VERSION "canboat-NMEA2000-curated"

NS_ :

BS_:

BU_: Vector__XXX
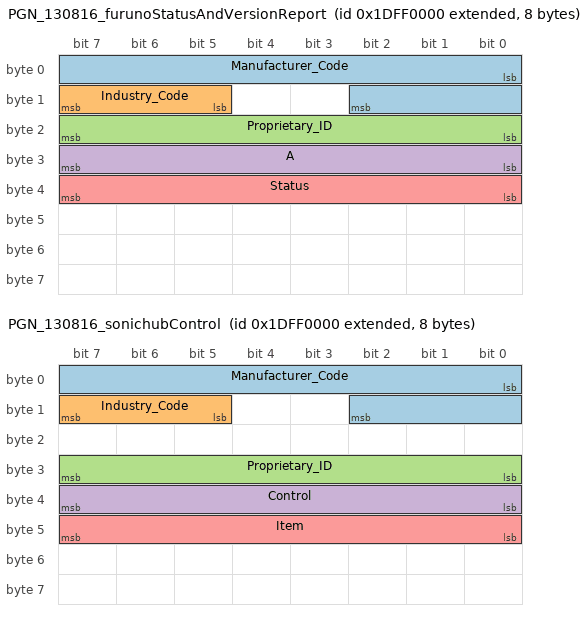
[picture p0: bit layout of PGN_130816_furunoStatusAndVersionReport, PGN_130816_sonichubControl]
BO_ 2650734592 PGN_130816_furunoStatusAndVersionReport: 8 Vector__XXX
 SG_ Manufacturer_Code : 0|11@1+ (1.0,0) [0|2047] "" Vector__XXX
 SG_ Industry_Code : 13|3@1+ (1.0,0) [0|7] "" Vector__XXX
 SG_ Proprietary_ID : 16|8@1+ (1.0,0) [0|255] "" Vector__XXX
 SG_ A : 24|8@1+ (1.0,0) [0|255] "" Vector__XXX
 SG_ Status : 32|8@1+ (1.0,0) [0|255] "" Vector__XXX

BO_ 2650734592 PGN_130816_simradTextMessage: 41 Vector__XXX
 SG_ Manufacturer_Code : 0|11@1+ (1.0,0) [0|2047] "" Vector__XXX
 SG_ Industry_Code : 13|3@1+ (1.0,0) [0|7] "" Vector__XXX
 SG_ Proprietary_ID : 24|8@1+ (1.0,0) [0|255] "" Vector__XXX
 SG_ A : 32|8@1+ (1.0,0) [0|255] "" Vector__XXX
 SG_ B : 40|8@1+ (1.0,0) [0|255] "" Vector__XXX
 SG_ C : 48|8@1+ (1.0,0) [0|255] "" Vector__XXX
 SG_ SID : 56|8@1+ (1.0,0) [0|255] "" Vector__XXX
 SG_ Prio : 64|8@1+ (1.0,0) [0|255] "" Vector__XXX
 SG_ Text : 72|256@1+ (1.0,0) [0|115792089237316195423570985008687907853269984665640564039457584007913129639935] "" Vector__XXX

BO_ 2650734592 PGN_130816_sonichubAlbum: 41 Vector__XXX
 SG_ Manufacturer_Code : 0|11@1+ (1.0,0) [0|2047] "" Vector__XXX
 SG_ Industry_Code : 13|3@1+ (1.0,0) [0|7] "" Vector__XXX
 SG_ Proprietary_ID : 24|8@1+ (1.0,0) [0|255] "" Vector__XXX
 SG_ Control : 32|8@1+ (1.0,0) [0|255] "" Vector__XXX
 SG_ Item : 40|32@1+ (1.0,0) [0|4294967295] "" Vector__XXX
 SG_ Text : 72|256@1+ (1.0,0) [0|115792089237316195423570985008687907853269984665640564039457584007913129639935] "" Vector__XXX

BO_ 2650734592 PGN_130816_sonichubAmRadio: 43 Vector__XXX
 SG_ Manufacturer_Code : 0|11@1+ (1.0,0) [0|2047] "" Vector__XXX
 SG_ Industry_Code : 13|3@1+ (1.0,0) [0|7] "" Vector__XXX
 SG_ Proprietary_ID : 24|8@1+ (1.0,0) [0|255] "" Vector__XXX
 SG_ Control : 32|8@1+ (1.0,0) [0|255] "" Vector__XXX
 SG_ Item : 40|8@1+ (1.0,0) [0|255] "" Vector__XXX
 SG_ Frequency : 48|32@1+ (1.0,0) [0|4294967295] "" Vector__XXX
 SG_ Noise_level : 80|2@1+ (1.0,0) [0|3] "" Vector__XXX
 SG_ Signal_level : 82|4@1+ (1.0,0) [0|15] "" Vector__XXX
 SG_ Text : 88|256@1+ (1.0,0) [0|115792089237316195423570985008687907853269984665640564039457584007913129639935] "" Vector__XXX

BO_ 2650734592 PGN_130816_sonichubArtist: 41 Vector__XXX
 SG_ Manufacturer_Code : 0|11@1+ (1.0,0) [0|2047] "" Vector__XXX
 SG_ Industry_Code : 13|3@1+ (1.0,0) [0|7] "" Vector__XXX
 SG_ Proprietary_ID : 24|8@1+ (1.0,0) [0|255] "" Vector__XXX
 SG_ Control : 32|8@1+ (1.0,0) [0|255] "" Vector__XXX
 SG_ Item : 40|32@1+ (1.0,0) [0|4294967295] "" Vector__XXX
 SG_ Text : 72|256@1+ (1.0,0) [0|115792089237316195423570985008687907853269984665640564039457584007913129639935] "" Vector__XXX

BO_ 2650734592 PGN_130816_sonichubControl: 8 Vector__XXX
 SG_ Manufacturer_Code : 0|11@1+ (1.0,0) [0|2047] "" Vector__XXX
 SG_ Industry_Code : 13|3@1+ (1.0,0) [0|7] "" Vector__XXX
 SG_ Proprietary_ID : 24|8@1+ (1.0,0) [0|255] "" Vector__XXX
 SG_ Control : 32|8@1+ (1.0,0) [0|255] "" Vector__XXX
 SG_ Item : 40|8@1+ (1.0,0) [0|255] "" Vector__XXX

BO_ 2650734592 PGN_130816_sonichubFmRadio: 43 Vector__XXX
 SG_ Manufacturer_Code : 0|11@1+ (1.0,0) [0|2047] "" Vector__XXX
 SG_ Industry_Code : 13|3@1+ (1.0,0) [0|7] "" Vector__XXX
 SG_ Proprietary_ID : 24|8@1+ (1.0,0) [0|255] "" Vector__XXX
 SG_ Control : 32|8@1+ (1.0,0) [0|255] "" Vector__XXX
 SG_ Item : 40|8@1+ (1.0,0) [0|255] "" Vector__XXX
 SG_ Frequency : 48|32@1+ (1.0,0) [0|4294967295] "" Vector__XXX
 SG_ Noise_level : 80|2@1+ (1.0,0) [0|3] "" Vector__XXX
 SG_ Signal_level : 82|4@1+ (1.0,0) [0|15] "" Vector__XXX
 SG_ Text : 88|256@1+ (1.0,0) [0|115792089237316195423570985008687907853269984665640564039457584007913129639935] "" Vector__XXX

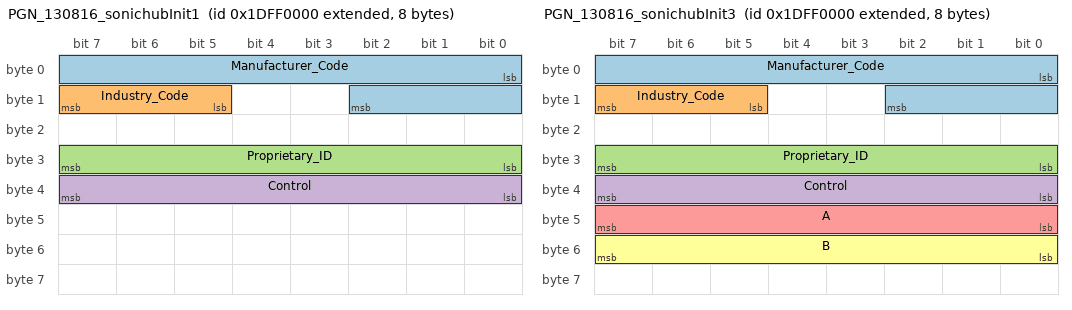
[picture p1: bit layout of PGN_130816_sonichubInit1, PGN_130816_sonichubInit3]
BO_ 2650734592 PGN_130816_sonichubInit1: 8 Vector__XXX
 SG_ Manufacturer_Code : 0|11@1+ (1.0,0) [0|2047] "" Vector__XXX
 SG_ Industry_Code : 13|3@1+ (1.0,0) [0|7] "" Vector__XXX
 SG_ Proprietary_ID : 24|8@1+ (1.0,0) [0|255] "" Vector__XXX
 SG_ Control : 32|8@1+ (1.0,0) [0|255] "" Vector__XXX

BO_ 2650734592 PGN_130816_sonichubInit2: 9 Vector__XXX
 SG_ Manufacturer_Code : 0|11@1+ (1.0,0) [0|2047] "" Vector__XXX
 SG_ Industry_Code : 13|3@1+ (1.0,0) [0|7] "" Vector__XXX
 SG_ Proprietary_ID : 24|8@1+ (1.0,0) [0|255] "" Vector__XXX
 SG_ Control : 32|8@1+ (1.0,0) [0|255] "" Vector__XXX
 SG_ A : 40|16@1+ (1.0,0) [0|65535] "" Vector__XXX
 SG_ B : 56|16@1+ (1.0,0) [0|65535] "" Vector__XXX

BO_ 2650734592 PGN_130816_sonichubInit3: 8 Vector__XXX
 SG_ Manufacturer_Code : 0|11@1+ (1.0,0) [0|2047] "" Vector__XXX
 SG_ Industry_Code : 13|3@1+ (1.0,0) [0|7] "" Vector__XXX
 SG_ Proprietary_ID : 24|8@1+ (1.0,0) [0|255] "" Vector__XXX
 SG_ Control : 32|8@1+ (1.0,0) [0|255] "" Vector__XXX
 SG_ A : 40|8@1+ (1.0,0) [0|255] "" Vector__XXX
 SG_ B : 48|8@1+ (1.0,0) [0|255] "" Vector__XXX

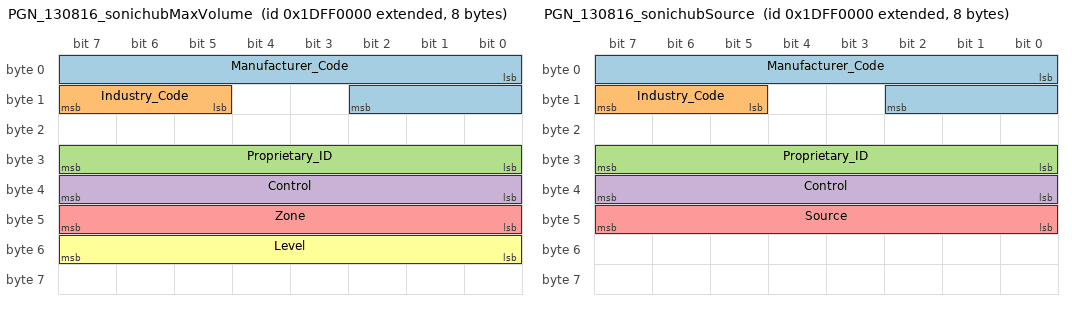
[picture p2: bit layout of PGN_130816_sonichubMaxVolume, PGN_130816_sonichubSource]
BO_ 2650734592 PGN_130816_sonichubMaxVolume: 8 Vector__XXX
 SG_ Manufacturer_Code : 0|11@1+ (1.0,0) [0|2047] "" Vector__XXX
 SG_ Industry_Code : 13|3@1+ (1.0,0) [0|7] "" Vector__XXX
 SG_ Proprietary_ID : 24|8@1+ (1.0,0) [0|255] "" Vector__XXX
 SG_ Control : 32|8@1+ (1.0,0) [0|255] "" Vector__XXX
 SG_ Zone : 40|8@1+ (1.0,0) [0|255] "" Vector__XXX
 SG_ Level : 48|8@1+ (1.0,0) [0|255] "" Vector__XXX

BO_ 2650734592 PGN_130816_sonichubMenuItem: 44 Vector__XXX
 SG_ Manufacturer_Code : 0|11@1+ (1.0,0) [0|2047] "" Vector__XXX
 SG_ Industry_Code : 13|3@1+ (1.0,0) [0|7] "" Vector__XXX
 SG_ Proprietary_ID : 24|8@1+ (1.0,0) [0|255] "" Vector__XXX
 SG_ Control : 32|8@1+ (1.0,0) [0|255] "" Vector__XXX
 SG_ Item : 40|32@1+ (1.0,0) [0|4294967295] "" Vector__XXX
 SG_ C : 72|8@1+ (1.0,0) [0|255] "" Vector__XXX
 SG_ D : 80|8@1+ (1.0,0) [0|255] "" Vector__XXX
 SG_ E : 88|8@1+ (1.0,0) [0|255] "" Vector__XXX
 SG_ Text : 96|256@1+ (1.0,0) [0|115792089237316195423570985008687907853269984665640564039457584007913129639935] "" Vector__XXX

BO_ 2650734592 PGN_130816_sonichubPlaylist: 23 Vector__XXX
 SG_ Manufacturer_Code : 0|11@1+ (1.0,0) [0|2047] "" Vector__XXX
 SG_ Industry_Code : 13|3@1+ (1.0,0) [0|7] "" Vector__XXX
 SG_ Proprietary_ID : 24|8@1+ (1.0,0) [0|255] "" Vector__XXX
 SG_ Control : 32|8@1+ (1.0,0) [0|255] "" Vector__XXX
 SG_ Item : 40|8@1+ (1.0,0) [0|255] "" Vector__XXX
 SG_ A : 48|8@1+ (1.0,0) [0|255] "" Vector__XXX
 SG_ Current_Track : 56|32@1+ (1.0,0) [0|4294967295] "" Vector__XXX
 SG_ Tracks : 88|32@1+ (1.0,0) [0|4294967295] "" Vector__XXX
 SG_ Length : 120|32@1+ (0.001,0) [0.0|4294967.295] "" Vector__XXX
 SG_ Position_in_track : 152|32@1+ (0.001,0) [0.0|4294967.295] "" Vector__XXX

BO_ 2650734592 PGN_130816_sonichubPosition: 9 Vector__XXX
 SG_ Manufacturer_Code : 0|11@1+ (1.0,0) [0|2047] "" Vector__XXX
 SG_ Industry_Code : 13|3@1+ (1.0,0) [0|7] "" Vector__XXX
 SG_ Proprietary_ID : 24|8@1+ (1.0,0) [0|255] "" Vector__XXX
 SG_ Control : 32|8@1+ (1.0,0) [0|255] "" Vector__XXX
 SG_ Position : 40|32@1+ (0.001,0) [0.0|4294967.295] "" Vector__XXX

BO_ 2650734592 PGN_130816_sonichubSource: 8 Vector__XXX
 SG_ Manufacturer_Code : 0|11@1+ (1.0,0) [0|2047] "" Vector__XXX
 SG_ Industry_Code : 13|3@1+ (1.0,0) [0|7] "" Vector__XXX
 SG_ Proprietary_ID : 24|8@1+ (1.0,0) [0|255] "" Vector__XXX
 SG_ Control : 32|8@1+ (1.0,0) [0|255] "" Vector__XXX
 SG_ Source : 40|8@1+ (1.0,0) [0|255] "" Vector__XXX

BO_ 2650734592 PGN_130816_sonichubSourceList: 39 Vector__XXX
 SG_ Manufacturer_Code : 0|11@1+ (1.0,0) [0|2047] "" Vector__XXX
 SG_ Industry_Code : 13|3@1+ (1.0,0) [0|7] "" Vector__XXX
 SG_ Proprietary_ID : 24|8@1+ (1.0,0) [0|255] "" Vector__XXX
 SG_ Control : 32|8@1+ (1.0,0) [0|255] "" Vector__XXX
 SG_ Source_ID : 40|8@1+ (1.0,0) [0|255] "" Vector__XXX
 SG_ A : 48|8@1+ (1.0,0) [0|255] "" Vector__XXX
 SG_ Text : 56|256@1+ (1.0,0) [0|115792089237316195423570985008687907853269984665640564039457584007913129639935] "" Vector__XXX

BO_ 2650734592 PGN_130816_sonichubTrack: 41 Vector__XXX
 SG_ Manufacturer_Code : 0|11@1+ (1.0,0) [0|2047] "" Vector__XXX
 SG_ Industry_Code : 13|3@1+ (1.0,0) [0|7] "" Vector__XXX
 SG_ Proprietary_ID : 24|8@1+ (1.0,0) [0|255] "" Vector__XXX
 SG_ Control : 32|8@1+ (1.0,0) [0|255] "" Vector__XXX
 SG_ Item : 40|32@1+ (1.0,0) [0|4294967295] "" Vector__XXX
 SG_ Text : 72|256@1+ (1.0,0) [0|115792089237316195423570985008687907853269984665640564039457584007913129639935] "" Vector__XXX

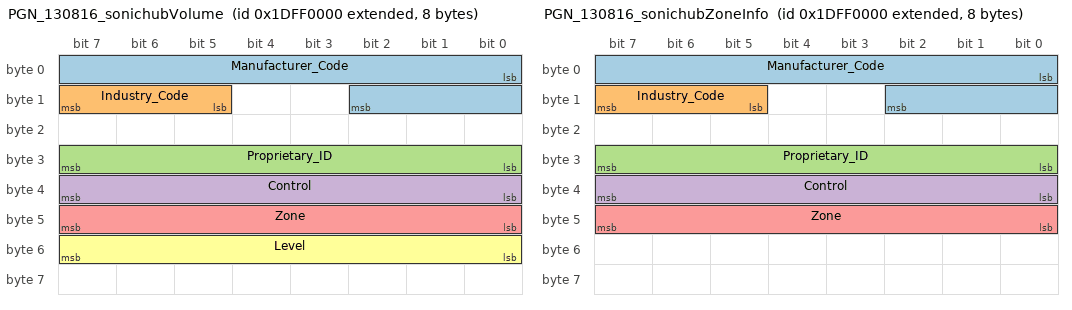
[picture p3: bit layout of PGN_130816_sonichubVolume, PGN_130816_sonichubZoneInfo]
BO_ 2650734592 PGN_130816_sonichubVolume: 8 Vector__XXX
 SG_ Manufacturer_Code : 0|11@1+ (1.0,0) [0|2047] "" Vector__XXX
 SG_ Industry_Code : 13|3@1+ (1.0,0) [0|7] "" Vector__XXX
 SG_ Proprietary_ID : 24|8@1+ (1.0,0) [0|255] "" Vector__XXX
 SG_ Control : 32|8@1+ (1.0,0) [0|255] "" Vector__XXX
 SG_ Zone : 40|8@1+ (1.0,0) [0|255] "" Vector__XXX
 SG_ Level : 48|8@1+ (1.0,0) [0|255] "" Vector__XXX

BO_ 2650734592 PGN_130816_sonichubZoneInfo: 8 Vector__XXX
 SG_ Manufacturer_Code : 0|11@1+ (1.0,0) [0|2047] "" Vector__XXX
 SG_ Industry_Code : 13|3@1+ (1.0,0) [0|7] "" Vector__XXX
 SG_ Proprietary_ID : 24|8@1+ (1.0,0) [0|255] "" Vector__XXX
 SG_ Control : 32|8@1+ (1.0,0) [0|255] "" Vector__XXX
 SG_ Zone : 40|8@1+ (1.0,0) [0|255] "" Vector__XXX

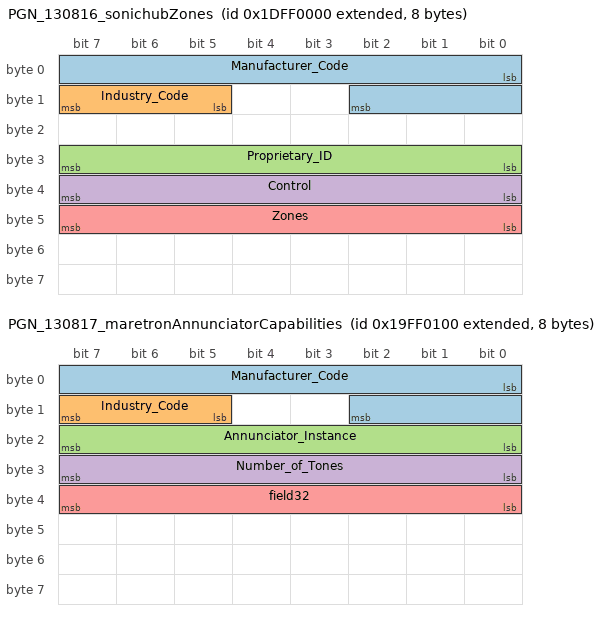
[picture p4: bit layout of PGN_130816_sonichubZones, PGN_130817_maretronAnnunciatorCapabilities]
BO_ 2650734592 PGN_130816_sonichubZones: 8 Vector__XXX
 SG_ Manufacturer_Code : 0|11@1+ (1.0,0) [0|2047] "" Vector__XXX
 SG_ Industry_Code : 13|3@1+ (1.0,0) [0|7] "" Vector__XXX
 SG_ Proprietary_ID : 24|8@1+ (1.0,0) [0|255] "" Vector__XXX
 SG_ Control : 32|8@1+ (1.0,0) [0|255] "" Vector__XXX
 SG_ Zones : 40|8@1+ (1.0,0) [0|255] "" Vector__XXX

BO_ 2583625984 PGN_130817_bepMarineCzoneStatusExtended: 28 Vector__XXX
 SG_ Manufacturer_Code : 0|11@1+ (1.0,0) [0|2047] "" Vector__XXX
 SG_ Industry_Code : 13|3@1+ (1.0,0) [0|7] "" Vector__XXX
 SG_ Page : 16|8@1+ (1.0,0) [0|255] "" Vector__XXX
 SG_ Dipswitch : 24|8@1+ (1.0,0) [0|255] "" Vector__XXX
 SG_ Records : 32|192@1+ (1.0,0) [0|6277101735386680763835789423207666416102355444464034512895] "" Vector__XXX

BO_ 2583625984 PGN_130817_maretronAnnunciatorCapabilities: 8 Vector__XXX
 SG_ Manufacturer_Code : 0|11@1+ (1.0,0) [0|2047] "" Vector__XXX
 SG_ Industry_Code : 13|3@1+ (1.0,0) [0|7] "" Vector__XXX
 SG_ Annunciator_Instance : 16|8@1+ (1.0,0) [0|255] "" Vector__XXX
 SG_ Number_of_Tones : 24|8@1+ (1.0,0) [0|255] "" Vector__XXX
 SG_ field32 : 32|8@1+ (1.0,0) [0|255] "" Vector__XXX

BO_ 2583625984 PGN_130817_sleipnerThrusterStatusPpc520: 17 Vector__XXX
 SG_ Manufacturer_Code : 0|11@1+ (1.0,0) [0|2047] "" Vector__XXX
 SG_ Industry_Code : 13|3@1+ (1.0,0) [0|7] "" Vector__XXX
 SG_ Device_Type : 16|8@1+ (1.0,0) [0|255] "" Vector__XXX
 SG_ A : 24|8@1+ (1.0,0) [0|255] "" Vector__XXX
 SG_ Status : 32|16@1+ (1.0,0) [0|65535] "" Vector__XXX
 SG_ Motor_Temperature : 48|8@1+ (1.0,0) [0|255] "" Vector__XXX
 SG_ Power_Temperature : 56|8@1+ (1.0,0) [0|255] "" Vector__XXX
 SG_ B : 64|8@1+ (1.0,0) [0|255] "" Vector__XXX
 SG_ Motor_Voltage : 72|16@1+ (0.01,0) [0.0|655.35] "" Vector__XXX
 SG_ C : 88|16@1+ (1.0,0) [0|65535] "" Vector__XXX
 SG_ Motor_Current : 104|16@1+ (0.1,0) [0.0|6553.5] "" Vector__XXX
 SG_ Output_Thrust : 120|8@1- (1.0,0) [-128|127] "%" Vector__XXX
 SG_ D : 128|8@1+ (1.0,0) [0|255] "" Vector__XXX

BO_ 2583625984 PGN_130817_sleipnerThrusterStatusPpc820: 17 Vector__XXX
 SG_ Manufacturer_Code : 0|11@1+ (1.0,0) [0|2047] "" Vector__XXX
 SG_ Industry_Code : 13|3@1+ (1.0,0) [0|7] "" Vector__XXX
 SG_ Device_Type : 16|8@1+ (1.0,0) [0|255] "" Vector__XXX
 SG_ A : 24|8@1+ (1.0,0) [0|255] "" Vector__XXX
 SG_ Status : 32|16@1+ (1.0,0) [0|65535] "" Vector__XXX
 SG_ Motor_Temperature : 48|8@1+ (1.0,0) [0|255] "" Vector__XXX
 SG_ Power_Temperature : 56|8@1+ (1.0,0) [0|255] "" Vector__XXX
 SG_ B : 64|8@1+ (1.0,0) [0|255] "" Vector__XXX
 SG_ Motor_Voltage : 72|16@1+ (0.01,0) [0.0|655.35] "" Vector__XXX
 SG_ C : 88|16@1+ (1.0,0) [0|65535] "" Vector__XXX
 SG_ Motor_Current : 104|16@1+ (0.1,0) [0.0|6553.5] "" Vector__XXX
 SG_ Output_Thrust : 120|8@1- (1.0,0) [-128|127] "%" Vector__XXX
 SG_ D : 128|8@1+ (1.0,0) [0|255] "" Vector__XXX

CM_ BO_ 2650734592 "NMEA2000: PGN 130816 - Furuno: Status and Version Report (type: Fast)";
CM_ BO_ 2650734592 "NMEA2000: PGN 130816 - Simrad: Text Message (type: Fast)";
CM_ BO_ 2650734592 "NMEA2000: PGN 130816 - SonicHub: Album (type: Fast)";
CM_ BO_ 2650734592 "NMEA2000: PGN 130816 - SonicHub: AM Radio (type: Fast)";
CM_ BO_ 2650734592 "NMEA2000: PGN 130816 - SonicHub: Artist (type: Fast)";
CM_ BO_ 2650734592 "NMEA2000: PGN 130816 - SonicHub: Control (type: Fast)";
CM_ BO_ 2650734592 "NMEA2000: PGN 130816 - SonicHub: FM Radio (type: Fast)";
CM_ BO_ 2650734592 "NMEA2000: PGN 130816 - SonicHub: Init #1 (type: Fast)";
CM_ BO_ 2650734592 "NMEA2000: PGN 130816 - SonicHub: Init #2 (type: Fast)";
CM_ BO_ 2650734592 "NMEA2000: PGN 130816 - SonicHub: Init #3 (type: Fast)";
CM_ BO_ 2650734592 "NMEA2000: PGN 130816 - SonicHub: Max Volume (type: Fast)";
CM_ BO_ 2650734592 "NMEA2000: PGN 130816 - SonicHub: Menu Item (type: Fast)";
CM_ BO_ 2650734592 "NMEA2000: PGN 130816 - SonicHub: Playlist (type: Fast)";
CM_ BO_ 2650734592 "NMEA2000: PGN 130816 - SonicHub: Position (type: Fast)";
CM_ BO_ 2650734592 "NMEA2000: PGN 130816 - SonicHub: Source (type: Fast)";
CM_ BO_ 2650734592 "NMEA2000: PGN 130816 - SonicHub: Source List (type: Fast)";
CM_ BO_ 2650734592 "NMEA2000: PGN 130816 - SonicHub: Track (type: Fast)";
CM_ BO_ 2650734592 "NMEA2000: PGN 130816 - SonicHub: Volume (type: Fast)";
CM_ BO_ 2650734592 "NMEA2000: PGN 130816 - SonicHub: Zone info (type: Fast)";
CM_ BO_ 2650734592 "NMEA2000: PGN 130816 - SonicHub: Zones (type: Fast)";
CM_ BO_ 2583625984 "NMEA2000: PGN 130817 - BEP Marine: CZone Status Extended (type: Fast)";
CM_ BO_ 2583625984 "NMEA2000: PGN 130817 - Maretron: Annunciator Capabilities (type: Fast)";
CM_ BO_ 2583625984 "NMEA2000: PGN 130817 - Sleipner: PPC520 Thruster Status (type: Fast)";
CM_ BO_ 2583625984 "NMEA2000: PGN 130817 - Sleipner: PPC820 Thruster Status (type: Fast)";
CM_ SG_ 2650734592 Manufacturer_Code "Furuno; canboat type: LOOKUP";
CM_ SG_ 2650734592 Industry_Code "Marine Industry; canboat type: LOOKUP";
CM_ SG_ 2650734592 Proprietary_ID "Version Report; canboat type: UINT8";
CM_ SG_ 2650734592 A "canboat type: UINT8";
CM_ SG_ 2650734592 Status "canboat type: STRING_LAU";
CM_ SG_ 2650734592 Manufacturer_Code "Simrad; canboat type: LOOKUP";
CM_ SG_ 2650734592 Industry_Code "Marine Industry; canboat type: LOOKUP";
CM_ SG_ 2650734592 Proprietary_ID "Text; canboat type: LOOKUP";
CM_ SG_ 2650734592 A "canboat type: UINT8";
CM_ SG_ 2650734592 B "canboat type: UINT8";
CM_ SG_ 2650734592 C "canboat type: UINT8";
CM_ SG_ 2650734592 SID "canboat type: UINT8";
CM_ SG_ 2650734592 Prio "canboat type: UINT8";
CM_ SG_ 2650734592 Text "canboat type: STRING_FIX";
CM_ SG_ 2650734592 Manufacturer_Code "Navico; canboat type: LOOKUP";
CM_ SG_ 2650734592 Industry_Code "Marine Industry; canboat type: LOOKUP";
CM_ SG_ 2650734592 Proprietary_ID "Album; canboat type: LOOKUP";
CM_ SG_ 2650734592 Control "canboat type: LOOKUP";
CM_ SG_ 2650734592 Item "canboat type: UINT32";
CM_ SG_ 2650734592 Text "canboat type: STRING_LZ";
CM_ SG_ 2650734592 Manufacturer_Code "Navico; canboat type: LOOKUP";
CM_ SG_ 2650734592 Industry_Code "Marine Industry; canboat type: LOOKUP";
CM_ SG_ 2650734592 Proprietary_ID "AM Radio; canboat type: LOOKUP";
CM_ SG_ 2650734592 Control "canboat type: LOOKUP";
CM_ SG_ 2650734592 Item "canboat type: LOOKUP";
CM_ SG_ 2650734592 Frequency "canboat type: RADIO_FREQUENCY_UFIX32";
CM_ SG_ 2650734592 Noise_level "canboat type: UNSIGNED_INTEGER";
CM_ SG_ 2650734592 Signal_level "canboat type: UNSIGNED_INTEGER";
CM_ SG_ 2650734592 Text "canboat type: STRING_LZ";
CM_ SG_ 2650734592 Manufacturer_Code "Navico; canboat type: LOOKUP";
CM_ SG_ 2650734592 Industry_Code "Marine Industry; canboat type: LOOKUP";
CM_ SG_ 2650734592 Proprietary_ID "Artist; canboat type: LOOKUP";
CM_ SG_ 2650734592 Control "canboat type: LOOKUP";
CM_ SG_ 2650734592 Item "canboat type: UINT32";
CM_ SG_ 2650734592 Text "canboat type: STRING_LZ";
CM_ SG_ 2650734592 Manufacturer_Code "Navico; canboat type: LOOKUP";
CM_ SG_ 2650734592 Industry_Code "Marine Industry; canboat type: LOOKUP";
CM_ SG_ 2650734592 Proprietary_ID "Control; canboat type: LOOKUP";
CM_ SG_ 2650734592 Control "canboat type: LOOKUP";
CM_ SG_ 2650734592 Item "canboat type: LOOKUP";
CM_ SG_ 2650734592 Manufacturer_Code "Navico; canboat type: LOOKUP";
CM_ SG_ 2650734592 Industry_Code "Marine Industry; canboat type: LOOKUP";
CM_ SG_ 2650734592 Proprietary_ID "FM Radio; canboat type: LOOKUP";
CM_ SG_ 2650734592 Control "canboat type: LOOKUP";
CM_ SG_ 2650734592 Item "canboat type: LOOKUP";
CM_ SG_ 2650734592 Frequency "canboat type: RADIO_FREQUENCY_UFIX32";
CM_ SG_ 2650734592 Noise_level "canboat type: UNSIGNED_INTEGER";
CM_ SG_ 2650734592 Signal_level "canboat type: UNSIGNED_INTEGER";
CM_ SG_ 2650734592 Text "canboat type: STRING_LZ";
CM_ SG_ 2650734592 Manufacturer_Code "Navico; canboat type: LOOKUP";
CM_ SG_ 2650734592 Industry_Code "Marine Industry; canboat type: LOOKUP";
CM_ SG_ 2650734592 Proprietary_ID "Init #1; canboat type: LOOKUP";
CM_ SG_ 2650734592 Control "canboat type: LOOKUP";
CM_ SG_ 2650734592 Manufacturer_Code "Navico; canboat type: LOOKUP";
CM_ SG_ 2650734592 Industry_Code "Marine Industry; canboat type: LOOKUP";
CM_ SG_ 2650734592 Proprietary_ID "Init #2; canboat type: LOOKUP";
CM_ SG_ 2650734592 Control "canboat type: LOOKUP";
CM_ SG_ 2650734592 A "canboat type: UINT16";
CM_ SG_ 2650734592 B "canboat type: UINT16";
CM_ SG_ 2650734592 Manufacturer_Code "Navico; canboat type: LOOKUP";
CM_ SG_ 2650734592 Industry_Code "Marine Industry; canboat type: LOOKUP";
CM_ SG_ 2650734592 Proprietary_ID "Init #3; canboat type: LOOKUP";
CM_ SG_ 2650734592 Control "canboat type: LOOKUP";
CM_ SG_ 2650734592 A "canboat type: UINT8";
CM_ SG_ 2650734592 B "canboat type: UINT8";
CM_ SG_ 2650734592 Manufacturer_Code "Navico; canboat type: LOOKUP";
CM_ SG_ 2650734592 Industry_Code "Marine Industry; canboat type: LOOKUP";
CM_ SG_ 2650734592 Proprietary_ID "Max Volume; canboat type: LOOKUP";
CM_ SG_ 2650734592 Control "canboat type: LOOKUP";
CM_ SG_ 2650734592 Zone "canboat type: UINT8";
CM_ SG_ 2650734592 Level "canboat type: UINT8";
CM_ SG_ 2650734592 Manufacturer_Code "Navico; canboat type: LOOKUP";
CM_ SG_ 2650734592 Industry_Code "Marine Industry; canboat type: LOOKUP";
CM_ SG_ 2650734592 Proprietary_ID "Menu Item; canboat type: LOOKUP";
CM_ SG_ 2650734592 Control "canboat type: LOOKUP";
CM_ SG_ 2650734592 Item "canboat type: UINT32";
CM_ SG_ 2650734592 C "canboat type: UINT8";
CM_ SG_ 2650734592 D "canboat type: UINT8";
CM_ SG_ 2650734592 E "canboat type: UINT8";
CM_ SG_ 2650734592 Text "canboat type: STRING_LZ";
CM_ SG_ 2650734592 Manufacturer_Code "Navico; canboat type: LOOKUP";
CM_ SG_ 2650734592 Industry_Code "Marine Industry; canboat type: LOOKUP";
CM_ SG_ 2650734592 Proprietary_ID "Playlist; canboat type: LOOKUP";
CM_ SG_ 2650734592 Control "canboat type: LOOKUP";
CM_ SG_ 2650734592 Item "canboat type: LOOKUP";
CM_ SG_ 2650734592 A "canboat type: UINT8";
CM_ SG_ 2650734592 Current_Track "canboat type: UINT32";
CM_ SG_ 2650734592 Tracks "canboat type: UINT32";
CM_ SG_ 2650734592 Length "canboat type: DURATION_UFIX32_MS";
CM_ SG_ 2650734592 Position_in_track "canboat type: DURATION_UFIX32_MS";
CM_ SG_ 2650734592 Manufacturer_Code "Navico; canboat type: LOOKUP";
CM_ SG_ 2650734592 Industry_Code "Marine Industry; canboat type: LOOKUP";
CM_ SG_ 2650734592 Proprietary_ID "Position; canboat type: LOOKUP";
CM_ SG_ 2650734592 Control "canboat type: LOOKUP";
CM_ SG_ 2650734592 Position "canboat type: DURATION_UFIX32_MS";
CM_ SG_ 2650734592 Manufacturer_Code "Navico; canboat type: LOOKUP";
CM_ SG_ 2650734592 Industry_Code "Marine Industry; canboat type: LOOKUP";
CM_ SG_ 2650734592 Proprietary_ID "Source; canboat type: LOOKUP";
CM_ SG_ 2650734592 Control "canboat type: LOOKUP";
CM_ SG_ 2650734592 Source "canboat type: LOOKUP";
CM_ SG_ 2650734592 Manufacturer_Code "Navico; canboat type: LOOKUP";
CM_ SG_ 2650734592 Industry_Code "Marine Industry; canboat type: LOOKUP";
CM_ SG_ 2650734592 Proprietary_ID "Source List; canboat type: LOOKUP";
CM_ SG_ 2650734592 Control "canboat type: LOOKUP";
CM_ SG_ 2650734592 Source_ID "canboat type: UINT8";
CM_ SG_ 2650734592 A "canboat type: UINT8";
CM_ SG_ 2650734592 Text "canboat type: STRING_LZ";
CM_ SG_ 2650734592 Manufacturer_Code "Navico; canboat type: LOOKUP";
CM_ SG_ 2650734592 Industry_Code "Marine Industry; canboat type: LOOKUP";
CM_ SG_ 2650734592 Proprietary_ID "Track; canboat type: LOOKUP";
CM_ SG_ 2650734592 Control "canboat type: LOOKUP";
CM_ SG_ 2650734592 Item "canboat type: UINT32";
CM_ SG_ 2650734592 Text "canboat type: STRING_LZ";
CM_ SG_ 2650734592 Manufacturer_Code "Navico; canboat type: LOOKUP";
CM_ SG_ 2650734592 Industry_Code "Marine Industry; canboat type: LOOKUP";
CM_ SG_ 2650734592 Proprietary_ID "Volume; canboat type: LOOKUP";
CM_ SG_ 2650734592 Control "canboat type: LOOKUP";
CM_ SG_ 2650734592 Zone "canboat type: UINT8";
CM_ SG_ 2650734592 Level "canboat type: UINT8";
CM_ SG_ 2650734592 Manufacturer_Code "Navico; canboat type: LOOKUP";
CM_ SG_ 2650734592 Industry_Code "Marine Industry; canboat type: LOOKUP";
CM_ SG_ 2650734592 Proprietary_ID "Zone Info; canboat type: LOOKUP";
CM_ SG_ 2650734592 Control "canboat type: LOOKUP";
CM_ SG_ 2650734592 Zone "canboat type: UINT8";
CM_ SG_ 2650734592 Manufacturer_Code "Navico; canboat type: LOOKUP";
CM_ SG_ 2650734592 Industry_Code "Marine Industry; canboat type: LOOKUP";
CM_ SG_ 2650734592 Proprietary_ID "Zones; canboat type: LOOKUP";
CM_ SG_ 2650734592 Control "canboat type: LOOKUP";
CM_ SG_ 2650734592 Zones "canboat type: UINT8";
CM_ SG_ 2583625984 Manufacturer_Code "BEP Marine; canboat type: LOOKUP";
CM_ SG_ 2583625984 Industry_Code "Marine Industry; canboat type: LOOKUP";
CM_ SG_ 2583625984 Page "Observed = 0x01; possibly a status-page selector; canboat type: UINT8";
CM_ SG_ 2583625984 Dipswitch "canboat type: UINT8";
CM_ SG_ 2583625984 Records "N records of 3 bytes each, N = (payload_length - 4) / 3, capped at 8; canboat type: BINARY";
CM_ SG_ 2583625984 Manufacturer_Code "Maretron; canboat type: LOOKUP";
CM_ SG_ 2583625984 Industry_Code "Marine Industry; canboat type: LOOKUP";
CM_ SG_ 2583625984 Annunciator_Instance "canboat type: UINT8";
CM_ SG_ 2583625984 Number_of_Tones "canboat type: UINT8";
CM_ SG_ 2583625984 field32 "canboat type: NUMBER";
CM_ SG_ 2583625984 Manufacturer_Code "Sleipner Motor; canboat type: LOOKUP";
CM_ SG_ 2583625984 Industry_Code "Marine Industry; canboat type: LOOKUP";
CM_ SG_ 2583625984 Device_Type "PPC520; canboat type: UINT8";
CM_ SG_ 2583625984 A "canboat type: UINT8";
CM_ SG_ 2583625984 Status "canboat type: BINARY";
CM_ SG_ 2583625984 Motor_Temperature "Temperature in degrees Celsius; canboat type: UNSIGNED_INTEGER";
CM_ SG_ 2583625984 Power_Temperature "Temperature in degrees Celsius; canboat type: UNSIGNED_INTEGER";
CM_ SG_ 2583625984 B "canboat type: UINT8";
CM_ SG_ 2583625984 Motor_Voltage "canboat type: VOLTAGE_UFIX16_10MV";
CM_ SG_ 2583625984 C "canboat type: BINARY";
CM_ SG_ 2583625984 Motor_Current "canboat type: CURRENT_UFIX16_DA";
CM_ SG_ 2583625984 Output_Thrust "Reported thrust, -100 to 100%; the sign is the direction; canboat type: PERCENTAGE_INT8";
CM_ SG_ 2583625984 D "canboat type: UINT8";
CM_ SG_ 2583625984 Manufacturer_Code "Sleipner Motor; canboat type: LOOKUP";
CM_ SG_ 2583625984 Industry_Code "Marine Industry; canboat type: LOOKUP";
CM_ SG_ 2583625984 Device_Type "PPC820; canboat type: UINT8";
CM_ SG_ 2583625984 A "canboat type: UINT8";
CM_ SG_ 2583625984 Status "canboat type: BINARY";
CM_ SG_ 2583625984 Motor_Temperature "Temperature in degrees Celsius; canboat type: UNSIGNED_INTEGER";
CM_ SG_ 2583625984 Power_Temperature "Temperature in degrees Celsius; canboat type: UNSIGNED_INTEGER";
CM_ SG_ 2583625984 B "canboat type: UINT8";
CM_ SG_ 2583625984 Motor_Voltage "canboat type: VOLTAGE_UFIX16_10MV";
CM_ SG_ 2583625984 C "canboat type: BINARY";
CM_ SG_ 2583625984 Motor_Current "canboat type: CURRENT_UFIX16_DA";
CM_ SG_ 2583625984 Output_Thrust "Reported thrust, -100 to 100%; the sign is the direction; canboat type: PERCENTAGE_INT8";
CM_ SG_ 2583625984 D "canboat type: UINT8";
VAL_ 2650734592 Manufacturer_Code 69 "ARKS Enterprises" 78 "FW Murphy/Enovation Controls" 80 "Twin Disc" 85 "Kohler Power Systems" 88 "Hemisphere GPS" 135 "Airmar" 137 "Maretron" 140 "Lowrance" 144 "Mercury Marine" 147 "Nautibus Electronic" 148 "Blue Water Data" 154 "Westerbeke" 157 "ISSPRO" 161 "Offshore Systems (UK)" 163 "Evinrude/BRP" 165 "CPAC Systems" 168 "Xantrex Technology" 169 "Marlin Technologies" 172 "Yanmar Marine" 174 "Volvo Penta" 176 "Carling Technologies Inc. (Moritz Aerospace)" 185 "Beede Instruments" 192 "Floscan Instrument" 193 "Nobeltec" 198 "Mystic Valley Communications" 199 "Actia" 201 "Disenos Y Technologia" 211 "Digital Switching Systems" 215 "Xintex/Atena" 224 "EMMI NETWORK" 228 "ZF" 229 "Garmin" 233 "Yacht Monitoring Solutions" 235 "Sailormade Marine Telemetry/Tetra Technology" 243 "Eride" 257 "Honda Motor" 272 "Groco" 273 "Actisense" 274 "Amphenol LTW Technology" 275 "Navico" 283 "Hamilton Jet" 285 "Sea Recovery" 286 "Coelmo SRL Italy" 295 "BEP Marine" 304 "Empir Bus" 305 "NovAtel" 306 "Sleipner Motor" 307 "MBW Technologies" 315 "ICOM" 328 "Qwerty" 329 "Dief" 341 "Boening Automationstechnologie" 345 "Korean Maritime University" 351 "Thrane and Thrane" 355 "Mastervolt" 356 "Fischer Panda Generators" 358 "Victron Energy" 370 "Rolls Royce Marine" 373 "Electronic Design" 374 "Northern Lights" 378 "Glendinning" 381 "B & G" 384 "Rose Point Navigation Systems" 385 "Johnson Outdoors Marine Electronics Inc Geonav" 394 "Capi 2" 396 "Beyond Measure" 400 "Livorsi Marine" 404 "ComNav" 409 "Chetco" 419 "Fusion Electronics" 421 "Standard Horizon" 422 "True Heading" 426 "Egersund Marine Electronics" 427 "em-trak Marine Electronics" 431 "Tohatsu Co, JP" 437 "Digital Yacht" 438 "Comar Systems Limited" 440 "Cummins" 443 "VDO (aka Continental-Corporation)" 451 "Parker Hannifin aka Village Marine Tech" 459 "Alltek Marine Electronics" 460 "SAN GIORGIO S.E.I.N" 466 "Veethree Electronics & Marine" 470 "SI-TEX Marine Electronics" 471 "Sea Cross Marine" 475 "GME aka Standard Communications" 476 "Humminbird Marine Electronics" 478 "Ocean Sat" 481 "Chetco Digital Instruments" 493 "Watcheye" 499 "Lcj Capteurs" 502 "Attwood Marine" 503 "Naviop S.R.L." 504 "Vesper Marine" 510 "Marinesoft" 513 "Simarine" 517 "NoLand Engineering" 518 "Transas USA" 529 "National Instruments Korea" 530 "National Marine Electronics Association" 532 "Onwa Marine" 540 "Webasto" 571 "Marinecraft (South Korea)" 573 "McMurdo Group aka Orolia" 578 "Advansea" 579 "KVH" 580 "San Jose Technology" 583 "Yacht Control" 586 "Suzuki Motor" 591 "US Coast Guard" 595 "Ship Module aka Customware" 600 "Aquatic AV" 605 "Aventics" 606 "Intellian" 612 "SamwonIT" 614 "Arlt Tecnologies" 637 "Bavaria Yachts" 641 "Diverse Yacht Services" 644 "Wema U.S.A dba KUS" 658 "Shenzhen Jiuzhou Himunication" 688 "Rockford" 699 "Harman International" 704 "JL Audio" 708 "Lars Thrane" 715 "Autonnic" 717 "Yacht Devices" 734 "REAP Systems" 735 "AEM Performance Electronics" 739 "LxNav" 741 "Littelfuse, Inc (formerly Carling Technologies)" 743 "DaeMyung" 744 "Woosung" 748 "ISOTTA IFRA srl" 773 "Clarion US" 776 "HMI Systems" 777 "Ocean Signal" 778 "Seakeeper" 781 "Poly Planar" 785 "Fischer Panda DE" 795 "Broyda Industries" 796 "Canadian Automotive" 797 "Tides Marine" 798 "Lumishore" 799 "Still Water Designs and Audio" 802 "BJ Technologies (Beneteau)" 803 "Gill Sensors" 811 "Blue Water Desalination" 815 "FLIR" 824 "Undheim Systems" 826 "Lewmar" 838 "TeamSurv" 844 "Fell Marine" 847 "Oceanvolt" 862 "Prospec" 868 "Data Panel" 890 "L3 Technologies" 894 "Rhodan Marine Systems" 896 "Nexfour Solutions" 905 "ASA Electronics" 909 "Marines Co (South Korea)" 911 "Nautic-on" 917 "Sentinel" 929 "JL Marine Systems" 930 "Ecotronix" 944 "Zontisa Marine" 951 "EXOR International" 962 "Timbolier Industries" 963 "TJC Micro" 968 "Cox Powertrain" 969 "Blue Seas" 981 "Kobelt Manufacturing" 992 "Blue Ocean IOT" 997 "Xenta Systems" 999 "Signal K" 1004 "Ultraflex" 1008 "Lintest SmartBoat" 1011 "Soundmax" 1020 "Team Italia Marine (Onyx Marine Automation s.r.l)" 1021 "Entratech" 1022 "ITC" 1029 "The Marine Guardian" 1047 "Sonic" 1051 "ProNav" 1053 "Vetus Maxwell INC." 1056 "Lithium Pros" 1059 "Boatrax" 1062 "Marol Co ltd" 1065 "CALYPSO Instruments" 1066 "Spot Zero Water" 1069 "Lithionics Battery" 1070 "Quick-teck Electronics" 1075 "Uniden America" 1083 "Nauticoncept" 1084 "Shadow-Caster LED lighting" 1085 "Wet Sounds" 1088 "E-T-A Circuit Breakers" 1092 "Scheiber" 1100 "Smart Yachts International Limited" 1109 "Dockmate" 1114 "Bobs Machine" 1118 "L3Harris ASV" 1119 "Balmar" 1120 "Elettromedia" 1127 "Electromaax" 1140 "Across Oceans Systems" 1145 "Kiwi Yachting" 1150 "BSB Artificial Intelligence" 1151 "Orca Technologies" 1154 "TBS Electronics" 1158 "Technoton Electroics" 1160 "MG Energy Systems" 1169 "Sea Machine Robotics" 1171 "Vista Manufacturing" 1183 "Zipwake" 1186 "Sailmon" 1192 "Airmoniq Pro Kft" 1194 "Sierra Marine" 1200 "Xinuo Information Technology (Xiamen)" 1218 "Septentrio" 1233 "NKE Marine Electronics" 1238 "SuperTrack Aps" 1239 "Honda Electronics" 1245 "Raritan Engineering" 1249 "Integrated Power Solutions AG" 1260 "Interactive Technologies" 1283 "LTG-Tech" 1299 "Energy Solutions (UK)" 1300 "WATT Fuel Cell" 1302 "Pro Mainer" 1305 "Dragonfly Energy" 1306 "Koden Electronics" 1311 "Humphree" 1316 "Hinkley Yachts" 1317 "Global Marine Management GmbH (GMM)" 1320 "Triskel Marine" 1330 "Warwick Control Technologies" 1331 "Dolphin Charger" 1337 "Barnacle Systems" 1348 "Radian IoT" 1353 "Ocean LED Marine" 1359 "BluNav" 1361 "OVA (Nantong Saiyang Electronics Co., Ltd)" 1368 "RAD Propulsion" 1369 "Electric Yacht" 1372 "Elco Motor Yachts" 1384 "Tecnoseal Foundry S.r.l" 1385 "Pro Charging Systems" 1389 "EVEX" 1398 "Gobius Sensor Technology" 1403 "Arco Marine" 1408 "Lenco Marine" 1413 "Naocontrol" 1417 "Revatek" 1438 "Aeolionics" 1439 "PredictWind" 1440 "Egis Mobile Electric" 1445 "Starboard Yacht Group" 1446 "Roswell Marine" 1451 "ePropulsion (Guangdong ePropulsion Technology Ltd.)" 1452 "Micro-Air" 1453 "Vital Battery" 1458 "Ride Controller" 1460 "Tocaro Blue" 1461 "Vanquish Yachts" 1471 "FT Technologies" 1478 "Alps Alpine" 1481 "E-Force Marine" 1482 "CMC Marine" 1483 "Nanjing Sandemarine Information Technology" 1850 "Teleflex Marine (SeaStar Solutions)" 1851 "Raymarine" 1852 "Navionics" 1853 "Japan Radio" 1854 "Northstar Technologies" 1855 "Furuno" 1856 "Trimble" 1857 "Simrad" 1858 "Litton" 1859 "Kvasar" 1860 "MMP" 1861 "Vector Cantech" 1862 "Yamaha Marine" 1863 "Faria Instruments" ;
VAL_ 2650734592 Industry_Code 0 "Global" 1 "Highway" 2 "Agriculture" 3 "Construction" 4 "Marine Industry" 5 "Industrial" ;
VAL_ 2650734592 Manufacturer_Code 69 "ARKS Enterprises" 78 "FW Murphy/Enovation Controls" 80 "Twin Disc" 85 "Kohler Power Systems" 88 "Hemisphere GPS" 135 "Airmar" 137 "Maretron" 140 "Lowrance" 144 "Mercury Marine" 147 "Nautibus Electronic" 148 "Blue Water Data" 154 "Westerbeke" 157 "ISSPRO" 161 "Offshore Systems (UK)" 163 "Evinrude/BRP" 165 "CPAC Systems" 168 "Xantrex Technology" 169 "Marlin Technologies" 172 "Yanmar Marine" 174 "Volvo Penta" 176 "Carling Technologies Inc. (Moritz Aerospace)" 185 "Beede Instruments" 192 "Floscan Instrument" 193 "Nobeltec" 198 "Mystic Valley Communications" 199 "Actia" 201 "Disenos Y Technologia" 211 "Digital Switching Systems" 215 "Xintex/Atena" 224 "EMMI NETWORK" 228 "ZF" 229 "Garmin" 233 "Yacht Monitoring Solutions" 235 "Sailormade Marine Telemetry/Tetra Technology" 243 "Eride" 257 "Honda Motor" 272 "Groco" 273 "Actisense" 274 "Amphenol LTW Technology" 275 "Navico" 283 "Hamilton Jet" 285 "Sea Recovery" 286 "Coelmo SRL Italy" 295 "BEP Marine" 304 "Empir Bus" 305 "NovAtel" 306 "Sleipner Motor" 307 "MBW Technologies" 315 "ICOM" 328 "Qwerty" 329 "Dief" 341 "Boening Automationstechnologie" 345 "Korean Maritime University" 351 "Thrane and Thrane" 355 "Mastervolt" 356 "Fischer Panda Generators" 358 "Victron Energy" 370 "Rolls Royce Marine" 373 "Electronic Design" 374 "Northern Lights" 378 "Glendinning" 381 "B & G" 384 "Rose Point Navigation Systems" 385 "Johnson Outdoors Marine Electronics Inc Geonav" 394 "Capi 2" 396 "Beyond Measure" 400 "Livorsi Marine" 404 "ComNav" 409 "Chetco" 419 "Fusion Electronics" 421 "Standard Horizon" 422 "True Heading" 426 "Egersund Marine Electronics" 427 "em-trak Marine Electronics" 431 "Tohatsu Co, JP" 437 "Digital Yacht" 438 "Comar Systems Limited" 440 "Cummins" 443 "VDO (aka Continental-Corporation)" 451 "Parker Hannifin aka Village Marine Tech" 459 "Alltek Marine Electronics" 460 "SAN GIORGIO S.E.I.N" 466 "Veethree Electronics & Marine" 470 "SI-TEX Marine Electronics" 471 "Sea Cross Marine" 475 "GME aka Standard Communications" 476 "Humminbird Marine Electronics" 478 "Ocean Sat" 481 "Chetco Digital Instruments" 493 "Watcheye" 499 "Lcj Capteurs" 502 "Attwood Marine" 503 "Naviop S.R.L." 504 "Vesper Marine" 510 "Marinesoft" 513 "Simarine" 517 "NoLand Engineering" 518 "Transas USA" 529 "National Instruments Korea" 530 "National Marine Electronics Association" 532 "Onwa Marine" 540 "Webasto" 571 "Marinecraft (South Korea)" 573 "McMurdo Group aka Orolia" 578 "Advansea" 579 "KVH" 580 "San Jose Technology" 583 "Yacht Control" 586 "Suzuki Motor" 591 "US Coast Guard" 595 "Ship Module aka Customware" 600 "Aquatic AV" 605 "Aventics" 606 "Intellian" 612 "SamwonIT" 614 "Arlt Tecnologies" 637 "Bavaria Yachts" 641 "Diverse Yacht Services" 644 "Wema U.S.A dba KUS" 658 "Shenzhen Jiuzhou Himunication" 688 "Rockford" 699 "Harman International" 704 "JL Audio" 708 "Lars Thrane" 715 "Autonnic" 717 "Yacht Devices" 734 "REAP Systems" 735 "AEM Performance Electronics" 739 "LxNav" 741 "Littelfuse, Inc (formerly Carling Technologies)" 743 "DaeMyung" 744 "Woosung" 748 "ISOTTA IFRA srl" 773 "Clarion US" 776 "HMI Systems" 777 "Ocean Signal" 778 "Seakeeper" 781 "Poly Planar" 785 "Fischer Panda DE" 795 "Broyda Industries" 796 "Canadian Automotive" 797 "Tides Marine" 798 "Lumishore" 799 "Still Water Designs and Audio" 802 "BJ Technologies (Beneteau)" 803 "Gill Sensors" 811 "Blue Water Desalination" 815 "FLIR" 824 "Undheim Systems" 826 "Lewmar" 838 "TeamSurv" 844 "Fell Marine" 847 "Oceanvolt" 862 "Prospec" 868 "Data Panel" 890 "L3 Technologies" 894 "Rhodan Marine Systems" 896 "Nexfour Solutions" 905 "ASA Electronics" 909 "Marines Co (South Korea)" 911 "Nautic-on" 917 "Sentinel" 929 "JL Marine Systems" 930 "Ecotronix" 944 "Zontisa Marine" 951 "EXOR International" 962 "Timbolier Industries" 963 "TJC Micro" 968 "Cox Powertrain" 969 "Blue Seas" 981 "Kobelt Manufacturing" 992 "Blue Ocean IOT" 997 "Xenta Systems" 999 "Signal K" 1004 "Ultraflex" 1008 "Lintest SmartBoat" 1011 "Soundmax" 1020 "Team Italia Marine (Onyx Marine Automation s.r.l)" 1021 "Entratech" 1022 "ITC" 1029 "The Marine Guardian" 1047 "Sonic" 1051 "ProNav" 1053 "Vetus Maxwell INC." 1056 "Lithium Pros" 1059 "Boatrax" 1062 "Marol Co ltd" 1065 "CALYPSO Instruments" 1066 "Spot Zero Water" 1069 "Lithionics Battery" 1070 "Quick-teck Electronics" 1075 "Uniden America" 1083 "Nauticoncept" 1084 "Shadow-Caster LED lighting" 1085 "Wet Sounds" 1088 "E-T-A Circuit Breakers" 1092 "Scheiber" 1100 "Smart Yachts International Limited" 1109 "Dockmate" 1114 "Bobs Machine" 1118 "L3Harris ASV" 1119 "Balmar" 1120 "Elettromedia" 1127 "Electromaax" 1140 "Across Oceans Systems" 1145 "Kiwi Yachting" 1150 "BSB Artificial Intelligence" 1151 "Orca Technologies" 1154 "TBS Electronics" 1158 "Technoton Electroics" 1160 "MG Energy Systems" 1169 "Sea Machine Robotics" 1171 "Vista Manufacturing" 1183 "Zipwake" 1186 "Sailmon" 1192 "Airmoniq Pro Kft" 1194 "Sierra Marine" 1200 "Xinuo Information Technology (Xiamen)" 1218 "Septentrio" 1233 "NKE Marine Electronics" 1238 "SuperTrack Aps" 1239 "Honda Electronics" 1245 "Raritan Engineering" 1249 "Integrated Power Solutions AG" 1260 "Interactive Technologies" 1283 "LTG-Tech" 1299 "Energy Solutions (UK)" 1300 "WATT Fuel Cell" 1302 "Pro Mainer" 1305 "Dragonfly Energy" 1306 "Koden Electronics" 1311 "Humphree" 1316 "Hinkley Yachts" 1317 "Global Marine Management GmbH (GMM)" 1320 "Triskel Marine" 1330 "Warwick Control Technologies" 1331 "Dolphin Charger" 1337 "Barnacle Systems" 1348 "Radian IoT" 1353 "Ocean LED Marine" 1359 "BluNav" 1361 "OVA (Nantong Saiyang Electronics Co., Ltd)" 1368 "RAD Propulsion" 1369 "Electric Yacht" 1372 "Elco Motor Yachts" 1384 "Tecnoseal Foundry S.r.l" 1385 "Pro Charging Systems" 1389 "EVEX" 1398 "Gobius Sensor Technology" 1403 "Arco Marine" 1408 "Lenco Marine" 1413 "Naocontrol" 1417 "Revatek" 1438 "Aeolionics" 1439 "PredictWind" 1440 "Egis Mobile Electric" 1445 "Starboard Yacht Group" 1446 "Roswell Marine" 1451 "ePropulsion (Guangdong ePropulsion Technology Ltd.)" 1452 "Micro-Air" 1453 "Vital Battery" 1458 "Ride Controller" 1460 "Tocaro Blue" 1461 "Vanquish Yachts" 1471 "FT Technologies" 1478 "Alps Alpine" 1481 "E-Force Marine" 1482 "CMC Marine" 1483 "Nanjing Sandemarine Information Technology" 1850 "Teleflex Marine (SeaStar Solutions)" 1851 "Raymarine" 1852 "Navionics" 1853 "Japan Radio" 1854 "Northstar Technologies" 1855 "Furuno" 1856 "Trimble" 1857 "Simrad" 1858 "Litton" 1859 "Kvasar" 1860 "MMP" 1861 "Vector Cantech" 1862 "Yamaha Marine" 1863 "Faria Instruments" ;
VAL_ 2650734592 Industry_Code 0 "Global" 1 "Highway" 2 "Agriculture" 3 "Construction" 4 "Marine Industry" 5 "Industrial" ;
VAL_ 2650734592 Proprietary_ID 50 "Text" ;
VAL_ 2650734592 Manufacturer_Code 69 "ARKS Enterprises" 78 "FW Murphy/Enovation Controls" 80 "Twin Disc" 85 "Kohler Power Systems" 88 "Hemisphere GPS" 135 "Airmar" 137 "Maretron" 140 "Lowrance" 144 "Mercury Marine" 147 "Nautibus Electronic" 148 "Blue Water Data" 154 "Westerbeke" 157 "ISSPRO" 161 "Offshore Systems (UK)" 163 "Evinrude/BRP" 165 "CPAC Systems" 168 "Xantrex Technology" 169 "Marlin Technologies" 172 "Yanmar Marine" 174 "Volvo Penta" 176 "Carling Technologies Inc. (Moritz Aerospace)" 185 "Beede Instruments" 192 "Floscan Instrument" 193 "Nobeltec" 198 "Mystic Valley Communications" 199 "Actia" 201 "Disenos Y Technologia" 211 "Digital Switching Systems" 215 "Xintex/Atena" 224 "EMMI NETWORK" 228 "ZF" 229 "Garmin" 233 "Yacht Monitoring Solutions" 235 "Sailormade Marine Telemetry/Tetra Technology" 243 "Eride" 257 "Honda Motor" 272 "Groco" 273 "Actisense" 274 "Amphenol LTW Technology" 275 "Navico" 283 "Hamilton Jet" 285 "Sea Recovery" 286 "Coelmo SRL Italy" 295 "BEP Marine" 304 "Empir Bus" 305 "NovAtel" 306 "Sleipner Motor" 307 "MBW Technologies" 315 "ICOM" 328 "Qwerty" 329 "Dief" 341 "Boening Automationstechnologie" 345 "Korean Maritime University" 351 "Thrane and Thrane" 355 "Mastervolt" 356 "Fischer Panda Generators" 358 "Victron Energy" 370 "Rolls Royce Marine" 373 "Electronic Design" 374 "Northern Lights" 378 "Glendinning" 381 "B & G" 384 "Rose Point Navigation Systems" 385 "Johnson Outdoors Marine Electronics Inc Geonav" 394 "Capi 2" 396 "Beyond Measure" 400 "Livorsi Marine" 404 "ComNav" 409 "Chetco" 419 "Fusion Electronics" 421 "Standard Horizon" 422 "True Heading" 426 "Egersund Marine Electronics" 427 "em-trak Marine Electronics" 431 "Tohatsu Co, JP" 437 "Digital Yacht" 438 "Comar Systems Limited" 440 "Cummins" 443 "VDO (aka Continental-Corporation)" 451 "Parker Hannifin aka Village Marine Tech" 459 "Alltek Marine Electronics" 460 "SAN GIORGIO S.E.I.N" 466 "Veethree Electronics & Marine" 470 "SI-TEX Marine Electronics" 471 "Sea Cross Marine" 475 "GME aka Standard Communications" 476 "Humminbird Marine Electronics" 478 "Ocean Sat" 481 "Chetco Digital Instruments" 493 "Watcheye" 499 "Lcj Capteurs" 502 "Attwood Marine" 503 "Naviop S.R.L." 504 "Vesper Marine" 510 "Marinesoft" 513 "Simarine" 517 "NoLand Engineering" 518 "Transas USA" 529 "National Instruments Korea" 530 "National Marine Electronics Association" 532 "Onwa Marine" 540 "Webasto" 571 "Marinecraft (South Korea)" 573 "McMurdo Group aka Orolia" 578 "Advansea" 579 "KVH" 580 "San Jose Technology" 583 "Yacht Control" 586 "Suzuki Motor" 591 "US Coast Guard" 595 "Ship Module aka Customware" 600 "Aquatic AV" 605 "Aventics" 606 "Intellian" 612 "SamwonIT" 614 "Arlt Tecnologies" 637 "Bavaria Yachts" 641 "Diverse Yacht Services" 644 "Wema U.S.A dba KUS" 658 "Shenzhen Jiuzhou Himunication" 688 "Rockford" 699 "Harman International" 704 "JL Audio" 708 "Lars Thrane" 715 "Autonnic" 717 "Yacht Devices" 734 "REAP Systems" 735 "AEM Performance Electronics" 739 "LxNav" 741 "Littelfuse, Inc (formerly Carling Technologies)" 743 "DaeMyung" 744 "Woosung" 748 "ISOTTA IFRA srl" 773 "Clarion US" 776 "HMI Systems" 777 "Ocean Signal" 778 "Seakeeper" 781 "Poly Planar" 785 "Fischer Panda DE" 795 "Broyda Industries" 796 "Canadian Automotive" 797 "Tides Marine" 798 "Lumishore" 799 "Still Water Designs and Audio" 802 "BJ Technologies (Beneteau)" 803 "Gill Sensors" 811 "Blue Water Desalination" 815 "FLIR" 824 "Undheim Systems" 826 "Lewmar" 838 "TeamSurv" 844 "Fell Marine" 847 "Oceanvolt" 862 "Prospec" 868 "Data Panel" 890 "L3 Technologies" 894 "Rhodan Marine Systems" 896 "Nexfour Solutions" 905 "ASA Electronics" 909 "Marines Co (South Korea)" 911 "Nautic-on" 917 "Sentinel" 929 "JL Marine Systems" 930 "Ecotronix" 944 "Zontisa Marine" 951 "EXOR International" 962 "Timbolier Industries" 963 "TJC Micro" 968 "Cox Powertrain" 969 "Blue Seas" 981 "Kobelt Manufacturing" 992 "Blue Ocean IOT" 997 "Xenta Systems" 999 "Signal K" 1004 "Ultraflex" 1008 "Lintest SmartBoat" 1011 "Soundmax" 1020 "Team Italia Marine (Onyx Marine Automation s.r.l)" 1021 "Entratech" 1022 "ITC" 1029 "The Marine Guardian" 1047 "Sonic" 1051 "ProNav" 1053 "Vetus Maxwell INC." 1056 "Lithium Pros" 1059 "Boatrax" 1062 "Marol Co ltd" 1065 "CALYPSO Instruments" 1066 "Spot Zero Water" 1069 "Lithionics Battery" 1070 "Quick-teck Electronics" 1075 "Uniden America" 1083 "Nauticoncept" 1084 "Shadow-Caster LED lighting" 1085 "Wet Sounds" 1088 "E-T-A Circuit Breakers" 1092 "Scheiber" 1100 "Smart Yachts International Limited" 1109 "Dockmate" 1114 "Bobs Machine" 1118 "L3Harris ASV" 1119 "Balmar" 1120 "Elettromedia" 1127 "Electromaax" 1140 "Across Oceans Systems" 1145 "Kiwi Yachting" 1150 "BSB Artificial Intelligence" 1151 "Orca Technologies" 1154 "TBS Electronics" 1158 "Technoton Electroics" 1160 "MG Energy Systems" 1169 "Sea Machine Robotics" 1171 "Vista Manufacturing" 1183 "Zipwake" 1186 "Sailmon" 1192 "Airmoniq Pro Kft" 1194 "Sierra Marine" 1200 "Xinuo Information Technology (Xiamen)" 1218 "Septentrio" 1233 "NKE Marine Electronics" 1238 "SuperTrack Aps" 1239 "Honda Electronics" 1245 "Raritan Engineering" 1249 "Integrated Power Solutions AG" 1260 "Interactive Technologies" 1283 "LTG-Tech" 1299 "Energy Solutions (UK)" 1300 "WATT Fuel Cell" 1302 "Pro Mainer" 1305 "Dragonfly Energy" 1306 "Koden Electronics" 1311 "Humphree" 1316 "Hinkley Yachts" 1317 "Global Marine Management GmbH (GMM)" 1320 "Triskel Marine" 1330 "Warwick Control Technologies" 1331 "Dolphin Charger" 1337 "Barnacle Systems" 1348 "Radian IoT" 1353 "Ocean LED Marine" 1359 "BluNav" 1361 "OVA (Nantong Saiyang Electronics Co., Ltd)" 1368 "RAD Propulsion" 1369 "Electric Yacht" 1372 "Elco Motor Yachts" 1384 "Tecnoseal Foundry S.r.l" 1385 "Pro Charging Systems" 1389 "EVEX" 1398 "Gobius Sensor Technology" 1403 "Arco Marine" 1408 "Lenco Marine" 1413 "Naocontrol" 1417 "Revatek" 1438 "Aeolionics" 1439 "PredictWind" 1440 "Egis Mobile Electric" 1445 "Starboard Yacht Group" 1446 "Roswell Marine" 1451 "ePropulsion (Guangdong ePropulsion Technology Ltd.)" 1452 "Micro-Air" 1453 "Vital Battery" 1458 "Ride Controller" 1460 "Tocaro Blue" 1461 "Vanquish Yachts" 1471 "FT Technologies" 1478 "Alps Alpine" 1481 "E-Force Marine" 1482 "CMC Marine" 1483 "Nanjing Sandemarine Information Technology" 1850 "Teleflex Marine (SeaStar Solutions)" 1851 "Raymarine" 1852 "Navionics" 1853 "Japan Radio" 1854 "Northstar Technologies" 1855 "Furuno" 1856 "Trimble" 1857 "Simrad" 1858 "Litton" 1859 "Kvasar" 1860 "MMP" 1861 "Vector Cantech" 1862 "Yamaha Marine" 1863 "Faria Instruments" ;
VAL_ 2650734592 Industry_Code 0 "Global" 1 "Highway" 2 "Agriculture" 3 "Construction" 4 "Marine Industry" 5 "Industrial" ;
VAL_ 2650734592 Proprietary_ID 1 "Init #2" 4 "AM Radio" 5 "Zone Info" 6 "Source" 8 "Source List" 9 "Control" 12 "FM Radio" 13 "Playlist" 14 "Track" 15 "Artist" 16 "Album" 19 "Menu Item" 20 "Zones" 23 "Max Volume" 24 "Volume" 25 "Init #1" 48 "Position" 50 "Init #3" ;
VAL_ 2650734592 Control 0 "Set" 128 "Ack" ;
VAL_ 2650734592 Manufacturer_Code 69 "ARKS Enterprises" 78 "FW Murphy/Enovation Controls" 80 "Twin Disc" 85 "Kohler Power Systems" 88 "Hemisphere GPS" 135 "Airmar" 137 "Maretron" 140 "Lowrance" 144 "Mercury Marine" 147 "Nautibus Electronic" 148 "Blue Water Data" 154 "Westerbeke" 157 "ISSPRO" 161 "Offshore Systems (UK)" 163 "Evinrude/BRP" 165 "CPAC Systems" 168 "Xantrex Technology" 169 "Marlin Technologies" 172 "Yanmar Marine" 174 "Volvo Penta" 176 "Carling Technologies Inc. (Moritz Aerospace)" 185 "Beede Instruments" 192 "Floscan Instrument" 193 "Nobeltec" 198 "Mystic Valley Communications" 199 "Actia" 201 "Disenos Y Technologia" 211 "Digital Switching Systems" 215 "Xintex/Atena" 224 "EMMI NETWORK" 228 "ZF" 229 "Garmin" 233 "Yacht Monitoring Solutions" 235 "Sailormade Marine Telemetry/Tetra Technology" 243 "Eride" 257 "Honda Motor" 272 "Groco" 273 "Actisense" 274 "Amphenol LTW Technology" 275 "Navico" 283 "Hamilton Jet" 285 "Sea Recovery" 286 "Coelmo SRL Italy" 295 "BEP Marine" 304 "Empir Bus" 305 "NovAtel" 306 "Sleipner Motor" 307 "MBW Technologies" 315 "ICOM" 328 "Qwerty" 329 "Dief" 341 "Boening Automationstechnologie" 345 "Korean Maritime University" 351 "Thrane and Thrane" 355 "Mastervolt" 356 "Fischer Panda Generators" 358 "Victron Energy" 370 "Rolls Royce Marine" 373 "Electronic Design" 374 "Northern Lights" 378 "Glendinning" 381 "B & G" 384 "Rose Point Navigation Systems" 385 "Johnson Outdoors Marine Electronics Inc Geonav" 394 "Capi 2" 396 "Beyond Measure" 400 "Livorsi Marine" 404 "ComNav" 409 "Chetco" 419 "Fusion Electronics" 421 "Standard Horizon" 422 "True Heading" 426 "Egersund Marine Electronics" 427 "em-trak Marine Electronics" 431 "Tohatsu Co, JP" 437 "Digital Yacht" 438 "Comar Systems Limited" 440 "Cummins" 443 "VDO (aka Continental-Corporation)" 451 "Parker Hannifin aka Village Marine Tech" 459 "Alltek Marine Electronics" 460 "SAN GIORGIO S.E.I.N" 466 "Veethree Electronics & Marine" 470 "SI-TEX Marine Electronics" 471 "Sea Cross Marine" 475 "GME aka Standard Communications" 476 "Humminbird Marine Electronics" 478 "Ocean Sat" 481 "Chetco Digital Instruments" 493 "Watcheye" 499 "Lcj Capteurs" 502 "Attwood Marine" 503 "Naviop S.R.L." 504 "Vesper Marine" 510 "Marinesoft" 513 "Simarine" 517 "NoLand Engineering" 518 "Transas USA" 529 "National Instruments Korea" 530 "National Marine Electronics Association" 532 "Onwa Marine" 540 "Webasto" 571 "Marinecraft (South Korea)" 573 "McMurdo Group aka Orolia" 578 "Advansea" 579 "KVH" 580 "San Jose Technology" 583 "Yacht Control" 586 "Suzuki Motor" 591 "US Coast Guard" 595 "Ship Module aka Customware" 600 "Aquatic AV" 605 "Aventics" 606 "Intellian" 612 "SamwonIT" 614 "Arlt Tecnologies" 637 "Bavaria Yachts" 641 "Diverse Yacht Services" 644 "Wema U.S.A dba KUS" 658 "Shenzhen Jiuzhou Himunication" 688 "Rockford" 699 "Harman International" 704 "JL Audio" 708 "Lars Thrane" 715 "Autonnic" 717 "Yacht Devices" 734 "REAP Systems" 735 "AEM Performance Electronics" 739 "LxNav" 741 "Littelfuse, Inc (formerly Carling Technologies)" 743 "DaeMyung" 744 "Woosung" 748 "ISOTTA IFRA srl" 773 "Clarion US" 776 "HMI Systems" 777 "Ocean Signal" 778 "Seakeeper" 781 "Poly Planar" 785 "Fischer Panda DE" 795 "Broyda Industries" 796 "Canadian Automotive" 797 "Tides Marine" 798 "Lumishore" 799 "Still Water Designs and Audio" 802 "BJ Technologies (Beneteau)" 803 "Gill Sensors" 811 "Blue Water Desalination" 815 "FLIR" 824 "Undheim Systems" 826 "Lewmar" 838 "TeamSurv" 844 "Fell Marine" 847 "Oceanvolt" 862 "Prospec" 868 "Data Panel" 890 "L3 Technologies" 894 "Rhodan Marine Systems" 896 "Nexfour Solutions" 905 "ASA Electronics" 909 "Marines Co (South Korea)" 911 "Nautic-on" 917 "Sentinel" 929 "JL Marine Systems" 930 "Ecotronix" 944 "Zontisa Marine" 951 "EXOR International" 962 "Timbolier Industries" 963 "TJC Micro" 968 "Cox Powertrain" 969 "Blue Seas" 981 "Kobelt Manufacturing" 992 "Blue Ocean IOT" 997 "Xenta Systems" 999 "Signal K" 1004 "Ultraflex" 1008 "Lintest SmartBoat" 1011 "Soundmax" 1020 "Team Italia Marine (Onyx Marine Automation s.r.l)" 1021 "Entratech" 1022 "ITC" 1029 "The Marine Guardian" 1047 "Sonic" 1051 "ProNav" 1053 "Vetus Maxwell INC." 1056 "Lithium Pros" 1059 "Boatrax" 1062 "Marol Co ltd" 1065 "CALYPSO Instruments" 1066 "Spot Zero Water" 1069 "Lithionics Battery" 1070 "Quick-teck Electronics" 1075 "Uniden America" 1083 "Nauticoncept" 1084 "Shadow-Caster LED lighting" 1085 "Wet Sounds" 1088 "E-T-A Circuit Breakers" 1092 "Scheiber" 1100 "Smart Yachts International Limited" 1109 "Dockmate" 1114 "Bobs Machine" 1118 "L3Harris ASV" 1119 "Balmar" 1120 "Elettromedia" 1127 "Electromaax" 1140 "Across Oceans Systems" 1145 "Kiwi Yachting" 1150 "BSB Artificial Intelligence" 1151 "Orca Technologies" 1154 "TBS Electronics" 1158 "Technoton Electroics" 1160 "MG Energy Systems" 1169 "Sea Machine Robotics" 1171 "Vista Manufacturing" 1183 "Zipwake" 1186 "Sailmon" 1192 "Airmoniq Pro Kft" 1194 "Sierra Marine" 1200 "Xinuo Information Technology (Xiamen)" 1218 "Septentrio" 1233 "NKE Marine Electronics" 1238 "SuperTrack Aps" 1239 "Honda Electronics" 1245 "Raritan Engineering" 1249 "Integrated Power Solutions AG" 1260 "Interactive Technologies" 1283 "LTG-Tech" 1299 "Energy Solutions (UK)" 1300 "WATT Fuel Cell" 1302 "Pro Mainer" 1305 "Dragonfly Energy" 1306 "Koden Electronics" 1311 "Humphree" 1316 "Hinkley Yachts" 1317 "Global Marine Management GmbH (GMM)" 1320 "Triskel Marine" 1330 "Warwick Control Technologies" 1331 "Dolphin Charger" 1337 "Barnacle Systems" 1348 "Radian IoT" 1353 "Ocean LED Marine" 1359 "BluNav" 1361 "OVA (Nantong Saiyang Electronics Co., Ltd)" 1368 "RAD Propulsion" 1369 "Electric Yacht" 1372 "Elco Motor Yachts" 1384 "Tecnoseal Foundry S.r.l" 1385 "Pro Charging Systems" 1389 "EVEX" 1398 "Gobius Sensor Technology" 1403 "Arco Marine" 1408 "Lenco Marine" 1413 "Naocontrol" 1417 "Revatek" 1438 "Aeolionics" 1439 "PredictWind" 1440 "Egis Mobile Electric" 1445 "Starboard Yacht Group" 1446 "Roswell Marine" 1451 "ePropulsion (Guangdong ePropulsion Technology Ltd.)" 1452 "Micro-Air" 1453 "Vital Battery" 1458 "Ride Controller" 1460 "Tocaro Blue" 1461 "Vanquish Yachts" 1471 "FT Technologies" 1478 "Alps Alpine" 1481 "E-Force Marine" 1482 "CMC Marine" 1483 "Nanjing Sandemarine Information Technology" 1850 "Teleflex Marine (SeaStar Solutions)" 1851 "Raymarine" 1852 "Navionics" 1853 "Japan Radio" 1854 "Northstar Technologies" 1855 "Furuno" 1856 "Trimble" 1857 "Simrad" 1858 "Litton" 1859 "Kvasar" 1860 "MMP" 1861 "Vector Cantech" 1862 "Yamaha Marine" 1863 "Faria Instruments" ;
VAL_ 2650734592 Industry_Code 0 "Global" 1 "Highway" 2 "Agriculture" 3 "Construction" 4 "Marine Industry" 5 "Industrial" ;
VAL_ 2650734592 Proprietary_ID 1 "Init #2" 4 "AM Radio" 5 "Zone Info" 6 "Source" 8 "Source List" 9 "Control" 12 "FM Radio" 13 "Playlist" 14 "Track" 15 "Artist" 16 "Album" 19 "Menu Item" 20 "Zones" 23 "Max Volume" 24 "Volume" 25 "Init #1" 48 "Position" 50 "Init #3" ;
VAL_ 2650734592 Control 0 "Set" 128 "Ack" ;
VAL_ 2650734592 Item 1 "Seeking up" 2 "Tuned" 3 "Seeking down" ;
VAL_ 2650734592 Manufacturer_Code 69 "ARKS Enterprises" 78 "FW Murphy/Enovation Controls" 80 "Twin Disc" 85 "Kohler Power Systems" 88 "Hemisphere GPS" 135 "Airmar" 137 "Maretron" 140 "Lowrance" 144 "Mercury Marine" 147 "Nautibus Electronic" 148 "Blue Water Data" 154 "Westerbeke" 157 "ISSPRO" 161 "Offshore Systems (UK)" 163 "Evinrude/BRP" 165 "CPAC Systems" 168 "Xantrex Technology" 169 "Marlin Technologies" 172 "Yanmar Marine" 174 "Volvo Penta" 176 "Carling Technologies Inc. (Moritz Aerospace)" 185 "Beede Instruments" 192 "Floscan Instrument" 193 "Nobeltec" 198 "Mystic Valley Communications" 199 "Actia" 201 "Disenos Y Technologia" 211 "Digital Switching Systems" 215 "Xintex/Atena" 224 "EMMI NETWORK" 228 "ZF" 229 "Garmin" 233 "Yacht Monitoring Solutions" 235 "Sailormade Marine Telemetry/Tetra Technology" 243 "Eride" 257 "Honda Motor" 272 "Groco" 273 "Actisense" 274 "Amphenol LTW Technology" 275 "Navico" 283 "Hamilton Jet" 285 "Sea Recovery" 286 "Coelmo SRL Italy" 295 "BEP Marine" 304 "Empir Bus" 305 "NovAtel" 306 "Sleipner Motor" 307 "MBW Technologies" 315 "ICOM" 328 "Qwerty" 329 "Dief" 341 "Boening Automationstechnologie" 345 "Korean Maritime University" 351 "Thrane and Thrane" 355 "Mastervolt" 356 "Fischer Panda Generators" 358 "Victron Energy" 370 "Rolls Royce Marine" 373 "Electronic Design" 374 "Northern Lights" 378 "Glendinning" 381 "B & G" 384 "Rose Point Navigation Systems" 385 "Johnson Outdoors Marine Electronics Inc Geonav" 394 "Capi 2" 396 "Beyond Measure" 400 "Livorsi Marine" 404 "ComNav" 409 "Chetco" 419 "Fusion Electronics" 421 "Standard Horizon" 422 "True Heading" 426 "Egersund Marine Electronics" 427 "em-trak Marine Electronics" 431 "Tohatsu Co, JP" 437 "Digital Yacht" 438 "Comar Systems Limited" 440 "Cummins" 443 "VDO (aka Continental-Corporation)" 451 "Parker Hannifin aka Village Marine Tech" 459 "Alltek Marine Electronics" 460 "SAN GIORGIO S.E.I.N" 466 "Veethree Electronics & Marine" 470 "SI-TEX Marine Electronics" 471 "Sea Cross Marine" 475 "GME aka Standard Communications" 476 "Humminbird Marine Electronics" 478 "Ocean Sat" 481 "Chetco Digital Instruments" 493 "Watcheye" 499 "Lcj Capteurs" 502 "Attwood Marine" 503 "Naviop S.R.L." 504 "Vesper Marine" 510 "Marinesoft" 513 "Simarine" 517 "NoLand Engineering" 518 "Transas USA" 529 "National Instruments Korea" 530 "National Marine Electronics Association" 532 "Onwa Marine" 540 "Webasto" 571 "Marinecraft (South Korea)" 573 "McMurdo Group aka Orolia" 578 "Advansea" 579 "KVH" 580 "San Jose Technology" 583 "Yacht Control" 586 "Suzuki Motor" 591 "US Coast Guard" 595 "Ship Module aka Customware" 600 "Aquatic AV" 605 "Aventics" 606 "Intellian" 612 "SamwonIT" 614 "Arlt Tecnologies" 637 "Bavaria Yachts" 641 "Diverse Yacht Services" 644 "Wema U.S.A dba KUS" 658 "Shenzhen Jiuzhou Himunication" 688 "Rockford" 699 "Harman International" 704 "JL Audio" 708 "Lars Thrane" 715 "Autonnic" 717 "Yacht Devices" 734 "REAP Systems" 735 "AEM Performance Electronics" 739 "LxNav" 741 "Littelfuse, Inc (formerly Carling Technologies)" 743 "DaeMyung" 744 "Woosung" 748 "ISOTTA IFRA srl" 773 "Clarion US" 776 "HMI Systems" 777 "Ocean Signal" 778 "Seakeeper" 781 "Poly Planar" 785 "Fischer Panda DE" 795 "Broyda Industries" 796 "Canadian Automotive" 797 "Tides Marine" 798 "Lumishore" 799 "Still Water Designs and Audio" 802 "BJ Technologies (Beneteau)" 803 "Gill Sensors" 811 "Blue Water Desalination" 815 "FLIR" 824 "Undheim Systems" 826 "Lewmar" 838 "TeamSurv" 844 "Fell Marine" 847 "Oceanvolt" 862 "Prospec" 868 "Data Panel" 890 "L3 Technologies" 894 "Rhodan Marine Systems" 896 "Nexfour Solutions" 905 "ASA Electronics" 909 "Marines Co (South Korea)" 911 "Nautic-on" 917 "Sentinel" 929 "JL Marine Systems" 930 "Ecotronix" 944 "Zontisa Marine" 951 "EXOR International" 962 "Timbolier Industries" 963 "TJC Micro" 968 "Cox Powertrain" 969 "Blue Seas" 981 "Kobelt Manufacturing" 992 "Blue Ocean IOT" 997 "Xenta Systems" 999 "Signal K" 1004 "Ultraflex" 1008 "Lintest SmartBoat" 1011 "Soundmax" 1020 "Team Italia Marine (Onyx Marine Automation s.r.l)" 1021 "Entratech" 1022 "ITC" 1029 "The Marine Guardian" 1047 "Sonic" 1051 "ProNav" 1053 "Vetus Maxwell INC." 1056 "Lithium Pros" 1059 "Boatrax" 1062 "Marol Co ltd" 1065 "CALYPSO Instruments" 1066 "Spot Zero Water" 1069 "Lithionics Battery" 1070 "Quick-teck Electronics" 1075 "Uniden America" 1083 "Nauticoncept" 1084 "Shadow-Caster LED lighting" 1085 "Wet Sounds" 1088 "E-T-A Circuit Breakers" 1092 "Scheiber" 1100 "Smart Yachts International Limited" 1109 "Dockmate" 1114 "Bobs Machine" 1118 "L3Harris ASV" 1119 "Balmar" 1120 "Elettromedia" 1127 "Electromaax" 1140 "Across Oceans Systems" 1145 "Kiwi Yachting" 1150 "BSB Artificial Intelligence" 1151 "Orca Technologies" 1154 "TBS Electronics" 1158 "Technoton Electroics" 1160 "MG Energy Systems" 1169 "Sea Machine Robotics" 1171 "Vista Manufacturing" 1183 "Zipwake" 1186 "Sailmon" 1192 "Airmoniq Pro Kft" 1194 "Sierra Marine" 1200 "Xinuo Information Technology (Xiamen)" 1218 "Septentrio" 1233 "NKE Marine Electronics" 1238 "SuperTrack Aps" 1239 "Honda Electronics" 1245 "Raritan Engineering" 1249 "Integrated Power Solutions AG" 1260 "Interactive Technologies" 1283 "LTG-Tech" 1299 "Energy Solutions (UK)" 1300 "WATT Fuel Cell" 1302 "Pro Mainer" 1305 "Dragonfly Energy" 1306 "Koden Electronics" 1311 "Humphree" 1316 "Hinkley Yachts" 1317 "Global Marine Management GmbH (GMM)" 1320 "Triskel Marine" 1330 "Warwick Control Technologies" 1331 "Dolphin Charger" 1337 "Barnacle Systems" 1348 "Radian IoT" 1353 "Ocean LED Marine" 1359 "BluNav" 1361 "OVA (Nantong Saiyang Electronics Co., Ltd)" 1368 "RAD Propulsion" 1369 "Electric Yacht" 1372 "Elco Motor Yachts" 1384 "Tecnoseal Foundry S.r.l" 1385 "Pro Charging Systems" 1389 "EVEX" 1398 "Gobius Sensor Technology" 1403 "Arco Marine" 1408 "Lenco Marine" 1413 "Naocontrol" 1417 "Revatek" 1438 "Aeolionics" 1439 "PredictWind" 1440 "Egis Mobile Electric" 1445 "Starboard Yacht Group" 1446 "Roswell Marine" 1451 "ePropulsion (Guangdong ePropulsion Technology Ltd.)" 1452 "Micro-Air" 1453 "Vital Battery" 1458 "Ride Controller" 1460 "Tocaro Blue" 1461 "Vanquish Yachts" 1471 "FT Technologies" 1478 "Alps Alpine" 1481 "E-Force Marine" 1482 "CMC Marine" 1483 "Nanjing Sandemarine Information Technology" 1850 "Teleflex Marine (SeaStar Solutions)" 1851 "Raymarine" 1852 "Navionics" 1853 "Japan Radio" 1854 "Northstar Technologies" 1855 "Furuno" 1856 "Trimble" 1857 "Simrad" 1858 "Litton" 1859 "Kvasar" 1860 "MMP" 1861 "Vector Cantech" 1862 "Yamaha Marine" 1863 "Faria Instruments" ;
VAL_ 2650734592 Industry_Code 0 "Global" 1 "Highway" 2 "Agriculture" 3 "Construction" 4 "Marine Industry" 5 "Industrial" ;
VAL_ 2650734592 Proprietary_ID 1 "Init #2" 4 "AM Radio" 5 "Zone Info" 6 "Source" 8 "Source List" 9 "Control" 12 "FM Radio" 13 "Playlist" 14 "Track" 15 "Artist" 16 "Album" 19 "Menu Item" 20 "Zones" 23 "Max Volume" 24 "Volume" 25 "Init #1" 48 "Position" 50 "Init #3" ;
VAL_ 2650734592 Control 0 "Set" 128 "Ack" ;
VAL_ 2650734592 Manufacturer_Code 69 "ARKS Enterprises" 78 "FW Murphy/Enovation Controls" 80 "Twin Disc" 85 "Kohler Power Systems" 88 "Hemisphere GPS" 135 "Airmar" 137 "Maretron" 140 "Lowrance" 144 "Mercury Marine" 147 "Nautibus Electronic" 148 "Blue Water Data" 154 "Westerbeke" 157 "ISSPRO" 161 "Offshore Systems (UK)" 163 "Evinrude/BRP" 165 "CPAC Systems" 168 "Xantrex Technology" 169 "Marlin Technologies" 172 "Yanmar Marine" 174 "Volvo Penta" 176 "Carling Technologies Inc. (Moritz Aerospace)" 185 "Beede Instruments" 192 "Floscan Instrument" 193 "Nobeltec" 198 "Mystic Valley Communications" 199 "Actia" 201 "Disenos Y Technologia" 211 "Digital Switching Systems" 215 "Xintex/Atena" 224 "EMMI NETWORK" 228 "ZF" 229 "Garmin" 233 "Yacht Monitoring Solutions" 235 "Sailormade Marine Telemetry/Tetra Technology" 243 "Eride" 257 "Honda Motor" 272 "Groco" 273 "Actisense" 274 "Amphenol LTW Technology" 275 "Navico" 283 "Hamilton Jet" 285 "Sea Recovery" 286 "Coelmo SRL Italy" 295 "BEP Marine" 304 "Empir Bus" 305 "NovAtel" 306 "Sleipner Motor" 307 "MBW Technologies" 315 "ICOM" 328 "Qwerty" 329 "Dief" 341 "Boening Automationstechnologie" 345 "Korean Maritime University" 351 "Thrane and Thrane" 355 "Mastervolt" 356 "Fischer Panda Generators" 358 "Victron Energy" 370 "Rolls Royce Marine" 373 "Electronic Design" 374 "Northern Lights" 378 "Glendinning" 381 "B & G" 384 "Rose Point Navigation Systems" 385 "Johnson Outdoors Marine Electronics Inc Geonav" 394 "Capi 2" 396 "Beyond Measure" 400 "Livorsi Marine" 404 "ComNav" 409 "Chetco" 419 "Fusion Electronics" 421 "Standard Horizon" 422 "True Heading" 426 "Egersund Marine Electronics" 427 "em-trak Marine Electronics" 431 "Tohatsu Co, JP" 437 "Digital Yacht" 438 "Comar Systems Limited" 440 "Cummins" 443 "VDO (aka Continental-Corporation)" 451 "Parker Hannifin aka Village Marine Tech" 459 "Alltek Marine Electronics" 460 "SAN GIORGIO S.E.I.N" 466 "Veethree Electronics & Marine" 470 "SI-TEX Marine Electronics" 471 "Sea Cross Marine" 475 "GME aka Standard Communications" 476 "Humminbird Marine Electronics" 478 "Ocean Sat" 481 "Chetco Digital Instruments" 493 "Watcheye" 499 "Lcj Capteurs" 502 "Attwood Marine" 503 "Naviop S.R.L." 504 "Vesper Marine" 510 "Marinesoft" 513 "Simarine" 517 "NoLand Engineering" 518 "Transas USA" 529 "National Instruments Korea" 530 "National Marine Electronics Association" 532 "Onwa Marine" 540 "Webasto" 571 "Marinecraft (South Korea)" 573 "McMurdo Group aka Orolia" 578 "Advansea" 579 "KVH" 580 "San Jose Technology" 583 "Yacht Control" 586 "Suzuki Motor" 591 "US Coast Guard" 595 "Ship Module aka Customware" 600 "Aquatic AV" 605 "Aventics" 606 "Intellian" 612 "SamwonIT" 614 "Arlt Tecnologies" 637 "Bavaria Yachts" 641 "Diverse Yacht Services" 644 "Wema U.S.A dba KUS" 658 "Shenzhen Jiuzhou Himunication" 688 "Rockford" 699 "Harman International" 704 "JL Audio" 708 "Lars Thrane" 715 "Autonnic" 717 "Yacht Devices" 734 "REAP Systems" 735 "AEM Performance Electronics" 739 "LxNav" 741 "Littelfuse, Inc (formerly Carling Technologies)" 743 "DaeMyung" 744 "Woosung" 748 "ISOTTA IFRA srl" 773 "Clarion US" 776 "HMI Systems" 777 "Ocean Signal" 778 "Seakeeper" 781 "Poly Planar" 785 "Fischer Panda DE" 795 "Broyda Industries" 796 "Canadian Automotive" 797 "Tides Marine" 798 "Lumishore" 799 "Still Water Designs and Audio" 802 "BJ Technologies (Beneteau)" 803 "Gill Sensors" 811 "Blue Water Desalination" 815 "FLIR" 824 "Undheim Systems" 826 "Lewmar" 838 "TeamSurv" 844 "Fell Marine" 847 "Oceanvolt" 862 "Prospec" 868 "Data Panel" 890 "L3 Technologies" 894 "Rhodan Marine Systems" 896 "Nexfour Solutions" 905 "ASA Electronics" 909 "Marines Co (South Korea)" 911 "Nautic-on" 917 "Sentinel" 929 "JL Marine Systems" 930 "Ecotronix" 944 "Zontisa Marine" 951 "EXOR International" 962 "Timbolier Industries" 963 "TJC Micro" 968 "Cox Powertrain" 969 "Blue Seas" 981 "Kobelt Manufacturing" 992 "Blue Ocean IOT" 997 "Xenta Systems" 999 "Signal K" 1004 "Ultraflex" 1008 "Lintest SmartBoat" 1011 "Soundmax" 1020 "Team Italia Marine (Onyx Marine Automation s.r.l)" 1021 "Entratech" 1022 "ITC" 1029 "The Marine Guardian" 1047 "Sonic" 1051 "ProNav" 1053 "Vetus Maxwell INC." 1056 "Lithium Pros" 1059 "Boatrax" 1062 "Marol Co ltd" 1065 "CALYPSO Instruments" 1066 "Spot Zero Water" 1069 "Lithionics Battery" 1070 "Quick-teck Electronics" 1075 "Uniden America" 1083 "Nauticoncept" 1084 "Shadow-Caster LED lighting" 1085 "Wet Sounds" 1088 "E-T-A Circuit Breakers" 1092 "Scheiber" 1100 "Smart Yachts International Limited" 1109 "Dockmate" 1114 "Bobs Machine" 1118 "L3Harris ASV" 1119 "Balmar" 1120 "Elettromedia" 1127 "Electromaax" 1140 "Across Oceans Systems" 1145 "Kiwi Yachting" 1150 "BSB Artificial Intelligence" 1151 "Orca Technologies" 1154 "TBS Electronics" 1158 "Technoton Electroics" 1160 "MG Energy Systems" 1169 "Sea Machine Robotics" 1171 "Vista Manufacturing" 1183 "Zipwake" 1186 "Sailmon" 1192 "Airmoniq Pro Kft" 1194 "Sierra Marine" 1200 "Xinuo Information Technology (Xiamen)" 1218 "Septentrio" 1233 "NKE Marine Electronics" 1238 "SuperTrack Aps" 1239 "Honda Electronics" 1245 "Raritan Engineering" 1249 "Integrated Power Solutions AG" 1260 "Interactive Technologies" 1283 "LTG-Tech" 1299 "Energy Solutions (UK)" 1300 "WATT Fuel Cell" 1302 "Pro Mainer" 1305 "Dragonfly Energy" 1306 "Koden Electronics" 1311 "Humphree" 1316 "Hinkley Yachts" 1317 "Global Marine Management GmbH (GMM)" 1320 "Triskel Marine" 1330 "Warwick Control Technologies" 1331 "Dolphin Charger" 1337 "Barnacle Systems" 1348 "Radian IoT" 1353 "Ocean LED Marine" 1359 "BluNav" 1361 "OVA (Nantong Saiyang Electronics Co., Ltd)" 1368 "RAD Propulsion" 1369 "Electric Yacht" 1372 "Elco Motor Yachts" 1384 "Tecnoseal Foundry S.r.l" 1385 "Pro Charging Systems" 1389 "EVEX" 1398 "Gobius Sensor Technology" 1403 "Arco Marine" 1408 "Lenco Marine" 1413 "Naocontrol" 1417 "Revatek" 1438 "Aeolionics" 1439 "PredictWind" 1440 "Egis Mobile Electric" 1445 "Starboard Yacht Group" 1446 "Roswell Marine" 1451 "ePropulsion (Guangdong ePropulsion Technology Ltd.)" 1452 "Micro-Air" 1453 "Vital Battery" 1458 "Ride Controller" 1460 "Tocaro Blue" 1461 "Vanquish Yachts" 1471 "FT Technologies" 1478 "Alps Alpine" 1481 "E-Force Marine" 1482 "CMC Marine" 1483 "Nanjing Sandemarine Information Technology" 1850 "Teleflex Marine (SeaStar Solutions)" 1851 "Raymarine" 1852 "Navionics" 1853 "Japan Radio" 1854 "Northstar Technologies" 1855 "Furuno" 1856 "Trimble" 1857 "Simrad" 1858 "Litton" 1859 "Kvasar" 1860 "MMP" 1861 "Vector Cantech" 1862 "Yamaha Marine" 1863 "Faria Instruments" ;
VAL_ 2650734592 Industry_Code 0 "Global" 1 "Highway" 2 "Agriculture" 3 "Construction" 4 "Marine Industry" 5 "Industrial" ;
VAL_ 2650734592 Proprietary_ID 1 "Init #2" 4 "AM Radio" 5 "Zone Info" 6 "Source" 8 "Source List" 9 "Control" 12 "FM Radio" 13 "Playlist" 14 "Track" 15 "Artist" 16 "Album" 19 "Menu Item" 20 "Zones" 23 "Max Volume" 24 "Volume" 25 "Init #1" 48 "Position" 50 "Init #3" ;
VAL_ 2650734592 Control 0 "Set" 128 "Ack" ;
VAL_ 2650734592 Item 1 "Mute On" 2 "Mute Off" ;
VAL_ 2650734592 Manufacturer_Code 69 "ARKS Enterprises" 78 "FW Murphy/Enovation Controls" 80 "Twin Disc" 85 "Kohler Power Systems" 88 "Hemisphere GPS" 135 "Airmar" 137 "Maretron" 140 "Lowrance" 144 "Mercury Marine" 147 "Nautibus Electronic" 148 "Blue Water Data" 154 "Westerbeke" 157 "ISSPRO" 161 "Offshore Systems (UK)" 163 "Evinrude/BRP" 165 "CPAC Systems" 168 "Xantrex Technology" 169 "Marlin Technologies" 172 "Yanmar Marine" 174 "Volvo Penta" 176 "Carling Technologies Inc. (Moritz Aerospace)" 185 "Beede Instruments" 192 "Floscan Instrument" 193 "Nobeltec" 198 "Mystic Valley Communications" 199 "Actia" 201 "Disenos Y Technologia" 211 "Digital Switching Systems" 215 "Xintex/Atena" 224 "EMMI NETWORK" 228 "ZF" 229 "Garmin" 233 "Yacht Monitoring Solutions" 235 "Sailormade Marine Telemetry/Tetra Technology" 243 "Eride" 257 "Honda Motor" 272 "Groco" 273 "Actisense" 274 "Amphenol LTW Technology" 275 "Navico" 283 "Hamilton Jet" 285 "Sea Recovery" 286 "Coelmo SRL Italy" 295 "BEP Marine" 304 "Empir Bus" 305 "NovAtel" 306 "Sleipner Motor" 307 "MBW Technologies" 315 "ICOM" 328 "Qwerty" 329 "Dief" 341 "Boening Automationstechnologie" 345 "Korean Maritime University" 351 "Thrane and Thrane" 355 "Mastervolt" 356 "Fischer Panda Generators" 358 "Victron Energy" 370 "Rolls Royce Marine" 373 "Electronic Design" 374 "Northern Lights" 378 "Glendinning" 381 "B & G" 384 "Rose Point Navigation Systems" 385 "Johnson Outdoors Marine Electronics Inc Geonav" 394 "Capi 2" 396 "Beyond Measure" 400 "Livorsi Marine" 404 "ComNav" 409 "Chetco" 419 "Fusion Electronics" 421 "Standard Horizon" 422 "True Heading" 426 "Egersund Marine Electronics" 427 "em-trak Marine Electronics" 431 "Tohatsu Co, JP" 437 "Digital Yacht" 438 "Comar Systems Limited" 440 "Cummins" 443 "VDO (aka Continental-Corporation)" 451 "Parker Hannifin aka Village Marine Tech" 459 "Alltek Marine Electronics" 460 "SAN GIORGIO S.E.I.N" 466 "Veethree Electronics & Marine" 470 "SI-TEX Marine Electronics" 471 "Sea Cross Marine" 475 "GME aka Standard Communications" 476 "Humminbird Marine Electronics" 478 "Ocean Sat" 481 "Chetco Digital Instruments" 493 "Watcheye" 499 "Lcj Capteurs" 502 "Attwood Marine" 503 "Naviop S.R.L." 504 "Vesper Marine" 510 "Marinesoft" 513 "Simarine" 517 "NoLand Engineering" 518 "Transas USA" 529 "National Instruments Korea" 530 "National Marine Electronics Association" 532 "Onwa Marine" 540 "Webasto" 571 "Marinecraft (South Korea)" 573 "McMurdo Group aka Orolia" 578 "Advansea" 579 "KVH" 580 "San Jose Technology" 583 "Yacht Control" 586 "Suzuki Motor" 591 "US Coast Guard" 595 "Ship Module aka Customware" 600 "Aquatic AV" 605 "Aventics" 606 "Intellian" 612 "SamwonIT" 614 "Arlt Tecnologies" 637 "Bavaria Yachts" 641 "Diverse Yacht Services" 644 "Wema U.S.A dba KUS" 658 "Shenzhen Jiuzhou Himunication" 688 "Rockford" 699 "Harman International" 704 "JL Audio" 708 "Lars Thrane" 715 "Autonnic" 717 "Yacht Devices" 734 "REAP Systems" 735 "AEM Performance Electronics" 739 "LxNav" 741 "Littelfuse, Inc (formerly Carling Technologies)" 743 "DaeMyung" 744 "Woosung" 748 "ISOTTA IFRA srl" 773 "Clarion US" 776 "HMI Systems" 777 "Ocean Signal" 778 "Seakeeper" 781 "Poly Planar" 785 "Fischer Panda DE" 795 "Broyda Industries" 796 "Canadian Automotive" 797 "Tides Marine" 798 "Lumishore" 799 "Still Water Designs and Audio" 802 "BJ Technologies (Beneteau)" 803 "Gill Sensors" 811 "Blue Water Desalination" 815 "FLIR" 824 "Undheim Systems" 826 "Lewmar" 838 "TeamSurv" 844 "Fell Marine" 847 "Oceanvolt" 862 "Prospec" 868 "Data Panel" 890 "L3 Technologies" 894 "Rhodan Marine Systems" 896 "Nexfour Solutions" 905 "ASA Electronics" 909 "Marines Co (South Korea)" 911 "Nautic-on" 917 "Sentinel" 929 "JL Marine Systems" 930 "Ecotronix" 944 "Zontisa Marine" 951 "EXOR International" 962 "Timbolier Industries" 963 "TJC Micro" 968 "Cox Powertrain" 969 "Blue Seas" 981 "Kobelt Manufacturing" 992 "Blue Ocean IOT" 997 "Xenta Systems" 999 "Signal K" 1004 "Ultraflex" 1008 "Lintest SmartBoat" 1011 "Soundmax" 1020 "Team Italia Marine (Onyx Marine Automation s.r.l)" 1021 "Entratech" 1022 "ITC" 1029 "The Marine Guardian" 1047 "Sonic" 1051 "ProNav" 1053 "Vetus Maxwell INC." 1056 "Lithium Pros" 1059 "Boatrax" 1062 "Marol Co ltd" 1065 "CALYPSO Instruments" 1066 "Spot Zero Water" 1069 "Lithionics Battery" 1070 "Quick-teck Electronics" 1075 "Uniden America" 1083 "Nauticoncept" 1084 "Shadow-Caster LED lighting" 1085 "Wet Sounds" 1088 "E-T-A Circuit Breakers" 1092 "Scheiber" 1100 "Smart Yachts International Limited" 1109 "Dockmate" 1114 "Bobs Machine" 1118 "L3Harris ASV" 1119 "Balmar" 1120 "Elettromedia" 1127 "Electromaax" 1140 "Across Oceans Systems" 1145 "Kiwi Yachting" 1150 "BSB Artificial Intelligence" 1151 "Orca Technologies" 1154 "TBS Electronics" 1158 "Technoton Electroics" 1160 "MG Energy Systems" 1169 "Sea Machine Robotics" 1171 "Vista Manufacturing" 1183 "Zipwake" 1186 "Sailmon" 1192 "Airmoniq Pro Kft" 1194 "Sierra Marine" 1200 "Xinuo Information Technology (Xiamen)" 1218 "Septentrio" 1233 "NKE Marine Electronics" 1238 "SuperTrack Aps" 1239 "Honda Electronics" 1245 "Raritan Engineering" 1249 "Integrated Power Solutions AG" 1260 "Interactive Technologies" 1283 "LTG-Tech" 1299 "Energy Solutions (UK)" 1300 "WATT Fuel Cell" 1302 "Pro Mainer" 1305 "Dragonfly Energy" 1306 "Koden Electronics" 1311 "Humphree" 1316 "Hinkley Yachts" 1317 "Global Marine Management GmbH (GMM)" 1320 "Triskel Marine" 1330 "Warwick Control Technologies" 1331 "Dolphin Charger" 1337 "Barnacle Systems" 1348 "Radian IoT" 1353 "Ocean LED Marine" 1359 "BluNav" 1361 "OVA (Nantong Saiyang Electronics Co., Ltd)" 1368 "RAD Propulsion" 1369 "Electric Yacht" 1372 "Elco Motor Yachts" 1384 "Tecnoseal Foundry S.r.l" 1385 "Pro Charging Systems" 1389 "EVEX" 1398 "Gobius Sensor Technology" 1403 "Arco Marine" 1408 "Lenco Marine" 1413 "Naocontrol" 1417 "Revatek" 1438 "Aeolionics" 1439 "PredictWind" 1440 "Egis Mobile Electric" 1445 "Starboard Yacht Group" 1446 "Roswell Marine" 1451 "ePropulsion (Guangdong ePropulsion Technology Ltd.)" 1452 "Micro-Air" 1453 "Vital Battery" 1458 "Ride Controller" 1460 "Tocaro Blue" 1461 "Vanquish Yachts" 1471 "FT Technologies" 1478 "Alps Alpine" 1481 "E-Force Marine" 1482 "CMC Marine" 1483 "Nanjing Sandemarine Information Technology" 1850 "Teleflex Marine (SeaStar Solutions)" 1851 "Raymarine" 1852 "Navionics" 1853 "Japan Radio" 1854 "Northstar Technologies" 1855 "Furuno" 1856 "Trimble" 1857 "Simrad" 1858 "Litton" 1859 "Kvasar" 1860 "MMP" 1861 "Vector Cantech" 1862 "Yamaha Marine" 1863 "Faria Instruments" ;
VAL_ 2650734592 Industry_Code 0 "Global" 1 "Highway" 2 "Agriculture" 3 "Construction" 4 "Marine Industry" 5 "Industrial" ;
VAL_ 2650734592 Proprietary_ID 1 "Init #2" 4 "AM Radio" 5 "Zone Info" 6 "Source" 8 "Source List" 9 "Control" 12 "FM Radio" 13 "Playlist" 14 "Track" 15 "Artist" 16 "Album" 19 "Menu Item" 20 "Zones" 23 "Max Volume" 24 "Volume" 25 "Init #1" 48 "Position" 50 "Init #3" ;
VAL_ 2650734592 Control 0 "Set" 128 "Ack" ;
VAL_ 2650734592 Item 1 "Seeking up" 2 "Tuned" 3 "Seeking down" ;
VAL_ 2650734592 Manufacturer_Code 69 "ARKS Enterprises" 78 "FW Murphy/Enovation Controls" 80 "Twin Disc" 85 "Kohler Power Systems" 88 "Hemisphere GPS" 135 "Airmar" 137 "Maretron" 140 "Lowrance" 144 "Mercury Marine" 147 "Nautibus Electronic" 148 "Blue Water Data" 154 "Westerbeke" 157 "ISSPRO" 161 "Offshore Systems (UK)" 163 "Evinrude/BRP" 165 "CPAC Systems" 168 "Xantrex Technology" 169 "Marlin Technologies" 172 "Yanmar Marine" 174 "Volvo Penta" 176 "Carling Technologies Inc. (Moritz Aerospace)" 185 "Beede Instruments" 192 "Floscan Instrument" 193 "Nobeltec" 198 "Mystic Valley Communications" 199 "Actia" 201 "Disenos Y Technologia" 211 "Digital Switching Systems" 215 "Xintex/Atena" 224 "EMMI NETWORK" 228 "ZF" 229 "Garmin" 233 "Yacht Monitoring Solutions" 235 "Sailormade Marine Telemetry/Tetra Technology" 243 "Eride" 257 "Honda Motor" 272 "Groco" 273 "Actisense" 274 "Amphenol LTW Technology" 275 "Navico" 283 "Hamilton Jet" 285 "Sea Recovery" 286 "Coelmo SRL Italy" 295 "BEP Marine" 304 "Empir Bus" 305 "NovAtel" 306 "Sleipner Motor" 307 "MBW Technologies" 315 "ICOM" 328 "Qwerty" 329 "Dief" 341 "Boening Automationstechnologie" 345 "Korean Maritime University" 351 "Thrane and Thrane" 355 "Mastervolt" 356 "Fischer Panda Generators" 358 "Victron Energy" 370 "Rolls Royce Marine" 373 "Electronic Design" 374 "Northern Lights" 378 "Glendinning" 381 "B & G" 384 "Rose Point Navigation Systems" 385 "Johnson Outdoors Marine Electronics Inc Geonav" 394 "Capi 2" 396 "Beyond Measure" 400 "Livorsi Marine" 404 "ComNav" 409 "Chetco" 419 "Fusion Electronics" 421 "Standard Horizon" 422 "True Heading" 426 "Egersund Marine Electronics" 427 "em-trak Marine Electronics" 431 "Tohatsu Co, JP" 437 "Digital Yacht" 438 "Comar Systems Limited" 440 "Cummins" 443 "VDO (aka Continental-Corporation)" 451 "Parker Hannifin aka Village Marine Tech" 459 "Alltek Marine Electronics" 460 "SAN GIORGIO S.E.I.N" 466 "Veethree Electronics & Marine" 470 "SI-TEX Marine Electronics" 471 "Sea Cross Marine" 475 "GME aka Standard Communications" 476 "Humminbird Marine Electronics" 478 "Ocean Sat" 481 "Chetco Digital Instruments" 493 "Watcheye" 499 "Lcj Capteurs" 502 "Attwood Marine" 503 "Naviop S.R.L." 504 "Vesper Marine" 510 "Marinesoft" 513 "Simarine" 517 "NoLand Engineering" 518 "Transas USA" 529 "National Instruments Korea" 530 "National Marine Electronics Association" 532 "Onwa Marine" 540 "Webasto" 571 "Marinecraft (South Korea)" 573 "McMurdo Group aka Orolia" 578 "Advansea" 579 "KVH" 580 "San Jose Technology" 583 "Yacht Control" 586 "Suzuki Motor" 591 "US Coast Guard" 595 "Ship Module aka Customware" 600 "Aquatic AV" 605 "Aventics" 606 "Intellian" 612 "SamwonIT" 614 "Arlt Tecnologies" 637 "Bavaria Yachts" 641 "Diverse Yacht Services" 644 "Wema U.S.A dba KUS" 658 "Shenzhen Jiuzhou Himunication" 688 "Rockford" 699 "Harman International" 704 "JL Audio" 708 "Lars Thrane" 715 "Autonnic" 717 "Yacht Devices" 734 "REAP Systems" 735 "AEM Performance Electronics" 739 "LxNav" 741 "Littelfuse, Inc (formerly Carling Technologies)" 743 "DaeMyung" 744 "Woosung" 748 "ISOTTA IFRA srl" 773 "Clarion US" 776 "HMI Systems" 777 "Ocean Signal" 778 "Seakeeper" 781 "Poly Planar" 785 "Fischer Panda DE" 795 "Broyda Industries" 796 "Canadian Automotive" 797 "Tides Marine" 798 "Lumishore" 799 "Still Water Designs and Audio" 802 "BJ Technologies (Beneteau)" 803 "Gill Sensors" 811 "Blue Water Desalination" 815 "FLIR" 824 "Undheim Systems" 826 "Lewmar" 838 "TeamSurv" 844 "Fell Marine" 847 "Oceanvolt" 862 "Prospec" 868 "Data Panel" 890 "L3 Technologies" 894 "Rhodan Marine Systems" 896 "Nexfour Solutions" 905 "ASA Electronics" 909 "Marines Co (South Korea)" 911 "Nautic-on" 917 "Sentinel" 929 "JL Marine Systems" 930 "Ecotronix" 944 "Zontisa Marine" 951 "EXOR International" 962 "Timbolier Industries" 963 "TJC Micro" 968 "Cox Powertrain" 969 "Blue Seas" 981 "Kobelt Manufacturing" 992 "Blue Ocean IOT" 997 "Xenta Systems" 999 "Signal K" 1004 "Ultraflex" 1008 "Lintest SmartBoat" 1011 "Soundmax" 1020 "Team Italia Marine (Onyx Marine Automation s.r.l)" 1021 "Entratech" 1022 "ITC" 1029 "The Marine Guardian" 1047 "Sonic" 1051 "ProNav" 1053 "Vetus Maxwell INC." 1056 "Lithium Pros" 1059 "Boatrax" 1062 "Marol Co ltd" 1065 "CALYPSO Instruments" 1066 "Spot Zero Water" 1069 "Lithionics Battery" 1070 "Quick-teck Electronics" 1075 "Uniden America" 1083 "Nauticoncept" 1084 "Shadow-Caster LED lighting" 1085 "Wet Sounds" 1088 "E-T-A Circuit Breakers" 1092 "Scheiber" 1100 "Smart Yachts International Limited" 1109 "Dockmate" 1114 "Bobs Machine" 1118 "L3Harris ASV" 1119 "Balmar" 1120 "Elettromedia" 1127 "Electromaax" 1140 "Across Oceans Systems" 1145 "Kiwi Yachting" 1150 "BSB Artificial Intelligence" 1151 "Orca Technologies" 1154 "TBS Electronics" 1158 "Technoton Electroics" 1160 "MG Energy Systems" 1169 "Sea Machine Robotics" 1171 "Vista Manufacturing" 1183 "Zipwake" 1186 "Sailmon" 1192 "Airmoniq Pro Kft" 1194 "Sierra Marine" 1200 "Xinuo Information Technology (Xiamen)" 1218 "Septentrio" 1233 "NKE Marine Electronics" 1238 "SuperTrack Aps" 1239 "Honda Electronics" 1245 "Raritan Engineering" 1249 "Integrated Power Solutions AG" 1260 "Interactive Technologies" 1283 "LTG-Tech" 1299 "Energy Solutions (UK)" 1300 "WATT Fuel Cell" 1302 "Pro Mainer" 1305 "Dragonfly Energy" 1306 "Koden Electronics" 1311 "Humphree" 1316 "Hinkley Yachts" 1317 "Global Marine Management GmbH (GMM)" 1320 "Triskel Marine" 1330 "Warwick Control Technologies" 1331 "Dolphin Charger" 1337 "Barnacle Systems" 1348 "Radian IoT" 1353 "Ocean LED Marine" 1359 "BluNav" 1361 "OVA (Nantong Saiyang Electronics Co., Ltd)" 1368 "RAD Propulsion" 1369 "Electric Yacht" 1372 "Elco Motor Yachts" 1384 "Tecnoseal Foundry S.r.l" 1385 "Pro Charging Systems" 1389 "EVEX" 1398 "Gobius Sensor Technology" 1403 "Arco Marine" 1408 "Lenco Marine" 1413 "Naocontrol" 1417 "Revatek" 1438 "Aeolionics" 1439 "PredictWind" 1440 "Egis Mobile Electric" 1445 "Starboard Yacht Group" 1446 "Roswell Marine" 1451 "ePropulsion (Guangdong ePropulsion Technology Ltd.)" 1452 "Micro-Air" 1453 "Vital Battery" 1458 "Ride Controller" 1460 "Tocaro Blue" 1461 "Vanquish Yachts" 1471 "FT Technologies" 1478 "Alps Alpine" 1481 "E-Force Marine" 1482 "CMC Marine" 1483 "Nanjing Sandemarine Information Technology" 1850 "Teleflex Marine (SeaStar Solutions)" 1851 "Raymarine" 1852 "Navionics" 1853 "Japan Radio" 1854 "Northstar Technologies" 1855 "Furuno" 1856 "Trimble" 1857 "Simrad" 1858 "Litton" 1859 "Kvasar" 1860 "MMP" 1861 "Vector Cantech" 1862 "Yamaha Marine" 1863 "Faria Instruments" ;
VAL_ 2650734592 Industry_Code 0 "Global" 1 "Highway" 2 "Agriculture" 3 "Construction" 4 "Marine Industry" 5 "Industrial" ;
VAL_ 2650734592 Proprietary_ID 1 "Init #2" 4 "AM Radio" 5 "Zone Info" 6 "Source" 8 "Source List" 9 "Control" 12 "FM Radio" 13 "Playlist" 14 "Track" 15 "Artist" 16 "Album" 19 "Menu Item" 20 "Zones" 23 "Max Volume" 24 "Volume" 25 "Init #1" 48 "Position" 50 "Init #3" ;
VAL_ 2650734592 Control 0 "Set" 128 "Ack" ;
VAL_ 2650734592 Manufacturer_Code 69 "ARKS Enterprises" 78 "FW Murphy/Enovation Controls" 80 "Twin Disc" 85 "Kohler Power Systems" 88 "Hemisphere GPS" 135 "Airmar" 137 "Maretron" 140 "Lowrance" 144 "Mercury Marine" 147 "Nautibus Electronic" 148 "Blue Water Data" 154 "Westerbeke" 157 "ISSPRO" 161 "Offshore Systems (UK)" 163 "Evinrude/BRP" 165 "CPAC Systems" 168 "Xantrex Technology" 169 "Marlin Technologies" 172 "Yanmar Marine" 174 "Volvo Penta" 176 "Carling Technologies Inc. (Moritz Aerospace)" 185 "Beede Instruments" 192 "Floscan Instrument" 193 "Nobeltec" 198 "Mystic Valley Communications" 199 "Actia" 201 "Disenos Y Technologia" 211 "Digital Switching Systems" 215 "Xintex/Atena" 224 "EMMI NETWORK" 228 "ZF" 229 "Garmin" 233 "Yacht Monitoring Solutions" 235 "Sailormade Marine Telemetry/Tetra Technology" 243 "Eride" 257 "Honda Motor" 272 "Groco" 273 "Actisense" 274 "Amphenol LTW Technology" 275 "Navico" 283 "Hamilton Jet" 285 "Sea Recovery" 286 "Coelmo SRL Italy" 295 "BEP Marine" 304 "Empir Bus" 305 "NovAtel" 306 "Sleipner Motor" 307 "MBW Technologies" 315 "ICOM" 328 "Qwerty" 329 "Dief" 341 "Boening Automationstechnologie" 345 "Korean Maritime University" 351 "Thrane and Thrane" 355 "Mastervolt" 356 "Fischer Panda Generators" 358 "Victron Energy" 370 "Rolls Royce Marine" 373 "Electronic Design" 374 "Northern Lights" 378 "Glendinning" 381 "B & G" 384 "Rose Point Navigation Systems" 385 "Johnson Outdoors Marine Electronics Inc Geonav" 394 "Capi 2" 396 "Beyond Measure" 400 "Livorsi Marine" 404 "ComNav" 409 "Chetco" 419 "Fusion Electronics" 421 "Standard Horizon" 422 "True Heading" 426 "Egersund Marine Electronics" 427 "em-trak Marine Electronics" 431 "Tohatsu Co, JP" 437 "Digital Yacht" 438 "Comar Systems Limited" 440 "Cummins" 443 "VDO (aka Continental-Corporation)" 451 "Parker Hannifin aka Village Marine Tech" 459 "Alltek Marine Electronics" 460 "SAN GIORGIO S.E.I.N" 466 "Veethree Electronics & Marine" 470 "SI-TEX Marine Electronics" 471 "Sea Cross Marine" 475 "GME aka Standard Communications" 476 "Humminbird Marine Electronics" 478 "Ocean Sat" 481 "Chetco Digital Instruments" 493 "Watcheye" 499 "Lcj Capteurs" 502 "Attwood Marine" 503 "Naviop S.R.L." 504 "Vesper Marine" 510 "Marinesoft" 513 "Simarine" 517 "NoLand Engineering" 518 "Transas USA" 529 "National Instruments Korea" 530 "National Marine Electronics Association" 532 "Onwa Marine" 540 "Webasto" 571 "Marinecraft (South Korea)" 573 "McMurdo Group aka Orolia" 578 "Advansea" 579 "KVH" 580 "San Jose Technology" 583 "Yacht Control" 586 "Suzuki Motor" 591 "US Coast Guard" 595 "Ship Module aka Customware" 600 "Aquatic AV" 605 "Aventics" 606 "Intellian" 612 "SamwonIT" 614 "Arlt Tecnologies" 637 "Bavaria Yachts" 641 "Diverse Yacht Services" 644 "Wema U.S.A dba KUS" 658 "Shenzhen Jiuzhou Himunication" 688 "Rockford" 699 "Harman International" 704 "JL Audio" 708 "Lars Thrane" 715 "Autonnic" 717 "Yacht Devices" 734 "REAP Systems" 735 "AEM Performance Electronics" 739 "LxNav" 741 "Littelfuse, Inc (formerly Carling Technologies)" 743 "DaeMyung" 744 "Woosung" 748 "ISOTTA IFRA srl" 773 "Clarion US" 776 "HMI Systems" 777 "Ocean Signal" 778 "Seakeeper" 781 "Poly Planar" 785 "Fischer Panda DE" 795 "Broyda Industries" 796 "Canadian Automotive" 797 "Tides Marine" 798 "Lumishore" 799 "Still Water Designs and Audio" 802 "BJ Technologies (Beneteau)" 803 "Gill Sensors" 811 "Blue Water Desalination" 815 "FLIR" 824 "Undheim Systems" 826 "Lewmar" 838 "TeamSurv" 844 "Fell Marine" 847 "Oceanvolt" 862 "Prospec" 868 "Data Panel" 890 "L3 Technologies" 894 "Rhodan Marine Systems" 896 "Nexfour Solutions" 905 "ASA Electronics" 909 "Marines Co (South Korea)" 911 "Nautic-on" 917 "Sentinel" 929 "JL Marine Systems" 930 "Ecotronix" 944 "Zontisa Marine" 951 "EXOR International" 962 "Timbolier Industries" 963 "TJC Micro" 968 "Cox Powertrain" 969 "Blue Seas" 981 "Kobelt Manufacturing" 992 "Blue Ocean IOT" 997 "Xenta Systems" 999 "Signal K" 1004 "Ultraflex" 1008 "Lintest SmartBoat" 1011 "Soundmax" 1020 "Team Italia Marine (Onyx Marine Automation s.r.l)" 1021 "Entratech" 1022 "ITC" 1029 "The Marine Guardian" 1047 "Sonic" 1051 "ProNav" 1053 "Vetus Maxwell INC." 1056 "Lithium Pros" 1059 "Boatrax" 1062 "Marol Co ltd" 1065 "CALYPSO Instruments" 1066 "Spot Zero Water" 1069 "Lithionics Battery" 1070 "Quick-teck Electronics" 1075 "Uniden America" 1083 "Nauticoncept" 1084 "Shadow-Caster LED lighting" 1085 "Wet Sounds" 1088 "E-T-A Circuit Breakers" 1092 "Scheiber" 1100 "Smart Yachts International Limited" 1109 "Dockmate" 1114 "Bobs Machine" 1118 "L3Harris ASV" 1119 "Balmar" 1120 "Elettromedia" 1127 "Electromaax" 1140 "Across Oceans Systems" 1145 "Kiwi Yachting" 1150 "BSB Artificial Intelligence" 1151 "Orca Technologies" 1154 "TBS Electronics" 1158 "Technoton Electroics" 1160 "MG Energy Systems" 1169 "Sea Machine Robotics" 1171 "Vista Manufacturing" 1183 "Zipwake" 1186 "Sailmon" 1192 "Airmoniq Pro Kft" 1194 "Sierra Marine" 1200 "Xinuo Information Technology (Xiamen)" 1218 "Septentrio" 1233 "NKE Marine Electronics" 1238 "SuperTrack Aps" 1239 "Honda Electronics" 1245 "Raritan Engineering" 1249 "Integrated Power Solutions AG" 1260 "Interactive Technologies" 1283 "LTG-Tech" 1299 "Energy Solutions (UK)" 1300 "WATT Fuel Cell" 1302 "Pro Mainer" 1305 "Dragonfly Energy" 1306 "Koden Electronics" 1311 "Humphree" 1316 "Hinkley Yachts" 1317 "Global Marine Management GmbH (GMM)" 1320 "Triskel Marine" 1330 "Warwick Control Technologies" 1331 "Dolphin Charger" 1337 "Barnacle Systems" 1348 "Radian IoT" 1353 "Ocean LED Marine" 1359 "BluNav" 1361 "OVA (Nantong Saiyang Electronics Co., Ltd)" 1368 "RAD Propulsion" 1369 "Electric Yacht" 1372 "Elco Motor Yachts" 1384 "Tecnoseal Foundry S.r.l" 1385 "Pro Charging Systems" 1389 "EVEX" 1398 "Gobius Sensor Technology" 1403 "Arco Marine" 1408 "Lenco Marine" 1413 "Naocontrol" 1417 "Revatek" 1438 "Aeolionics" 1439 "PredictWind" 1440 "Egis Mobile Electric" 1445 "Starboard Yacht Group" 1446 "Roswell Marine" 1451 "ePropulsion (Guangdong ePropulsion Technology Ltd.)" 1452 "Micro-Air" 1453 "Vital Battery" 1458 "Ride Controller" 1460 "Tocaro Blue" 1461 "Vanquish Yachts" 1471 "FT Technologies" 1478 "Alps Alpine" 1481 "E-Force Marine" 1482 "CMC Marine" 1483 "Nanjing Sandemarine Information Technology" 1850 "Teleflex Marine (SeaStar Solutions)" 1851 "Raymarine" 1852 "Navionics" 1853 "Japan Radio" 1854 "Northstar Technologies" 1855 "Furuno" 1856 "Trimble" 1857 "Simrad" 1858 "Litton" 1859 "Kvasar" 1860 "MMP" 1861 "Vector Cantech" 1862 "Yamaha Marine" 1863 "Faria Instruments" ;
VAL_ 2650734592 Industry_Code 0 "Global" 1 "Highway" 2 "Agriculture" 3 "Construction" 4 "Marine Industry" 5 "Industrial" ;
VAL_ 2650734592 Proprietary_ID 1 "Init #2" 4 "AM Radio" 5 "Zone Info" 6 "Source" 8 "Source List" 9 "Control" 12 "FM Radio" 13 "Playlist" 14 "Track" 15 "Artist" 16 "Album" 19 "Menu Item" 20 "Zones" 23 "Max Volume" 24 "Volume" 25 "Init #1" 48 "Position" 50 "Init #3" ;
VAL_ 2650734592 Control 0 "Set" 128 "Ack" ;
VAL_ 2650734592 Manufacturer_Code 69 "ARKS Enterprises" 78 "FW Murphy/Enovation Controls" 80 "Twin Disc" 85 "Kohler Power Systems" 88 "Hemisphere GPS" 135 "Airmar" 137 "Maretron" 140 "Lowrance" 144 "Mercury Marine" 147 "Nautibus Electronic" 148 "Blue Water Data" 154 "Westerbeke" 157 "ISSPRO" 161 "Offshore Systems (UK)" 163 "Evinrude/BRP" 165 "CPAC Systems" 168 "Xantrex Technology" 169 "Marlin Technologies" 172 "Yanmar Marine" 174 "Volvo Penta" 176 "Carling Technologies Inc. (Moritz Aerospace)" 185 "Beede Instruments" 192 "Floscan Instrument" 193 "Nobeltec" 198 "Mystic Valley Communications" 199 "Actia" 201 "Disenos Y Technologia" 211 "Digital Switching Systems" 215 "Xintex/Atena" 224 "EMMI NETWORK" 228 "ZF" 229 "Garmin" 233 "Yacht Monitoring Solutions" 235 "Sailormade Marine Telemetry/Tetra Technology" 243 "Eride" 257 "Honda Motor" 272 "Groco" 273 "Actisense" 274 "Amphenol LTW Technology" 275 "Navico" 283 "Hamilton Jet" 285 "Sea Recovery" 286 "Coelmo SRL Italy" 295 "BEP Marine" 304 "Empir Bus" 305 "NovAtel" 306 "Sleipner Motor" 307 "MBW Technologies" 315 "ICOM" 328 "Qwerty" 329 "Dief" 341 "Boening Automationstechnologie" 345 "Korean Maritime University" 351 "Thrane and Thrane" 355 "Mastervolt" 356 "Fischer Panda Generators" 358 "Victron Energy" 370 "Rolls Royce Marine" 373 "Electronic Design" 374 "Northern Lights" 378 "Glendinning" 381 "B & G" 384 "Rose Point Navigation Systems" 385 "Johnson Outdoors Marine Electronics Inc Geonav" 394 "Capi 2" 396 "Beyond Measure" 400 "Livorsi Marine" 404 "ComNav" 409 "Chetco" 419 "Fusion Electronics" 421 "Standard Horizon" 422 "True Heading" 426 "Egersund Marine Electronics" 427 "em-trak Marine Electronics" 431 "Tohatsu Co, JP" 437 "Digital Yacht" 438 "Comar Systems Limited" 440 "Cummins" 443 "VDO (aka Continental-Corporation)" 451 "Parker Hannifin aka Village Marine Tech" 459 "Alltek Marine Electronics" 460 "SAN GIORGIO S.E.I.N" 466 "Veethree Electronics & Marine" 470 "SI-TEX Marine Electronics" 471 "Sea Cross Marine" 475 "GME aka Standard Communications" 476 "Humminbird Marine Electronics" 478 "Ocean Sat" 481 "Chetco Digital Instruments" 493 "Watcheye" 499 "Lcj Capteurs" 502 "Attwood Marine" 503 "Naviop S.R.L." 504 "Vesper Marine" 510 "Marinesoft" 513 "Simarine" 517 "NoLand Engineering" 518 "Transas USA" 529 "National Instruments Korea" 530 "National Marine Electronics Association" 532 "Onwa Marine" 540 "Webasto" 571 "Marinecraft (South Korea)" 573 "McMurdo Group aka Orolia" 578 "Advansea" 579 "KVH" 580 "San Jose Technology" 583 "Yacht Control" 586 "Suzuki Motor" 591 "US Coast Guard" 595 "Ship Module aka Customware" 600 "Aquatic AV" 605 "Aventics" 606 "Intellian" 612 "SamwonIT" 614 "Arlt Tecnologies" 637 "Bavaria Yachts" 641 "Diverse Yacht Services" 644 "Wema U.S.A dba KUS" 658 "Shenzhen Jiuzhou Himunication" 688 "Rockford" 699 "Harman International" 704 "JL Audio" 708 "Lars Thrane" 715 "Autonnic" 717 "Yacht Devices" 734 "REAP Systems" 735 "AEM Performance Electronics" 739 "LxNav" 741 "Littelfuse, Inc (formerly Carling Technologies)" 743 "DaeMyung" 744 "Woosung" 748 "ISOTTA IFRA srl" 773 "Clarion US" 776 "HMI Systems" 777 "Ocean Signal" 778 "Seakeeper" 781 "Poly Planar" 785 "Fischer Panda DE" 795 "Broyda Industries" 796 "Canadian Automotive" 797 "Tides Marine" 798 "Lumishore" 799 "Still Water Designs and Audio" 802 "BJ Technologies (Beneteau)" 803 "Gill Sensors" 811 "Blue Water Desalination" 815 "FLIR" 824 "Undheim Systems" 826 "Lewmar" 838 "TeamSurv" 844 "Fell Marine" 847 "Oceanvolt" 862 "Prospec" 868 "Data Panel" 890 "L3 Technologies" 894 "Rhodan Marine Systems" 896 "Nexfour Solutions" 905 "ASA Electronics" 909 "Marines Co (South Korea)" 911 "Nautic-on" 917 "Sentinel" 929 "JL Marine Systems" 930 "Ecotronix" 944 "Zontisa Marine" 951 "EXOR International" 962 "Timbolier Industries" 963 "TJC Micro" 968 "Cox Powertrain" 969 "Blue Seas" 981 "Kobelt Manufacturing" 992 "Blue Ocean IOT" 997 "Xenta Systems" 999 "Signal K" 1004 "Ultraflex" 1008 "Lintest SmartBoat" 1011 "Soundmax" 1020 "Team Italia Marine (Onyx Marine Automation s.r.l)" 1021 "Entratech" 1022 "ITC" 1029 "The Marine Guardian" 1047 "Sonic" 1051 "ProNav" 1053 "Vetus Maxwell INC." 1056 "Lithium Pros" 1059 "Boatrax" 1062 "Marol Co ltd" 1065 "CALYPSO Instruments" 1066 "Spot Zero Water" 1069 "Lithionics Battery" 1070 "Quick-teck Electronics" 1075 "Uniden America" 1083 "Nauticoncept" 1084 "Shadow-Caster LED lighting" 1085 "Wet Sounds" 1088 "E-T-A Circuit Breakers" 1092 "Scheiber" 1100 "Smart Yachts International Limited" 1109 "Dockmate" 1114 "Bobs Machine" 1118 "L3Harris ASV" 1119 "Balmar" 1120 "Elettromedia" 1127 "Electromaax" 1140 "Across Oceans Systems" 1145 "Kiwi Yachting" 1150 "BSB Artificial Intelligence" 1151 "Orca Technologies" 1154 "TBS Electronics" 1158 "Technoton Electroics" 1160 "MG Energy Systems" 1169 "Sea Machine Robotics" 1171 "Vista Manufacturing" 1183 "Zipwake" 1186 "Sailmon" 1192 "Airmoniq Pro Kft" 1194 "Sierra Marine" 1200 "Xinuo Information Technology (Xiamen)" 1218 "Septentrio" 1233 "NKE Marine Electronics" 1238 "SuperTrack Aps" 1239 "Honda Electronics" 1245 "Raritan Engineering" 1249 "Integrated Power Solutions AG" 1260 "Interactive Technologies" 1283 "LTG-Tech" 1299 "Energy Solutions (UK)" 1300 "WATT Fuel Cell" 1302 "Pro Mainer" 1305 "Dragonfly Energy" 1306 "Koden Electronics" 1311 "Humphree" 1316 "Hinkley Yachts" 1317 "Global Marine Management GmbH (GMM)" 1320 "Triskel Marine" 1330 "Warwick Control Technologies" 1331 "Dolphin Charger" 1337 "Barnacle Systems" 1348 "Radian IoT" 1353 "Ocean LED Marine" 1359 "BluNav" 1361 "OVA (Nantong Saiyang Electronics Co., Ltd)" 1368 "RAD Propulsion" 1369 "Electric Yacht" 1372 "Elco Motor Yachts" 1384 "Tecnoseal Foundry S.r.l" 1385 "Pro Charging Systems" 1389 "EVEX" 1398 "Gobius Sensor Technology" 1403 "Arco Marine" 1408 "Lenco Marine" 1413 "Naocontrol" 1417 "Revatek" 1438 "Aeolionics" 1439 "PredictWind" 1440 "Egis Mobile Electric" 1445 "Starboard Yacht Group" 1446 "Roswell Marine" 1451 "ePropulsion (Guangdong ePropulsion Technology Ltd.)" 1452 "Micro-Air" 1453 "Vital Battery" 1458 "Ride Controller" 1460 "Tocaro Blue" 1461 "Vanquish Yachts" 1471 "FT Technologies" 1478 "Alps Alpine" 1481 "E-Force Marine" 1482 "CMC Marine" 1483 "Nanjing Sandemarine Information Technology" 1850 "Teleflex Marine (SeaStar Solutions)" 1851 "Raymarine" 1852 "Navionics" 1853 "Japan Radio" 1854 "Northstar Technologies" 1855 "Furuno" 1856 "Trimble" 1857 "Simrad" 1858 "Litton" 1859 "Kvasar" 1860 "MMP" 1861 "Vector Cantech" 1862 "Yamaha Marine" 1863 "Faria Instruments" ;
VAL_ 2650734592 Industry_Code 0 "Global" 1 "Highway" 2 "Agriculture" 3 "Construction" 4 "Marine Industry" 5 "Industrial" ;
VAL_ 2650734592 Proprietary_ID 1 "Init #2" 4 "AM Radio" 5 "Zone Info" 6 "Source" 8 "Source List" 9 "Control" 12 "FM Radio" 13 "Playlist" 14 "Track" 15 "Artist" 16 "Album" 19 "Menu Item" 20 "Zones" 23 "Max Volume" 24 "Volume" 25 "Init #1" 48 "Position" 50 "Init #3" ;
VAL_ 2650734592 Control 0 "Set" 128 "Ack" ;
VAL_ 2650734592 Manufacturer_Code 69 "ARKS Enterprises" 78 "FW Murphy/Enovation Controls" 80 "Twin Disc" 85 "Kohler Power Systems" 88 "Hemisphere GPS" 135 "Airmar" 137 "Maretron" 140 "Lowrance" 144 "Mercury Marine" 147 "Nautibus Electronic" 148 "Blue Water Data" 154 "Westerbeke" 157 "ISSPRO" 161 "Offshore Systems (UK)" 163 "Evinrude/BRP" 165 "CPAC Systems" 168 "Xantrex Technology" 169 "Marlin Technologies" 172 "Yanmar Marine" 174 "Volvo Penta" 176 "Carling Technologies Inc. (Moritz Aerospace)" 185 "Beede Instruments" 192 "Floscan Instrument" 193 "Nobeltec" 198 "Mystic Valley Communications" 199 "Actia" 201 "Disenos Y Technologia" 211 "Digital Switching Systems" 215 "Xintex/Atena" 224 "EMMI NETWORK" 228 "ZF" 229 "Garmin" 233 "Yacht Monitoring Solutions" 235 "Sailormade Marine Telemetry/Tetra Technology" 243 "Eride" 257 "Honda Motor" 272 "Groco" 273 "Actisense" 274 "Amphenol LTW Technology" 275 "Navico" 283 "Hamilton Jet" 285 "Sea Recovery" 286 "Coelmo SRL Italy" 295 "BEP Marine" 304 "Empir Bus" 305 "NovAtel" 306 "Sleipner Motor" 307 "MBW Technologies" 315 "ICOM" 328 "Qwerty" 329 "Dief" 341 "Boening Automationstechnologie" 345 "Korean Maritime University" 351 "Thrane and Thrane" 355 "Mastervolt" 356 "Fischer Panda Generators" 358 "Victron Energy" 370 "Rolls Royce Marine" 373 "Electronic Design" 374 "Northern Lights" 378 "Glendinning" 381 "B & G" 384 "Rose Point Navigation Systems" 385 "Johnson Outdoors Marine Electronics Inc Geonav" 394 "Capi 2" 396 "Beyond Measure" 400 "Livorsi Marine" 404 "ComNav" 409 "Chetco" 419 "Fusion Electronics" 421 "Standard Horizon" 422 "True Heading" 426 "Egersund Marine Electronics" 427 "em-trak Marine Electronics" 431 "Tohatsu Co, JP" 437 "Digital Yacht" 438 "Comar Systems Limited" 440 "Cummins" 443 "VDO (aka Continental-Corporation)" 451 "Parker Hannifin aka Village Marine Tech" 459 "Alltek Marine Electronics" 460 "SAN GIORGIO S.E.I.N" 466 "Veethree Electronics & Marine" 470 "SI-TEX Marine Electronics" 471 "Sea Cross Marine" 475 "GME aka Standard Communications" 476 "Humminbird Marine Electronics" 478 "Ocean Sat" 481 "Chetco Digital Instruments" 493 "Watcheye" 499 "Lcj Capteurs" 502 "Attwood Marine" 503 "Naviop S.R.L." 504 "Vesper Marine" 510 "Marinesoft" 513 "Simarine" 517 "NoLand Engineering" 518 "Transas USA" 529 "National Instruments Korea" 530 "National Marine Electronics Association" 532 "Onwa Marine" 540 "Webasto" 571 "Marinecraft (South Korea)" 573 "McMurdo Group aka Orolia" 578 "Advansea" 579 "KVH" 580 "San Jose Technology" 583 "Yacht Control" 586 "Suzuki Motor" 591 "US Coast Guard" 595 "Ship Module aka Customware" 600 "Aquatic AV" 605 "Aventics" 606 "Intellian" 612 "SamwonIT" 614 "Arlt Tecnologies" 637 "Bavaria Yachts" 641 "Diverse Yacht Services" 644 "Wema U.S.A dba KUS" 658 "Shenzhen Jiuzhou Himunication" 688 "Rockford" 699 "Harman International" 704 "JL Audio" 708 "Lars Thrane" 715 "Autonnic" 717 "Yacht Devices" 734 "REAP Systems" 735 "AEM Performance Electronics" 739 "LxNav" 741 "Littelfuse, Inc (formerly Carling Technologies)" 743 "DaeMyung" 744 "Woosung" 748 "ISOTTA IFRA srl" 773 "Clarion US" 776 "HMI Systems" 777 "Ocean Signal" 778 "Seakeeper" 781 "Poly Planar" 785 "Fischer Panda DE" 795 "Broyda Industries" 796 "Canadian Automotive" 797 "Tides Marine" 798 "Lumishore" 799 "Still Water Designs and Audio" 802 "BJ Technologies (Beneteau)" 803 "Gill Sensors" 811 "Blue Water Desalination" 815 "FLIR" 824 "Undheim Systems" 826 "Lewmar" 838 "TeamSurv" 844 "Fell Marine" 847 "Oceanvolt" 862 "Prospec" 868 "Data Panel" 890 "L3 Technologies" 894 "Rhodan Marine Systems" 896 "Nexfour Solutions" 905 "ASA Electronics" 909 "Marines Co (South Korea)" 911 "Nautic-on" 917 "Sentinel" 929 "JL Marine Systems" 930 "Ecotronix" 944 "Zontisa Marine" 951 "EXOR International" 962 "Timbolier Industries" 963 "TJC Micro" 968 "Cox Powertrain" 969 "Blue Seas" 981 "Kobelt Manufacturing" 992 "Blue Ocean IOT" 997 "Xenta Systems" 999 "Signal K" 1004 "Ultraflex" 1008 "Lintest SmartBoat" 1011 "Soundmax" 1020 "Team Italia Marine (Onyx Marine Automation s.r.l)" 1021 "Entratech" 1022 "ITC" 1029 "The Marine Guardian" 1047 "Sonic" 1051 "ProNav" 1053 "Vetus Maxwell INC." 1056 "Lithium Pros" 1059 "Boatrax" 1062 "Marol Co ltd" 1065 "CALYPSO Instruments" 1066 "Spot Zero Water" 1069 "Lithionics Battery" 1070 "Quick-teck Electronics" 1075 "Uniden America" 1083 "Nauticoncept" 1084 "Shadow-Caster LED lighting" 1085 "Wet Sounds" 1088 "E-T-A Circuit Breakers" 1092 "Scheiber" 1100 "Smart Yachts International Limited" 1109 "Dockmate" 1114 "Bobs Machine" 1118 "L3Harris ASV" 1119 "Balmar" 1120 "Elettromedia" 1127 "Electromaax" 1140 "Across Oceans Systems" 1145 "Kiwi Yachting" 1150 "BSB Artificial Intelligence" 1151 "Orca Technologies" 1154 "TBS Electronics" 1158 "Technoton Electroics" 1160 "MG Energy Systems" 1169 "Sea Machine Robotics" 1171 "Vista Manufacturing" 1183 "Zipwake" 1186 "Sailmon" 1192 "Airmoniq Pro Kft" 1194 "Sierra Marine" 1200 "Xinuo Information Technology (Xiamen)" 1218 "Septentrio" 1233 "NKE Marine Electronics" 1238 "SuperTrack Aps" 1239 "Honda Electronics" 1245 "Raritan Engineering" 1249 "Integrated Power Solutions AG" 1260 "Interactive Technologies" 1283 "LTG-Tech" 1299 "Energy Solutions (UK)" 1300 "WATT Fuel Cell" 1302 "Pro Mainer" 1305 "Dragonfly Energy" 1306 "Koden Electronics" 1311 "Humphree" 1316 "Hinkley Yachts" 1317 "Global Marine Management GmbH (GMM)" 1320 "Triskel Marine" 1330 "Warwick Control Technologies" 1331 "Dolphin Charger" 1337 "Barnacle Systems" 1348 "Radian IoT" 1353 "Ocean LED Marine" 1359 "BluNav" 1361 "OVA (Nantong Saiyang Electronics Co., Ltd)" 1368 "RAD Propulsion" 1369 "Electric Yacht" 1372 "Elco Motor Yachts" 1384 "Tecnoseal Foundry S.r.l" 1385 "Pro Charging Systems" 1389 "EVEX" 1398 "Gobius Sensor Technology" 1403 "Arco Marine" 1408 "Lenco Marine" 1413 "Naocontrol" 1417 "Revatek" 1438 "Aeolionics" 1439 "PredictWind" 1440 "Egis Mobile Electric" 1445 "Starboard Yacht Group" 1446 "Roswell Marine" 1451 "ePropulsion (Guangdong ePropulsion Technology Ltd.)" 1452 "Micro-Air" 1453 "Vital Battery" 1458 "Ride Controller" 1460 "Tocaro Blue" 1461 "Vanquish Yachts" 1471 "FT Technologies" 1478 "Alps Alpine" 1481 "E-Force Marine" 1482 "CMC Marine" 1483 "Nanjing Sandemarine Information Technology" 1850 "Teleflex Marine (SeaStar Solutions)" 1851 "Raymarine" 1852 "Navionics" 1853 "Japan Radio" 1854 "Northstar Technologies" 1855 "Furuno" 1856 "Trimble" 1857 "Simrad" 1858 "Litton" 1859 "Kvasar" 1860 "MMP" 1861 "Vector Cantech" 1862 "Yamaha Marine" 1863 "Faria Instruments" ;
VAL_ 2650734592 Industry_Code 0 "Global" 1 "Highway" 2 "Agriculture" 3 "Construction" 4 "Marine Industry" 5 "Industrial" ;
VAL_ 2650734592 Proprietary_ID 1 "Init #2" 4 "AM Radio" 5 "Zone Info" 6 "Source" 8 "Source List" 9 "Control" 12 "FM Radio" 13 "Playlist" 14 "Track" 15 "Artist" 16 "Album" 19 "Menu Item" 20 "Zones" 23 "Max Volume" 24 "Volume" 25 "Init #1" 48 "Position" 50 "Init #3" ;
VAL_ 2650734592 Control 0 "Set" 128 "Ack" ;
VAL_ 2650734592 Manufacturer_Code 69 "ARKS Enterprises" 78 "FW Murphy/Enovation Controls" 80 "Twin Disc" 85 "Kohler Power Systems" 88 "Hemisphere GPS" 135 "Airmar" 137 "Maretron" 140 "Lowrance" 144 "Mercury Marine" 147 "Nautibus Electronic" 148 "Blue Water Data" 154 "Westerbeke" 157 "ISSPRO" 161 "Offshore Systems (UK)" 163 "Evinrude/BRP" 165 "CPAC Systems" 168 "Xantrex Technology" 169 "Marlin Technologies" 172 "Yanmar Marine" 174 "Volvo Penta" 176 "Carling Technologies Inc. (Moritz Aerospace)" 185 "Beede Instruments" 192 "Floscan Instrument" 193 "Nobeltec" 198 "Mystic Valley Communications" 199 "Actia" 201 "Disenos Y Technologia" 211 "Digital Switching Systems" 215 "Xintex/Atena" 224 "EMMI NETWORK" 228 "ZF" 229 "Garmin" 233 "Yacht Monitoring Solutions" 235 "Sailormade Marine Telemetry/Tetra Technology" 243 "Eride" 257 "Honda Motor" 272 "Groco" 273 "Actisense" 274 "Amphenol LTW Technology" 275 "Navico" 283 "Hamilton Jet" 285 "Sea Recovery" 286 "Coelmo SRL Italy" 295 "BEP Marine" 304 "Empir Bus" 305 "NovAtel" 306 "Sleipner Motor" 307 "MBW Technologies" 315 "ICOM" 328 "Qwerty" 329 "Dief" 341 "Boening Automationstechnologie" 345 "Korean Maritime University" 351 "Thrane and Thrane" 355 "Mastervolt" 356 "Fischer Panda Generators" 358 "Victron Energy" 370 "Rolls Royce Marine" 373 "Electronic Design" 374 "Northern Lights" 378 "Glendinning" 381 "B & G" 384 "Rose Point Navigation Systems" 385 "Johnson Outdoors Marine Electronics Inc Geonav" 394 "Capi 2" 396 "Beyond Measure" 400 "Livorsi Marine" 404 "ComNav" 409 "Chetco" 419 "Fusion Electronics" 421 "Standard Horizon" 422 "True Heading" 426 "Egersund Marine Electronics" 427 "em-trak Marine Electronics" 431 "Tohatsu Co, JP" 437 "Digital Yacht" 438 "Comar Systems Limited" 440 "Cummins" 443 "VDO (aka Continental-Corporation)" 451 "Parker Hannifin aka Village Marine Tech" 459 "Alltek Marine Electronics" 460 "SAN GIORGIO S.E.I.N" 466 "Veethree Electronics & Marine" 470 "SI-TEX Marine Electronics" 471 "Sea Cross Marine" 475 "GME aka Standard Communications" 476 "Humminbird Marine Electronics" 478 "Ocean Sat" 481 "Chetco Digital Instruments" 493 "Watcheye" 499 "Lcj Capteurs" 502 "Attwood Marine" 503 "Naviop S.R.L." 504 "Vesper Marine" 510 "Marinesoft" 513 "Simarine" 517 "NoLand Engineering" 518 "Transas USA" 529 "National Instruments Korea" 530 "National Marine Electronics Association" 532 "Onwa Marine" 540 "Webasto" 571 "Marinecraft (South Korea)" 573 "McMurdo Group aka Orolia" 578 "Advansea" 579 "KVH" 580 "San Jose Technology" 583 "Yacht Control" 586 "Suzuki Motor" 591 "US Coast Guard" 595 "Ship Module aka Customware" 600 "Aquatic AV" 605 "Aventics" 606 "Intellian" 612 "SamwonIT" 614 "Arlt Tecnologies" 637 "Bavaria Yachts" 641 "Diverse Yacht Services" 644 "Wema U.S.A dba KUS" 658 "Shenzhen Jiuzhou Himunication" 688 "Rockford" 699 "Harman International" 704 "JL Audio" 708 "Lars Thrane" 715 "Autonnic" 717 "Yacht Devices" 734 "REAP Systems" 735 "AEM Performance Electronics" 739 "LxNav" 741 "Littelfuse, Inc (formerly Carling Technologies)" 743 "DaeMyung" 744 "Woosung" 748 "ISOTTA IFRA srl" 773 "Clarion US" 776 "HMI Systems" 777 "Ocean Signal" 778 "Seakeeper" 781 "Poly Planar" 785 "Fischer Panda DE" 795 "Broyda Industries" 796 "Canadian Automotive" 797 "Tides Marine" 798 "Lumishore" 799 "Still Water Designs and Audio" 802 "BJ Technologies (Beneteau)" 803 "Gill Sensors" 811 "Blue Water Desalination" 815 "FLIR" 824 "Undheim Systems" 826 "Lewmar" 838 "TeamSurv" 844 "Fell Marine" 847 "Oceanvolt" 862 "Prospec" 868 "Data Panel" 890 "L3 Technologies" 894 "Rhodan Marine Systems" 896 "Nexfour Solutions" 905 "ASA Electronics" 909 "Marines Co (South Korea)" 911 "Nautic-on" 917 "Sentinel" 929 "JL Marine Systems" 930 "Ecotronix" 944 "Zontisa Marine" 951 "EXOR International" 962 "Timbolier Industries" 963 "TJC Micro" 968 "Cox Powertrain" 969 "Blue Seas" 981 "Kobelt Manufacturing" 992 "Blue Ocean IOT" 997 "Xenta Systems" 999 "Signal K" 1004 "Ultraflex" 1008 "Lintest SmartBoat" 1011 "Soundmax" 1020 "Team Italia Marine (Onyx Marine Automation s.r.l)" 1021 "Entratech" 1022 "ITC" 1029 "The Marine Guardian" 1047 "Sonic" 1051 "ProNav" 1053 "Vetus Maxwell INC." 1056 "Lithium Pros" 1059 "Boatrax" 1062 "Marol Co ltd" 1065 "CALYPSO Instruments" 1066 "Spot Zero Water" 1069 "Lithionics Battery" 1070 "Quick-teck Electronics" 1075 "Uniden America" 1083 "Nauticoncept" 1084 "Shadow-Caster LED lighting" 1085 "Wet Sounds" 1088 "E-T-A Circuit Breakers" 1092 "Scheiber" 1100 "Smart Yachts International Limited" 1109 "Dockmate" 1114 "Bobs Machine" 1118 "L3Harris ASV" 1119 "Balmar" 1120 "Elettromedia" 1127 "Electromaax" 1140 "Across Oceans Systems" 1145 "Kiwi Yachting" 1150 "BSB Artificial Intelligence" 1151 "Orca Technologies" 1154 "TBS Electronics" 1158 "Technoton Electroics" 1160 "MG Energy Systems" 1169 "Sea Machine Robotics" 1171 "Vista Manufacturing" 1183 "Zipwake" 1186 "Sailmon" 1192 "Airmoniq Pro Kft" 1194 "Sierra Marine" 1200 "Xinuo Information Technology (Xiamen)" 1218 "Septentrio" 1233 "NKE Marine Electronics" 1238 "SuperTrack Aps" 1239 "Honda Electronics" 1245 "Raritan Engineering" 1249 "Integrated Power Solutions AG" 1260 "Interactive Technologies" 1283 "LTG-Tech" 1299 "Energy Solutions (UK)" 1300 "WATT Fuel Cell" 1302 "Pro Mainer" 1305 "Dragonfly Energy" 1306 "Koden Electronics" 1311 "Humphree" 1316 "Hinkley Yachts" 1317 "Global Marine Management GmbH (GMM)" 1320 "Triskel Marine" 1330 "Warwick Control Technologies" 1331 "Dolphin Charger" 1337 "Barnacle Systems" 1348 "Radian IoT" 1353 "Ocean LED Marine" 1359 "BluNav" 1361 "OVA (Nantong Saiyang Electronics Co., Ltd)" 1368 "RAD Propulsion" 1369 "Electric Yacht" 1372 "Elco Motor Yachts" 1384 "Tecnoseal Foundry S.r.l" 1385 "Pro Charging Systems" 1389 "EVEX" 1398 "Gobius Sensor Technology" 1403 "Arco Marine" 1408 "Lenco Marine" 1413 "Naocontrol" 1417 "Revatek" 1438 "Aeolionics" 1439 "PredictWind" 1440 "Egis Mobile Electric" 1445 "Starboard Yacht Group" 1446 "Roswell Marine" 1451 "ePropulsion (Guangdong ePropulsion Technology Ltd.)" 1452 "Micro-Air" 1453 "Vital Battery" 1458 "Ride Controller" 1460 "Tocaro Blue" 1461 "Vanquish Yachts" 1471 "FT Technologies" 1478 "Alps Alpine" 1481 "E-Force Marine" 1482 "CMC Marine" 1483 "Nanjing Sandemarine Information Technology" 1850 "Teleflex Marine (SeaStar Solutions)" 1851 "Raymarine" 1852 "Navionics" 1853 "Japan Radio" 1854 "Northstar Technologies" 1855 "Furuno" 1856 "Trimble" 1857 "Simrad" 1858 "Litton" 1859 "Kvasar" 1860 "MMP" 1861 "Vector Cantech" 1862 "Yamaha Marine" 1863 "Faria Instruments" ;
VAL_ 2650734592 Industry_Code 0 "Global" 1 "Highway" 2 "Agriculture" 3 "Construction" 4 "Marine Industry" 5 "Industrial" ;
VAL_ 2650734592 Proprietary_ID 1 "Init #2" 4 "AM Radio" 5 "Zone Info" 6 "Source" 8 "Source List" 9 "Control" 12 "FM Radio" 13 "Playlist" 14 "Track" 15 "Artist" 16 "Album" 19 "Menu Item" 20 "Zones" 23 "Max Volume" 24 "Volume" 25 "Init #1" 48 "Position" 50 "Init #3" ;
VAL_ 2650734592 Control 0 "Set" 128 "Ack" ;
VAL_ 2650734592 Manufacturer_Code 69 "ARKS Enterprises" 78 "FW Murphy/Enovation Controls" 80 "Twin Disc" 85 "Kohler Power Systems" 88 "Hemisphere GPS" 135 "Airmar" 137 "Maretron" 140 "Lowrance" 144 "Mercury Marine" 147 "Nautibus Electronic" 148 "Blue Water Data" 154 "Westerbeke" 157 "ISSPRO" 161 "Offshore Systems (UK)" 163 "Evinrude/BRP" 165 "CPAC Systems" 168 "Xantrex Technology" 169 "Marlin Technologies" 172 "Yanmar Marine" 174 "Volvo Penta" 176 "Carling Technologies Inc. (Moritz Aerospace)" 185 "Beede Instruments" 192 "Floscan Instrument" 193 "Nobeltec" 198 "Mystic Valley Communications" 199 "Actia" 201 "Disenos Y Technologia" 211 "Digital Switching Systems" 215 "Xintex/Atena" 224 "EMMI NETWORK" 228 "ZF" 229 "Garmin" 233 "Yacht Monitoring Solutions" 235 "Sailormade Marine Telemetry/Tetra Technology" 243 "Eride" 257 "Honda Motor" 272 "Groco" 273 "Actisense" 274 "Amphenol LTW Technology" 275 "Navico" 283 "Hamilton Jet" 285 "Sea Recovery" 286 "Coelmo SRL Italy" 295 "BEP Marine" 304 "Empir Bus" 305 "NovAtel" 306 "Sleipner Motor" 307 "MBW Technologies" 315 "ICOM" 328 "Qwerty" 329 "Dief" 341 "Boening Automationstechnologie" 345 "Korean Maritime University" 351 "Thrane and Thrane" 355 "Mastervolt" 356 "Fischer Panda Generators" 358 "Victron Energy" 370 "Rolls Royce Marine" 373 "Electronic Design" 374 "Northern Lights" 378 "Glendinning" 381 "B & G" 384 "Rose Point Navigation Systems" 385 "Johnson Outdoors Marine Electronics Inc Geonav" 394 "Capi 2" 396 "Beyond Measure" 400 "Livorsi Marine" 404 "ComNav" 409 "Chetco" 419 "Fusion Electronics" 421 "Standard Horizon" 422 "True Heading" 426 "Egersund Marine Electronics" 427 "em-trak Marine Electronics" 431 "Tohatsu Co, JP" 437 "Digital Yacht" 438 "Comar Systems Limited" 440 "Cummins" 443 "VDO (aka Continental-Corporation)" 451 "Parker Hannifin aka Village Marine Tech" 459 "Alltek Marine Electronics" 460 "SAN GIORGIO S.E.I.N" 466 "Veethree Electronics & Marine" 470 "SI-TEX Marine Electronics" 471 "Sea Cross Marine" 475 "GME aka Standard Communications" 476 "Humminbird Marine Electronics" 478 "Ocean Sat" 481 "Chetco Digital Instruments" 493 "Watcheye" 499 "Lcj Capteurs" 502 "Attwood Marine" 503 "Naviop S.R.L." 504 "Vesper Marine" 510 "Marinesoft" 513 "Simarine" 517 "NoLand Engineering" 518 "Transas USA" 529 "National Instruments Korea" 530 "National Marine Electronics Association" 532 "Onwa Marine" 540 "Webasto" 571 "Marinecraft (South Korea)" 573 "McMurdo Group aka Orolia" 578 "Advansea" 579 "KVH" 580 "San Jose Technology" 583 "Yacht Control" 586 "Suzuki Motor" 591 "US Coast Guard" 595 "Ship Module aka Customware" 600 "Aquatic AV" 605 "Aventics" 606 "Intellian" 612 "SamwonIT" 614 "Arlt Tecnologies" 637 "Bavaria Yachts" 641 "Diverse Yacht Services" 644 "Wema U.S.A dba KUS" 658 "Shenzhen Jiuzhou Himunication" 688 "Rockford" 699 "Harman International" 704 "JL Audio" 708 "Lars Thrane" 715 "Autonnic" 717 "Yacht Devices" 734 "REAP Systems" 735 "AEM Performance Electronics" 739 "LxNav" 741 "Littelfuse, Inc (formerly Carling Technologies)" 743 "DaeMyung" 744 "Woosung" 748 "ISOTTA IFRA srl" 773 "Clarion US" 776 "HMI Systems" 777 "Ocean Signal" 778 "Seakeeper" 781 "Poly Planar" 785 "Fischer Panda DE" 795 "Broyda Industries" 796 "Canadian Automotive" 797 "Tides Marine" 798 "Lumishore" 799 "Still Water Designs and Audio" 802 "BJ Technologies (Beneteau)" 803 "Gill Sensors" 811 "Blue Water Desalination" 815 "FLIR" 824 "Undheim Systems" 826 "Lewmar" 838 "TeamSurv" 844 "Fell Marine" 847 "Oceanvolt" 862 "Prospec" 868 "Data Panel" 890 "L3 Technologies" 894 "Rhodan Marine Systems" 896 "Nexfour Solutions" 905 "ASA Electronics" 909 "Marines Co (South Korea)" 911 "Nautic-on" 917 "Sentinel" 929 "JL Marine Systems" 930 "Ecotronix" 944 "Zontisa Marine" 951 "EXOR International" 962 "Timbolier Industries" 963 "TJC Micro" 968 "Cox Powertrain" 969 "Blue Seas" 981 "Kobelt Manufacturing" 992 "Blue Ocean IOT" 997 "Xenta Systems" 999 "Signal K" 1004 "Ultraflex" 1008 "Lintest SmartBoat" 1011 "Soundmax" 1020 "Team Italia Marine (Onyx Marine Automation s.r.l)" 1021 "Entratech" 1022 "ITC" 1029 "The Marine Guardian" 1047 "Sonic" 1051 "ProNav" 1053 "Vetus Maxwell INC." 1056 "Lithium Pros" 1059 "Boatrax" 1062 "Marol Co ltd" 1065 "CALYPSO Instruments" 1066 "Spot Zero Water" 1069 "Lithionics Battery" 1070 "Quick-teck Electronics" 1075 "Uniden America" 1083 "Nauticoncept" 1084 "Shadow-Caster LED lighting" 1085 "Wet Sounds" 1088 "E-T-A Circuit Breakers" 1092 "Scheiber" 1100 "Smart Yachts International Limited" 1109 "Dockmate" 1114 "Bobs Machine" 1118 "L3Harris ASV" 1119 "Balmar" 1120 "Elettromedia" 1127 "Electromaax" 1140 "Across Oceans Systems" 1145 "Kiwi Yachting" 1150 "BSB Artificial Intelligence" 1151 "Orca Technologies" 1154 "TBS Electronics" 1158 "Technoton Electroics" 1160 "MG Energy Systems" 1169 "Sea Machine Robotics" 1171 "Vista Manufacturing" 1183 "Zipwake" 1186 "Sailmon" 1192 "Airmoniq Pro Kft" 1194 "Sierra Marine" 1200 "Xinuo Information Technology (Xiamen)" 1218 "Septentrio" 1233 "NKE Marine Electronics" 1238 "SuperTrack Aps" 1239 "Honda Electronics" 1245 "Raritan Engineering" 1249 "Integrated Power Solutions AG" 1260 "Interactive Technologies" 1283 "LTG-Tech" 1299 "Energy Solutions (UK)" 1300 "WATT Fuel Cell" 1302 "Pro Mainer" 1305 "Dragonfly Energy" 1306 "Koden Electronics" 1311 "Humphree" 1316 "Hinkley Yachts" 1317 "Global Marine Management GmbH (GMM)" 1320 "Triskel Marine" 1330 "Warwick Control Technologies" 1331 "Dolphin Charger" 1337 "Barnacle Systems" 1348 "Radian IoT" 1353 "Ocean LED Marine" 1359 "BluNav" 1361 "OVA (Nantong Saiyang Electronics Co., Ltd)" 1368 "RAD Propulsion" 1369 "Electric Yacht" 1372 "Elco Motor Yachts" 1384 "Tecnoseal Foundry S.r.l" 1385 "Pro Charging Systems" 1389 "EVEX" 1398 "Gobius Sensor Technology" 1403 "Arco Marine" 1408 "Lenco Marine" 1413 "Naocontrol" 1417 "Revatek" 1438 "Aeolionics" 1439 "PredictWind" 1440 "Egis Mobile Electric" 1445 "Starboard Yacht Group" 1446 "Roswell Marine" 1451 "ePropulsion (Guangdong ePropulsion Technology Ltd.)" 1452 "Micro-Air" 1453 "Vital Battery" 1458 "Ride Controller" 1460 "Tocaro Blue" 1461 "Vanquish Yachts" 1471 "FT Technologies" 1478 "Alps Alpine" 1481 "E-Force Marine" 1482 "CMC Marine" 1483 "Nanjing Sandemarine Information Technology" 1850 "Teleflex Marine (SeaStar Solutions)" 1851 "Raymarine" 1852 "Navionics" 1853 "Japan Radio" 1854 "Northstar Technologies" 1855 "Furuno" 1856 "Trimble" 1857 "Simrad" 1858 "Litton" 1859 "Kvasar" 1860 "MMP" 1861 "Vector Cantech" 1862 "Yamaha Marine" 1863 "Faria Instruments" ;
VAL_ 2650734592 Industry_Code 0 "Global" 1 "Highway" 2 "Agriculture" 3 "Construction" 4 "Marine Industry" 5 "Industrial" ;
VAL_ 2650734592 Proprietary_ID 1 "Init #2" 4 "AM Radio" 5 "Zone Info" 6 "Source" 8 "Source List" 9 "Control" 12 "FM Radio" 13 "Playlist" 14 "Track" 15 "Artist" 16 "Album" 19 "Menu Item" 20 "Zones" 23 "Max Volume" 24 "Volume" 25 "Init #1" 48 "Position" 50 "Init #3" ;
VAL_ 2650734592 Control 0 "Set" 128 "Ack" ;
VAL_ 2650734592 Item 1 "Report" 4 "Next song" 6 "Previous song" ;
VAL_ 2650734592 Manufacturer_Code 69 "ARKS Enterprises" 78 "FW Murphy/Enovation Controls" 80 "Twin Disc" 85 "Kohler Power Systems" 88 "Hemisphere GPS" 135 "Airmar" 137 "Maretron" 140 "Lowrance" 144 "Mercury Marine" 147 "Nautibus Electronic" 148 "Blue Water Data" 154 "Westerbeke" 157 "ISSPRO" 161 "Offshore Systems (UK)" 163 "Evinrude/BRP" 165 "CPAC Systems" 168 "Xantrex Technology" 169 "Marlin Technologies" 172 "Yanmar Marine" 174 "Volvo Penta" 176 "Carling Technologies Inc. (Moritz Aerospace)" 185 "Beede Instruments" 192 "Floscan Instrument" 193 "Nobeltec" 198 "Mystic Valley Communications" 199 "Actia" 201 "Disenos Y Technologia" 211 "Digital Switching Systems" 215 "Xintex/Atena" 224 "EMMI NETWORK" 228 "ZF" 229 "Garmin" 233 "Yacht Monitoring Solutions" 235 "Sailormade Marine Telemetry/Tetra Technology" 243 "Eride" 257 "Honda Motor" 272 "Groco" 273 "Actisense" 274 "Amphenol LTW Technology" 275 "Navico" 283 "Hamilton Jet" 285 "Sea Recovery" 286 "Coelmo SRL Italy" 295 "BEP Marine" 304 "Empir Bus" 305 "NovAtel" 306 "Sleipner Motor" 307 "MBW Technologies" 315 "ICOM" 328 "Qwerty" 329 "Dief" 341 "Boening Automationstechnologie" 345 "Korean Maritime University" 351 "Thrane and Thrane" 355 "Mastervolt" 356 "Fischer Panda Generators" 358 "Victron Energy" 370 "Rolls Royce Marine" 373 "Electronic Design" 374 "Northern Lights" 378 "Glendinning" 381 "B & G" 384 "Rose Point Navigation Systems" 385 "Johnson Outdoors Marine Electronics Inc Geonav" 394 "Capi 2" 396 "Beyond Measure" 400 "Livorsi Marine" 404 "ComNav" 409 "Chetco" 419 "Fusion Electronics" 421 "Standard Horizon" 422 "True Heading" 426 "Egersund Marine Electronics" 427 "em-trak Marine Electronics" 431 "Tohatsu Co, JP" 437 "Digital Yacht" 438 "Comar Systems Limited" 440 "Cummins" 443 "VDO (aka Continental-Corporation)" 451 "Parker Hannifin aka Village Marine Tech" 459 "Alltek Marine Electronics" 460 "SAN GIORGIO S.E.I.N" 466 "Veethree Electronics & Marine" 470 "SI-TEX Marine Electronics" 471 "Sea Cross Marine" 475 "GME aka Standard Communications" 476 "Humminbird Marine Electronics" 478 "Ocean Sat" 481 "Chetco Digital Instruments" 493 "Watcheye" 499 "Lcj Capteurs" 502 "Attwood Marine" 503 "Naviop S.R.L." 504 "Vesper Marine" 510 "Marinesoft" 513 "Simarine" 517 "NoLand Engineering" 518 "Transas USA" 529 "National Instruments Korea" 530 "National Marine Electronics Association" 532 "Onwa Marine" 540 "Webasto" 571 "Marinecraft (South Korea)" 573 "McMurdo Group aka Orolia" 578 "Advansea" 579 "KVH" 580 "San Jose Technology" 583 "Yacht Control" 586 "Suzuki Motor" 591 "US Coast Guard" 595 "Ship Module aka Customware" 600 "Aquatic AV" 605 "Aventics" 606 "Intellian" 612 "SamwonIT" 614 "Arlt Tecnologies" 637 "Bavaria Yachts" 641 "Diverse Yacht Services" 644 "Wema U.S.A dba KUS" 658 "Shenzhen Jiuzhou Himunication" 688 "Rockford" 699 "Harman International" 704 "JL Audio" 708 "Lars Thrane" 715 "Autonnic" 717 "Yacht Devices" 734 "REAP Systems" 735 "AEM Performance Electronics" 739 "LxNav" 741 "Littelfuse, Inc (formerly Carling Technologies)" 743 "DaeMyung" 744 "Woosung" 748 "ISOTTA IFRA srl" 773 "Clarion US" 776 "HMI Systems" 777 "Ocean Signal" 778 "Seakeeper" 781 "Poly Planar" 785 "Fischer Panda DE" 795 "Broyda Industries" 796 "Canadian Automotive" 797 "Tides Marine" 798 "Lumishore" 799 "Still Water Designs and Audio" 802 "BJ Technologies (Beneteau)" 803 "Gill Sensors" 811 "Blue Water Desalination" 815 "FLIR" 824 "Undheim Systems" 826 "Lewmar" 838 "TeamSurv" 844 "Fell Marine" 847 "Oceanvolt" 862 "Prospec" 868 "Data Panel" 890 "L3 Technologies" 894 "Rhodan Marine Systems" 896 "Nexfour Solutions" 905 "ASA Electronics" 909 "Marines Co (South Korea)" 911 "Nautic-on" 917 "Sentinel" 929 "JL Marine Systems" 930 "Ecotronix" 944 "Zontisa Marine" 951 "EXOR International" 962 "Timbolier Industries" 963 "TJC Micro" 968 "Cox Powertrain" 969 "Blue Seas" 981 "Kobelt Manufacturing" 992 "Blue Ocean IOT" 997 "Xenta Systems" 999 "Signal K" 1004 "Ultraflex" 1008 "Lintest SmartBoat" 1011 "Soundmax" 1020 "Team Italia Marine (Onyx Marine Automation s.r.l)" 1021 "Entratech" 1022 "ITC" 1029 "The Marine Guardian" 1047 "Sonic" 1051 "ProNav" 1053 "Vetus Maxwell INC." 1056 "Lithium Pros" 1059 "Boatrax" 1062 "Marol Co ltd" 1065 "CALYPSO Instruments" 1066 "Spot Zero Water" 1069 "Lithionics Battery" 1070 "Quick-teck Electronics" 1075 "Uniden America" 1083 "Nauticoncept" 1084 "Shadow-Caster LED lighting" 1085 "Wet Sounds" 1088 "E-T-A Circuit Breakers" 1092 "Scheiber" 1100 "Smart Yachts International Limited" 1109 "Dockmate" 1114 "Bobs Machine" 1118 "L3Harris ASV" 1119 "Balmar" 1120 "Elettromedia" 1127 "Electromaax" 1140 "Across Oceans Systems" 1145 "Kiwi Yachting" 1150 "BSB Artificial Intelligence" 1151 "Orca Technologies" 1154 "TBS Electronics" 1158 "Technoton Electroics" 1160 "MG Energy Systems" 1169 "Sea Machine Robotics" 1171 "Vista Manufacturing" 1183 "Zipwake" 1186 "Sailmon" 1192 "Airmoniq Pro Kft" 1194 "Sierra Marine" 1200 "Xinuo Information Technology (Xiamen)" 1218 "Septentrio" 1233 "NKE Marine Electronics" 1238 "SuperTrack Aps" 1239 "Honda Electronics" 1245 "Raritan Engineering" 1249 "Integrated Power Solutions AG" 1260 "Interactive Technologies" 1283 "LTG-Tech" 1299 "Energy Solutions (UK)" 1300 "WATT Fuel Cell" 1302 "Pro Mainer" 1305 "Dragonfly Energy" 1306 "Koden Electronics" 1311 "Humphree" 1316 "Hinkley Yachts" 1317 "Global Marine Management GmbH (GMM)" 1320 "Triskel Marine" 1330 "Warwick Control Technologies" 1331 "Dolphin Charger" 1337 "Barnacle Systems" 1348 "Radian IoT" 1353 "Ocean LED Marine" 1359 "BluNav" 1361 "OVA (Nantong Saiyang Electronics Co., Ltd)" 1368 "RAD Propulsion" 1369 "Electric Yacht" 1372 "Elco Motor Yachts" 1384 "Tecnoseal Foundry S.r.l" 1385 "Pro Charging Systems" 1389 "EVEX" 1398 "Gobius Sensor Technology" 1403 "Arco Marine" 1408 "Lenco Marine" 1413 "Naocontrol" 1417 "Revatek" 1438 "Aeolionics" 1439 "PredictWind" 1440 "Egis Mobile Electric" 1445 "Starboard Yacht Group" 1446 "Roswell Marine" 1451 "ePropulsion (Guangdong ePropulsion Technology Ltd.)" 1452 "Micro-Air" 1453 "Vital Battery" 1458 "Ride Controller" 1460 "Tocaro Blue" 1461 "Vanquish Yachts" 1471 "FT Technologies" 1478 "Alps Alpine" 1481 "E-Force Marine" 1482 "CMC Marine" 1483 "Nanjing Sandemarine Information Technology" 1850 "Teleflex Marine (SeaStar Solutions)" 1851 "Raymarine" 1852 "Navionics" 1853 "Japan Radio" 1854 "Northstar Technologies" 1855 "Furuno" 1856 "Trimble" 1857 "Simrad" 1858 "Litton" 1859 "Kvasar" 1860 "MMP" 1861 "Vector Cantech" 1862 "Yamaha Marine" 1863 "Faria Instruments" ;
VAL_ 2650734592 Industry_Code 0 "Global" 1 "Highway" 2 "Agriculture" 3 "Construction" 4 "Marine Industry" 5 "Industrial" ;
VAL_ 2650734592 Proprietary_ID 1 "Init #2" 4 "AM Radio" 5 "Zone Info" 6 "Source" 8 "Source List" 9 "Control" 12 "FM Radio" 13 "Playlist" 14 "Track" 15 "Artist" 16 "Album" 19 "Menu Item" 20 "Zones" 23 "Max Volume" 24 "Volume" 25 "Init #1" 48 "Position" 50 "Init #3" ;
VAL_ 2650734592 Control 0 "Set" 128 "Ack" ;
VAL_ 2650734592 Manufacturer_Code 69 "ARKS Enterprises" 78 "FW Murphy/Enovation Controls" 80 "Twin Disc" 85 "Kohler Power Systems" 88 "Hemisphere GPS" 135 "Airmar" 137 "Maretron" 140 "Lowrance" 144 "Mercury Marine" 147 "Nautibus Electronic" 148 "Blue Water Data" 154 "Westerbeke" 157 "ISSPRO" 161 "Offshore Systems (UK)" 163 "Evinrude/BRP" 165 "CPAC Systems" 168 "Xantrex Technology" 169 "Marlin Technologies" 172 "Yanmar Marine" 174 "Volvo Penta" 176 "Carling Technologies Inc. (Moritz Aerospace)" 185 "Beede Instruments" 192 "Floscan Instrument" 193 "Nobeltec" 198 "Mystic Valley Communications" 199 "Actia" 201 "Disenos Y Technologia" 211 "Digital Switching Systems" 215 "Xintex/Atena" 224 "EMMI NETWORK" 228 "ZF" 229 "Garmin" 233 "Yacht Monitoring Solutions" 235 "Sailormade Marine Telemetry/Tetra Technology" 243 "Eride" 257 "Honda Motor" 272 "Groco" 273 "Actisense" 274 "Amphenol LTW Technology" 275 "Navico" 283 "Hamilton Jet" 285 "Sea Recovery" 286 "Coelmo SRL Italy" 295 "BEP Marine" 304 "Empir Bus" 305 "NovAtel" 306 "Sleipner Motor" 307 "MBW Technologies" 315 "ICOM" 328 "Qwerty" 329 "Dief" 341 "Boening Automationstechnologie" 345 "Korean Maritime University" 351 "Thrane and Thrane" 355 "Mastervolt" 356 "Fischer Panda Generators" 358 "Victron Energy" 370 "Rolls Royce Marine" 373 "Electronic Design" 374 "Northern Lights" 378 "Glendinning" 381 "B & G" 384 "Rose Point Navigation Systems" 385 "Johnson Outdoors Marine Electronics Inc Geonav" 394 "Capi 2" 396 "Beyond Measure" 400 "Livorsi Marine" 404 "ComNav" 409 "Chetco" 419 "Fusion Electronics" 421 "Standard Horizon" 422 "True Heading" 426 "Egersund Marine Electronics" 427 "em-trak Marine Electronics" 431 "Tohatsu Co, JP" 437 "Digital Yacht" 438 "Comar Systems Limited" 440 "Cummins" 443 "VDO (aka Continental-Corporation)" 451 "Parker Hannifin aka Village Marine Tech" 459 "Alltek Marine Electronics" 460 "SAN GIORGIO S.E.I.N" 466 "Veethree Electronics & Marine" 470 "SI-TEX Marine Electronics" 471 "Sea Cross Marine" 475 "GME aka Standard Communications" 476 "Humminbird Marine Electronics" 478 "Ocean Sat" 481 "Chetco Digital Instruments" 493 "Watcheye" 499 "Lcj Capteurs" 502 "Attwood Marine" 503 "Naviop S.R.L." 504 "Vesper Marine" 510 "Marinesoft" 513 "Simarine" 517 "NoLand Engineering" 518 "Transas USA" 529 "National Instruments Korea" 530 "National Marine Electronics Association" 532 "Onwa Marine" 540 "Webasto" 571 "Marinecraft (South Korea)" 573 "McMurdo Group aka Orolia" 578 "Advansea" 579 "KVH" 580 "San Jose Technology" 583 "Yacht Control" 586 "Suzuki Motor" 591 "US Coast Guard" 595 "Ship Module aka Customware" 600 "Aquatic AV" 605 "Aventics" 606 "Intellian" 612 "SamwonIT" 614 "Arlt Tecnologies" 637 "Bavaria Yachts" 641 "Diverse Yacht Services" 644 "Wema U.S.A dba KUS" 658 "Shenzhen Jiuzhou Himunication" 688 "Rockford" 699 "Harman International" 704 "JL Audio" 708 "Lars Thrane" 715 "Autonnic" 717 "Yacht Devices" 734 "REAP Systems" 735 "AEM Performance Electronics" 739 "LxNav" 741 "Littelfuse, Inc (formerly Carling Technologies)" 743 "DaeMyung" 744 "Woosung" 748 "ISOTTA IFRA srl" 773 "Clarion US" 776 "HMI Systems" 777 "Ocean Signal" 778 "Seakeeper" 781 "Poly Planar" 785 "Fischer Panda DE" 795 "Broyda Industries" 796 "Canadian Automotive" 797 "Tides Marine" 798 "Lumishore" 799 "Still Water Designs and Audio" 802 "BJ Technologies (Beneteau)" 803 "Gill Sensors" 811 "Blue Water Desalination" 815 "FLIR" 824 "Undheim Systems" 826 "Lewmar" 838 "TeamSurv" 844 "Fell Marine" 847 "Oceanvolt" 862 "Prospec" 868 "Data Panel" 890 "L3 Technologies" 894 "Rhodan Marine Systems" 896 "Nexfour Solutions" 905 "ASA Electronics" 909 "Marines Co (South Korea)" 911 "Nautic-on" 917 "Sentinel" 929 "JL Marine Systems" 930 "Ecotronix" 944 "Zontisa Marine" 951 "EXOR International" 962 "Timbolier Industries" 963 "TJC Micro" 968 "Cox Powertrain" 969 "Blue Seas" 981 "Kobelt Manufacturing" 992 "Blue Ocean IOT" 997 "Xenta Systems" 999 "Signal K" 1004 "Ultraflex" 1008 "Lintest SmartBoat" 1011 "Soundmax" 1020 "Team Italia Marine (Onyx Marine Automation s.r.l)" 1021 "Entratech" 1022 "ITC" 1029 "The Marine Guardian" 1047 "Sonic" 1051 "ProNav" 1053 "Vetus Maxwell INC." 1056 "Lithium Pros" 1059 "Boatrax" 1062 "Marol Co ltd" 1065 "CALYPSO Instruments" 1066 "Spot Zero Water" 1069 "Lithionics Battery" 1070 "Quick-teck Electronics" 1075 "Uniden America" 1083 "Nauticoncept" 1084 "Shadow-Caster LED lighting" 1085 "Wet Sounds" 1088 "E-T-A Circuit Breakers" 1092 "Scheiber" 1100 "Smart Yachts International Limited" 1109 "Dockmate" 1114 "Bobs Machine" 1118 "L3Harris ASV" 1119 "Balmar" 1120 "Elettromedia" 1127 "Electromaax" 1140 "Across Oceans Systems" 1145 "Kiwi Yachting" 1150 "BSB Artificial Intelligence" 1151 "Orca Technologies" 1154 "TBS Electronics" 1158 "Technoton Electroics" 1160 "MG Energy Systems" 1169 "Sea Machine Robotics" 1171 "Vista Manufacturing" 1183 "Zipwake" 1186 "Sailmon" 1192 "Airmoniq Pro Kft" 1194 "Sierra Marine" 1200 "Xinuo Information Technology (Xiamen)" 1218 "Septentrio" 1233 "NKE Marine Electronics" 1238 "SuperTrack Aps" 1239 "Honda Electronics" 1245 "Raritan Engineering" 1249 "Integrated Power Solutions AG" 1260 "Interactive Technologies" 1283 "LTG-Tech" 1299 "Energy Solutions (UK)" 1300 "WATT Fuel Cell" 1302 "Pro Mainer" 1305 "Dragonfly Energy" 1306 "Koden Electronics" 1311 "Humphree" 1316 "Hinkley Yachts" 1317 "Global Marine Management GmbH (GMM)" 1320 "Triskel Marine" 1330 "Warwick Control Technologies" 1331 "Dolphin Charger" 1337 "Barnacle Systems" 1348 "Radian IoT" 1353 "Ocean LED Marine" 1359 "BluNav" 1361 "OVA (Nantong Saiyang Electronics Co., Ltd)" 1368 "RAD Propulsion" 1369 "Electric Yacht" 1372 "Elco Motor Yachts" 1384 "Tecnoseal Foundry S.r.l" 1385 "Pro Charging Systems" 1389 "EVEX" 1398 "Gobius Sensor Technology" 1403 "Arco Marine" 1408 "Lenco Marine" 1413 "Naocontrol" 1417 "Revatek" 1438 "Aeolionics" 1439 "PredictWind" 1440 "Egis Mobile Electric" 1445 "Starboard Yacht Group" 1446 "Roswell Marine" 1451 "ePropulsion (Guangdong ePropulsion Technology Ltd.)" 1452 "Micro-Air" 1453 "Vital Battery" 1458 "Ride Controller" 1460 "Tocaro Blue" 1461 "Vanquish Yachts" 1471 "FT Technologies" 1478 "Alps Alpine" 1481 "E-Force Marine" 1482 "CMC Marine" 1483 "Nanjing Sandemarine Information Technology" 1850 "Teleflex Marine (SeaStar Solutions)" 1851 "Raymarine" 1852 "Navionics" 1853 "Japan Radio" 1854 "Northstar Technologies" 1855 "Furuno" 1856 "Trimble" 1857 "Simrad" 1858 "Litton" 1859 "Kvasar" 1860 "MMP" 1861 "Vector Cantech" 1862 "Yamaha Marine" 1863 "Faria Instruments" ;
VAL_ 2650734592 Industry_Code 0 "Global" 1 "Highway" 2 "Agriculture" 3 "Construction" 4 "Marine Industry" 5 "Industrial" ;
VAL_ 2650734592 Proprietary_ID 1 "Init #2" 4 "AM Radio" 5 "Zone Info" 6 "Source" 8 "Source List" 9 "Control" 12 "FM Radio" 13 "Playlist" 14 "Track" 15 "Artist" 16 "Album" 19 "Menu Item" 20 "Zones" 23 "Max Volume" 24 "Volume" 25 "Init #1" 48 "Position" 50 "Init #3" ;
VAL_ 2650734592 Control 0 "Set" 128 "Ack" ;
VAL_ 2650734592 Source 0 "AM" 1 "FM" 2 "iPod" 3 "USB" 4 "AUX" 5 "AUX 2" 6 "Mic" ;
VAL_ 2650734592 Manufacturer_Code 69 "ARKS Enterprises" 78 "FW Murphy/Enovation Controls" 80 "Twin Disc" 85 "Kohler Power Systems" 88 "Hemisphere GPS" 135 "Airmar" 137 "Maretron" 140 "Lowrance" 144 "Mercury Marine" 147 "Nautibus Electronic" 148 "Blue Water Data" 154 "Westerbeke" 157 "ISSPRO" 161 "Offshore Systems (UK)" 163 "Evinrude/BRP" 165 "CPAC Systems" 168 "Xantrex Technology" 169 "Marlin Technologies" 172 "Yanmar Marine" 174 "Volvo Penta" 176 "Carling Technologies Inc. (Moritz Aerospace)" 185 "Beede Instruments" 192 "Floscan Instrument" 193 "Nobeltec" 198 "Mystic Valley Communications" 199 "Actia" 201 "Disenos Y Technologia" 211 "Digital Switching Systems" 215 "Xintex/Atena" 224 "EMMI NETWORK" 228 "ZF" 229 "Garmin" 233 "Yacht Monitoring Solutions" 235 "Sailormade Marine Telemetry/Tetra Technology" 243 "Eride" 257 "Honda Motor" 272 "Groco" 273 "Actisense" 274 "Amphenol LTW Technology" 275 "Navico" 283 "Hamilton Jet" 285 "Sea Recovery" 286 "Coelmo SRL Italy" 295 "BEP Marine" 304 "Empir Bus" 305 "NovAtel" 306 "Sleipner Motor" 307 "MBW Technologies" 315 "ICOM" 328 "Qwerty" 329 "Dief" 341 "Boening Automationstechnologie" 345 "Korean Maritime University" 351 "Thrane and Thrane" 355 "Mastervolt" 356 "Fischer Panda Generators" 358 "Victron Energy" 370 "Rolls Royce Marine" 373 "Electronic Design" 374 "Northern Lights" 378 "Glendinning" 381 "B & G" 384 "Rose Point Navigation Systems" 385 "Johnson Outdoors Marine Electronics Inc Geonav" 394 "Capi 2" 396 "Beyond Measure" 400 "Livorsi Marine" 404 "ComNav" 409 "Chetco" 419 "Fusion Electronics" 421 "Standard Horizon" 422 "True Heading" 426 "Egersund Marine Electronics" 427 "em-trak Marine Electronics" 431 "Tohatsu Co, JP" 437 "Digital Yacht" 438 "Comar Systems Limited" 440 "Cummins" 443 "VDO (aka Continental-Corporation)" 451 "Parker Hannifin aka Village Marine Tech" 459 "Alltek Marine Electronics" 460 "SAN GIORGIO S.E.I.N" 466 "Veethree Electronics & Marine" 470 "SI-TEX Marine Electronics" 471 "Sea Cross Marine" 475 "GME aka Standard Communications" 476 "Humminbird Marine Electronics" 478 "Ocean Sat" 481 "Chetco Digital Instruments" 493 "Watcheye" 499 "Lcj Capteurs" 502 "Attwood Marine" 503 "Naviop S.R.L." 504 "Vesper Marine" 510 "Marinesoft" 513 "Simarine" 517 "NoLand Engineering" 518 "Transas USA" 529 "National Instruments Korea" 530 "National Marine Electronics Association" 532 "Onwa Marine" 540 "Webasto" 571 "Marinecraft (South Korea)" 573 "McMurdo Group aka Orolia" 578 "Advansea" 579 "KVH" 580 "San Jose Technology" 583 "Yacht Control" 586 "Suzuki Motor" 591 "US Coast Guard" 595 "Ship Module aka Customware" 600 "Aquatic AV" 605 "Aventics" 606 "Intellian" 612 "SamwonIT" 614 "Arlt Tecnologies" 637 "Bavaria Yachts" 641 "Diverse Yacht Services" 644 "Wema U.S.A dba KUS" 658 "Shenzhen Jiuzhou Himunication" 688 "Rockford" 699 "Harman International" 704 "JL Audio" 708 "Lars Thrane" 715 "Autonnic" 717 "Yacht Devices" 734 "REAP Systems" 735 "AEM Performance Electronics" 739 "LxNav" 741 "Littelfuse, Inc (formerly Carling Technologies)" 743 "DaeMyung" 744 "Woosung" 748 "ISOTTA IFRA srl" 773 "Clarion US" 776 "HMI Systems" 777 "Ocean Signal" 778 "Seakeeper" 781 "Poly Planar" 785 "Fischer Panda DE" 795 "Broyda Industries" 796 "Canadian Automotive" 797 "Tides Marine" 798 "Lumishore" 799 "Still Water Designs and Audio" 802 "BJ Technologies (Beneteau)" 803 "Gill Sensors" 811 "Blue Water Desalination" 815 "FLIR" 824 "Undheim Systems" 826 "Lewmar" 838 "TeamSurv" 844 "Fell Marine" 847 "Oceanvolt" 862 "Prospec" 868 "Data Panel" 890 "L3 Technologies" 894 "Rhodan Marine Systems" 896 "Nexfour Solutions" 905 "ASA Electronics" 909 "Marines Co (South Korea)" 911 "Nautic-on" 917 "Sentinel" 929 "JL Marine Systems" 930 "Ecotronix" 944 "Zontisa Marine" 951 "EXOR International" 962 "Timbolier Industries" 963 "TJC Micro" 968 "Cox Powertrain" 969 "Blue Seas" 981 "Kobelt Manufacturing" 992 "Blue Ocean IOT" 997 "Xenta Systems" 999 "Signal K" 1004 "Ultraflex" 1008 "Lintest SmartBoat" 1011 "Soundmax" 1020 "Team Italia Marine (Onyx Marine Automation s.r.l)" 1021 "Entratech" 1022 "ITC" 1029 "The Marine Guardian" 1047 "Sonic" 1051 "ProNav" 1053 "Vetus Maxwell INC." 1056 "Lithium Pros" 1059 "Boatrax" 1062 "Marol Co ltd" 1065 "CALYPSO Instruments" 1066 "Spot Zero Water" 1069 "Lithionics Battery" 1070 "Quick-teck Electronics" 1075 "Uniden America" 1083 "Nauticoncept" 1084 "Shadow-Caster LED lighting" 1085 "Wet Sounds" 1088 "E-T-A Circuit Breakers" 1092 "Scheiber" 1100 "Smart Yachts International Limited" 1109 "Dockmate" 1114 "Bobs Machine" 1118 "L3Harris ASV" 1119 "Balmar" 1120 "Elettromedia" 1127 "Electromaax" 1140 "Across Oceans Systems" 1145 "Kiwi Yachting" 1150 "BSB Artificial Intelligence" 1151 "Orca Technologies" 1154 "TBS Electronics" 1158 "Technoton Electroics" 1160 "MG Energy Systems" 1169 "Sea Machine Robotics" 1171 "Vista Manufacturing" 1183 "Zipwake" 1186 "Sailmon" 1192 "Airmoniq Pro Kft" 1194 "Sierra Marine" 1200 "Xinuo Information Technology (Xiamen)" 1218 "Septentrio" 1233 "NKE Marine Electronics" 1238 "SuperTrack Aps" 1239 "Honda Electronics" 1245 "Raritan Engineering" 1249 "Integrated Power Solutions AG" 1260 "Interactive Technologies" 1283 "LTG-Tech" 1299 "Energy Solutions (UK)" 1300 "WATT Fuel Cell" 1302 "Pro Mainer" 1305 "Dragonfly Energy" 1306 "Koden Electronics" 1311 "Humphree" 1316 "Hinkley Yachts" 1317 "Global Marine Management GmbH (GMM)" 1320 "Triskel Marine" 1330 "Warwick Control Technologies" 1331 "Dolphin Charger" 1337 "Barnacle Systems" 1348 "Radian IoT" 1353 "Ocean LED Marine" 1359 "BluNav" 1361 "OVA (Nantong Saiyang Electronics Co., Ltd)" 1368 "RAD Propulsion" 1369 "Electric Yacht" 1372 "Elco Motor Yachts" 1384 "Tecnoseal Foundry S.r.l" 1385 "Pro Charging Systems" 1389 "EVEX" 1398 "Gobius Sensor Technology" 1403 "Arco Marine" 1408 "Lenco Marine" 1413 "Naocontrol" 1417 "Revatek" 1438 "Aeolionics" 1439 "PredictWind" 1440 "Egis Mobile Electric" 1445 "Starboard Yacht Group" 1446 "Roswell Marine" 1451 "ePropulsion (Guangdong ePropulsion Technology Ltd.)" 1452 "Micro-Air" 1453 "Vital Battery" 1458 "Ride Controller" 1460 "Tocaro Blue" 1461 "Vanquish Yachts" 1471 "FT Technologies" 1478 "Alps Alpine" 1481 "E-Force Marine" 1482 "CMC Marine" 1483 "Nanjing Sandemarine Information Technology" 1850 "Teleflex Marine (SeaStar Solutions)" 1851 "Raymarine" 1852 "Navionics" 1853 "Japan Radio" 1854 "Northstar Technologies" 1855 "Furuno" 1856 "Trimble" 1857 "Simrad" 1858 "Litton" 1859 "Kvasar" 1860 "MMP" 1861 "Vector Cantech" 1862 "Yamaha Marine" 1863 "Faria Instruments" ;
VAL_ 2650734592 Industry_Code 0 "Global" 1 "Highway" 2 "Agriculture" 3 "Construction" 4 "Marine Industry" 5 "Industrial" ;
VAL_ 2650734592 Proprietary_ID 1 "Init #2" 4 "AM Radio" 5 "Zone Info" 6 "Source" 8 "Source List" 9 "Control" 12 "FM Radio" 13 "Playlist" 14 "Track" 15 "Artist" 16 "Album" 19 "Menu Item" 20 "Zones" 23 "Max Volume" 24 "Volume" 25 "Init #1" 48 "Position" 50 "Init #3" ;
VAL_ 2650734592 Control 0 "Set" 128 "Ack" ;
VAL_ 2650734592 Manufacturer_Code 69 "ARKS Enterprises" 78 "FW Murphy/Enovation Controls" 80 "Twin Disc" 85 "Kohler Power Systems" 88 "Hemisphere GPS" 135 "Airmar" 137 "Maretron" 140 "Lowrance" 144 "Mercury Marine" 147 "Nautibus Electronic" 148 "Blue Water Data" 154 "Westerbeke" 157 "ISSPRO" 161 "Offshore Systems (UK)" 163 "Evinrude/BRP" 165 "CPAC Systems" 168 "Xantrex Technology" 169 "Marlin Technologies" 172 "Yanmar Marine" 174 "Volvo Penta" 176 "Carling Technologies Inc. (Moritz Aerospace)" 185 "Beede Instruments" 192 "Floscan Instrument" 193 "Nobeltec" 198 "Mystic Valley Communications" 199 "Actia" 201 "Disenos Y Technologia" 211 "Digital Switching Systems" 215 "Xintex/Atena" 224 "EMMI NETWORK" 228 "ZF" 229 "Garmin" 233 "Yacht Monitoring Solutions" 235 "Sailormade Marine Telemetry/Tetra Technology" 243 "Eride" 257 "Honda Motor" 272 "Groco" 273 "Actisense" 274 "Amphenol LTW Technology" 275 "Navico" 283 "Hamilton Jet" 285 "Sea Recovery" 286 "Coelmo SRL Italy" 295 "BEP Marine" 304 "Empir Bus" 305 "NovAtel" 306 "Sleipner Motor" 307 "MBW Technologies" 315 "ICOM" 328 "Qwerty" 329 "Dief" 341 "Boening Automationstechnologie" 345 "Korean Maritime University" 351 "Thrane and Thrane" 355 "Mastervolt" 356 "Fischer Panda Generators" 358 "Victron Energy" 370 "Rolls Royce Marine" 373 "Electronic Design" 374 "Northern Lights" 378 "Glendinning" 381 "B & G" 384 "Rose Point Navigation Systems" 385 "Johnson Outdoors Marine Electronics Inc Geonav" 394 "Capi 2" 396 "Beyond Measure" 400 "Livorsi Marine" 404 "ComNav" 409 "Chetco" 419 "Fusion Electronics" 421 "Standard Horizon" 422 "True Heading" 426 "Egersund Marine Electronics" 427 "em-trak Marine Electronics" 431 "Tohatsu Co, JP" 437 "Digital Yacht" 438 "Comar Systems Limited" 440 "Cummins" 443 "VDO (aka Continental-Corporation)" 451 "Parker Hannifin aka Village Marine Tech" 459 "Alltek Marine Electronics" 460 "SAN GIORGIO S.E.I.N" 466 "Veethree Electronics & Marine" 470 "SI-TEX Marine Electronics" 471 "Sea Cross Marine" 475 "GME aka Standard Communications" 476 "Humminbird Marine Electronics" 478 "Ocean Sat" 481 "Chetco Digital Instruments" 493 "Watcheye" 499 "Lcj Capteurs" 502 "Attwood Marine" 503 "Naviop S.R.L." 504 "Vesper Marine" 510 "Marinesoft" 513 "Simarine" 517 "NoLand Engineering" 518 "Transas USA" 529 "National Instruments Korea" 530 "National Marine Electronics Association" 532 "Onwa Marine" 540 "Webasto" 571 "Marinecraft (South Korea)" 573 "McMurdo Group aka Orolia" 578 "Advansea" 579 "KVH" 580 "San Jose Technology" 583 "Yacht Control" 586 "Suzuki Motor" 591 "US Coast Guard" 595 "Ship Module aka Customware" 600 "Aquatic AV" 605 "Aventics" 606 "Intellian" 612 "SamwonIT" 614 "Arlt Tecnologies" 637 "Bavaria Yachts" 641 "Diverse Yacht Services" 644 "Wema U.S.A dba KUS" 658 "Shenzhen Jiuzhou Himunication" 688 "Rockford" 699 "Harman International" 704 "JL Audio" 708 "Lars Thrane" 715 "Autonnic" 717 "Yacht Devices" 734 "REAP Systems" 735 "AEM Performance Electronics" 739 "LxNav" 741 "Littelfuse, Inc (formerly Carling Technologies)" 743 "DaeMyung" 744 "Woosung" 748 "ISOTTA IFRA srl" 773 "Clarion US" 776 "HMI Systems" 777 "Ocean Signal" 778 "Seakeeper" 781 "Poly Planar" 785 "Fischer Panda DE" 795 "Broyda Industries" 796 "Canadian Automotive" 797 "Tides Marine" 798 "Lumishore" 799 "Still Water Designs and Audio" 802 "BJ Technologies (Beneteau)" 803 "Gill Sensors" 811 "Blue Water Desalination" 815 "FLIR" 824 "Undheim Systems" 826 "Lewmar" 838 "TeamSurv" 844 "Fell Marine" 847 "Oceanvolt" 862 "Prospec" 868 "Data Panel" 890 "L3 Technologies" 894 "Rhodan Marine Systems" 896 "Nexfour Solutions" 905 "ASA Electronics" 909 "Marines Co (South Korea)" 911 "Nautic-on" 917 "Sentinel" 929 "JL Marine Systems" 930 "Ecotronix" 944 "Zontisa Marine" 951 "EXOR International" 962 "Timbolier Industries" 963 "TJC Micro" 968 "Cox Powertrain" 969 "Blue Seas" 981 "Kobelt Manufacturing" 992 "Blue Ocean IOT" 997 "Xenta Systems" 999 "Signal K" 1004 "Ultraflex" 1008 "Lintest SmartBoat" 1011 "Soundmax" 1020 "Team Italia Marine (Onyx Marine Automation s.r.l)" 1021 "Entratech" 1022 "ITC" 1029 "The Marine Guardian" 1047 "Sonic" 1051 "ProNav" 1053 "Vetus Maxwell INC." 1056 "Lithium Pros" 1059 "Boatrax" 1062 "Marol Co ltd" 1065 "CALYPSO Instruments" 1066 "Spot Zero Water" 1069 "Lithionics Battery" 1070 "Quick-teck Electronics" 1075 "Uniden America" 1083 "Nauticoncept" 1084 "Shadow-Caster LED lighting" 1085 "Wet Sounds" 1088 "E-T-A Circuit Breakers" 1092 "Scheiber" 1100 "Smart Yachts International Limited" 1109 "Dockmate" 1114 "Bobs Machine" 1118 "L3Harris ASV" 1119 "Balmar" 1120 "Elettromedia" 1127 "Electromaax" 1140 "Across Oceans Systems" 1145 "Kiwi Yachting" 1150 "BSB Artificial Intelligence" 1151 "Orca Technologies" 1154 "TBS Electronics" 1158 "Technoton Electroics" 1160 "MG Energy Systems" 1169 "Sea Machine Robotics" 1171 "Vista Manufacturing" 1183 "Zipwake" 1186 "Sailmon" 1192 "Airmoniq Pro Kft" 1194 "Sierra Marine" 1200 "Xinuo Information Technology (Xiamen)" 1218 "Septentrio" 1233 "NKE Marine Electronics" 1238 "SuperTrack Aps" 1239 "Honda Electronics" 1245 "Raritan Engineering" 1249 "Integrated Power Solutions AG" 1260 "Interactive Technologies" 1283 "LTG-Tech" 1299 "Energy Solutions (UK)" 1300 "WATT Fuel Cell" 1302 "Pro Mainer" 1305 "Dragonfly Energy" 1306 "Koden Electronics" 1311 "Humphree" 1316 "Hinkley Yachts" 1317 "Global Marine Management GmbH (GMM)" 1320 "Triskel Marine" 1330 "Warwick Control Technologies" 1331 "Dolphin Charger" 1337 "Barnacle Systems" 1348 "Radian IoT" 1353 "Ocean LED Marine" 1359 "BluNav" 1361 "OVA (Nantong Saiyang Electronics Co., Ltd)" 1368 "RAD Propulsion" 1369 "Electric Yacht" 1372 "Elco Motor Yachts" 1384 "Tecnoseal Foundry S.r.l" 1385 "Pro Charging Systems" 1389 "EVEX" 1398 "Gobius Sensor Technology" 1403 "Arco Marine" 1408 "Lenco Marine" 1413 "Naocontrol" 1417 "Revatek" 1438 "Aeolionics" 1439 "PredictWind" 1440 "Egis Mobile Electric" 1445 "Starboard Yacht Group" 1446 "Roswell Marine" 1451 "ePropulsion (Guangdong ePropulsion Technology Ltd.)" 1452 "Micro-Air" 1453 "Vital Battery" 1458 "Ride Controller" 1460 "Tocaro Blue" 1461 "Vanquish Yachts" 1471 "FT Technologies" 1478 "Alps Alpine" 1481 "E-Force Marine" 1482 "CMC Marine" 1483 "Nanjing Sandemarine Information Technology" 1850 "Teleflex Marine (SeaStar Solutions)" 1851 "Raymarine" 1852 "Navionics" 1853 "Japan Radio" 1854 "Northstar Technologies" 1855 "Furuno" 1856 "Trimble" 1857 "Simrad" 1858 "Litton" 1859 "Kvasar" 1860 "MMP" 1861 "Vector Cantech" 1862 "Yamaha Marine" 1863 "Faria Instruments" ;
VAL_ 2650734592 Industry_Code 0 "Global" 1 "Highway" 2 "Agriculture" 3 "Construction" 4 "Marine Industry" 5 "Industrial" ;
VAL_ 2650734592 Proprietary_ID 1 "Init #2" 4 "AM Radio" 5 "Zone Info" 6 "Source" 8 "Source List" 9 "Control" 12 "FM Radio" 13 "Playlist" 14 "Track" 15 "Artist" 16 "Album" 19 "Menu Item" 20 "Zones" 23 "Max Volume" 24 "Volume" 25 "Init #1" 48 "Position" 50 "Init #3" ;
VAL_ 2650734592 Control 0 "Set" 128 "Ack" ;
VAL_ 2650734592 Manufacturer_Code 69 "ARKS Enterprises" 78 "FW Murphy/Enovation Controls" 80 "Twin Disc" 85 "Kohler Power Systems" 88 "Hemisphere GPS" 135 "Airmar" 137 "Maretron" 140 "Lowrance" 144 "Mercury Marine" 147 "Nautibus Electronic" 148 "Blue Water Data" 154 "Westerbeke" 157 "ISSPRO" 161 "Offshore Systems (UK)" 163 "Evinrude/BRP" 165 "CPAC Systems" 168 "Xantrex Technology" 169 "Marlin Technologies" 172 "Yanmar Marine" 174 "Volvo Penta" 176 "Carling Technologies Inc. (Moritz Aerospace)" 185 "Beede Instruments" 192 "Floscan Instrument" 193 "Nobeltec" 198 "Mystic Valley Communications" 199 "Actia" 201 "Disenos Y Technologia" 211 "Digital Switching Systems" 215 "Xintex/Atena" 224 "EMMI NETWORK" 228 "ZF" 229 "Garmin" 233 "Yacht Monitoring Solutions" 235 "Sailormade Marine Telemetry/Tetra Technology" 243 "Eride" 257 "Honda Motor" 272 "Groco" 273 "Actisense" 274 "Amphenol LTW Technology" 275 "Navico" 283 "Hamilton Jet" 285 "Sea Recovery" 286 "Coelmo SRL Italy" 295 "BEP Marine" 304 "Empir Bus" 305 "NovAtel" 306 "Sleipner Motor" 307 "MBW Technologies" 315 "ICOM" 328 "Qwerty" 329 "Dief" 341 "Boening Automationstechnologie" 345 "Korean Maritime University" 351 "Thrane and Thrane" 355 "Mastervolt" 356 "Fischer Panda Generators" 358 "Victron Energy" 370 "Rolls Royce Marine" 373 "Electronic Design" 374 "Northern Lights" 378 "Glendinning" 381 "B & G" 384 "Rose Point Navigation Systems" 385 "Johnson Outdoors Marine Electronics Inc Geonav" 394 "Capi 2" 396 "Beyond Measure" 400 "Livorsi Marine" 404 "ComNav" 409 "Chetco" 419 "Fusion Electronics" 421 "Standard Horizon" 422 "True Heading" 426 "Egersund Marine Electronics" 427 "em-trak Marine Electronics" 431 "Tohatsu Co, JP" 437 "Digital Yacht" 438 "Comar Systems Limited" 440 "Cummins" 443 "VDO (aka Continental-Corporation)" 451 "Parker Hannifin aka Village Marine Tech" 459 "Alltek Marine Electronics" 460 "SAN GIORGIO S.E.I.N" 466 "Veethree Electronics & Marine" 470 "SI-TEX Marine Electronics" 471 "Sea Cross Marine" 475 "GME aka Standard Communications" 476 "Humminbird Marine Electronics" 478 "Ocean Sat" 481 "Chetco Digital Instruments" 493 "Watcheye" 499 "Lcj Capteurs" 502 "Attwood Marine" 503 "Naviop S.R.L." 504 "Vesper Marine" 510 "Marinesoft" 513 "Simarine" 517 "NoLand Engineering" 518 "Transas USA" 529 "National Instruments Korea" 530 "National Marine Electronics Association" 532 "Onwa Marine" 540 "Webasto" 571 "Marinecraft (South Korea)" 573 "McMurdo Group aka Orolia" 578 "Advansea" 579 "KVH" 580 "San Jose Technology" 583 "Yacht Control" 586 "Suzuki Motor" 591 "US Coast Guard" 595 "Ship Module aka Customware" 600 "Aquatic AV" 605 "Aventics" 606 "Intellian" 612 "SamwonIT" 614 "Arlt Tecnologies" 637 "Bavaria Yachts" 641 "Diverse Yacht Services" 644 "Wema U.S.A dba KUS" 658 "Shenzhen Jiuzhou Himunication" 688 "Rockford" 699 "Harman International" 704 "JL Audio" 708 "Lars Thrane" 715 "Autonnic" 717 "Yacht Devices" 734 "REAP Systems" 735 "AEM Performance Electronics" 739 "LxNav" 741 "Littelfuse, Inc (formerly Carling Technologies)" 743 "DaeMyung" 744 "Woosung" 748 "ISOTTA IFRA srl" 773 "Clarion US" 776 "HMI Systems" 777 "Ocean Signal" 778 "Seakeeper" 781 "Poly Planar" 785 "Fischer Panda DE" 795 "Broyda Industries" 796 "Canadian Automotive" 797 "Tides Marine" 798 "Lumishore" 799 "Still Water Designs and Audio" 802 "BJ Technologies (Beneteau)" 803 "Gill Sensors" 811 "Blue Water Desalination" 815 "FLIR" 824 "Undheim Systems" 826 "Lewmar" 838 "TeamSurv" 844 "Fell Marine" 847 "Oceanvolt" 862 "Prospec" 868 "Data Panel" 890 "L3 Technologies" 894 "Rhodan Marine Systems" 896 "Nexfour Solutions" 905 "ASA Electronics" 909 "Marines Co (South Korea)" 911 "Nautic-on" 917 "Sentinel" 929 "JL Marine Systems" 930 "Ecotronix" 944 "Zontisa Marine" 951 "EXOR International" 962 "Timbolier Industries" 963 "TJC Micro" 968 "Cox Powertrain" 969 "Blue Seas" 981 "Kobelt Manufacturing" 992 "Blue Ocean IOT" 997 "Xenta Systems" 999 "Signal K" 1004 "Ultraflex" 1008 "Lintest SmartBoat" 1011 "Soundmax" 1020 "Team Italia Marine (Onyx Marine Automation s.r.l)" 1021 "Entratech" 1022 "ITC" 1029 "The Marine Guardian" 1047 "Sonic" 1051 "ProNav" 1053 "Vetus Maxwell INC." 1056 "Lithium Pros" 1059 "Boatrax" 1062 "Marol Co ltd" 1065 "CALYPSO Instruments" 1066 "Spot Zero Water" 1069 "Lithionics Battery" 1070 "Quick-teck Electronics" 1075 "Uniden America" 1083 "Nauticoncept" 1084 "Shadow-Caster LED lighting" 1085 "Wet Sounds" 1088 "E-T-A Circuit Breakers" 1092 "Scheiber" 1100 "Smart Yachts International Limited" 1109 "Dockmate" 1114 "Bobs Machine" 1118 "L3Harris ASV" 1119 "Balmar" 1120 "Elettromedia" 1127 "Electromaax" 1140 "Across Oceans Systems" 1145 "Kiwi Yachting" 1150 "BSB Artificial Intelligence" 1151 "Orca Technologies" 1154 "TBS Electronics" 1158 "Technoton Electroics" 1160 "MG Energy Systems" 1169 "Sea Machine Robotics" 1171 "Vista Manufacturing" 1183 "Zipwake" 1186 "Sailmon" 1192 "Airmoniq Pro Kft" 1194 "Sierra Marine" 1200 "Xinuo Information Technology (Xiamen)" 1218 "Septentrio" 1233 "NKE Marine Electronics" 1238 "SuperTrack Aps" 1239 "Honda Electronics" 1245 "Raritan Engineering" 1249 "Integrated Power Solutions AG" 1260 "Interactive Technologies" 1283 "LTG-Tech" 1299 "Energy Solutions (UK)" 1300 "WATT Fuel Cell" 1302 "Pro Mainer" 1305 "Dragonfly Energy" 1306 "Koden Electronics" 1311 "Humphree" 1316 "Hinkley Yachts" 1317 "Global Marine Management GmbH (GMM)" 1320 "Triskel Marine" 1330 "Warwick Control Technologies" 1331 "Dolphin Charger" 1337 "Barnacle Systems" 1348 "Radian IoT" 1353 "Ocean LED Marine" 1359 "BluNav" 1361 "OVA (Nantong Saiyang Electronics Co., Ltd)" 1368 "RAD Propulsion" 1369 "Electric Yacht" 1372 "Elco Motor Yachts" 1384 "Tecnoseal Foundry S.r.l" 1385 "Pro Charging Systems" 1389 "EVEX" 1398 "Gobius Sensor Technology" 1403 "Arco Marine" 1408 "Lenco Marine" 1413 "Naocontrol" 1417 "Revatek" 1438 "Aeolionics" 1439 "PredictWind" 1440 "Egis Mobile Electric" 1445 "Starboard Yacht Group" 1446 "Roswell Marine" 1451 "ePropulsion (Guangdong ePropulsion Technology Ltd.)" 1452 "Micro-Air" 1453 "Vital Battery" 1458 "Ride Controller" 1460 "Tocaro Blue" 1461 "Vanquish Yachts" 1471 "FT Technologies" 1478 "Alps Alpine" 1481 "E-Force Marine" 1482 "CMC Marine" 1483 "Nanjing Sandemarine Information Technology" 1850 "Teleflex Marine (SeaStar Solutions)" 1851 "Raymarine" 1852 "Navionics" 1853 "Japan Radio" 1854 "Northstar Technologies" 1855 "Furuno" 1856 "Trimble" 1857 "Simrad" 1858 "Litton" 1859 "Kvasar" 1860 "MMP" 1861 "Vector Cantech" 1862 "Yamaha Marine" 1863 "Faria Instruments" ;
VAL_ 2650734592 Industry_Code 0 "Global" 1 "Highway" 2 "Agriculture" 3 "Construction" 4 "Marine Industry" 5 "Industrial" ;
VAL_ 2650734592 Proprietary_ID 1 "Init #2" 4 "AM Radio" 5 "Zone Info" 6 "Source" 8 "Source List" 9 "Control" 12 "FM Radio" 13 "Playlist" 14 "Track" 15 "Artist" 16 "Album" 19 "Menu Item" 20 "Zones" 23 "Max Volume" 24 "Volume" 25 "Init #1" 48 "Position" 50 "Init #3" ;
VAL_ 2650734592 Control 0 "Set" 128 "Ack" ;
VAL_ 2650734592 Manufacturer_Code 69 "ARKS Enterprises" 78 "FW Murphy/Enovation Controls" 80 "Twin Disc" 85 "Kohler Power Systems" 88 "Hemisphere GPS" 135 "Airmar" 137 "Maretron" 140 "Lowrance" 144 "Mercury Marine" 147 "Nautibus Electronic" 148 "Blue Water Data" 154 "Westerbeke" 157 "ISSPRO" 161 "Offshore Systems (UK)" 163 "Evinrude/BRP" 165 "CPAC Systems" 168 "Xantrex Technology" 169 "Marlin Technologies" 172 "Yanmar Marine" 174 "Volvo Penta" 176 "Carling Technologies Inc. (Moritz Aerospace)" 185 "Beede Instruments" 192 "Floscan Instrument" 193 "Nobeltec" 198 "Mystic Valley Communications" 199 "Actia" 201 "Disenos Y Technologia" 211 "Digital Switching Systems" 215 "Xintex/Atena" 224 "EMMI NETWORK" 228 "ZF" 229 "Garmin" 233 "Yacht Monitoring Solutions" 235 "Sailormade Marine Telemetry/Tetra Technology" 243 "Eride" 257 "Honda Motor" 272 "Groco" 273 "Actisense" 274 "Amphenol LTW Technology" 275 "Navico" 283 "Hamilton Jet" 285 "Sea Recovery" 286 "Coelmo SRL Italy" 295 "BEP Marine" 304 "Empir Bus" 305 "NovAtel" 306 "Sleipner Motor" 307 "MBW Technologies" 315 "ICOM" 328 "Qwerty" 329 "Dief" 341 "Boening Automationstechnologie" 345 "Korean Maritime University" 351 "Thrane and Thrane" 355 "Mastervolt" 356 "Fischer Panda Generators" 358 "Victron Energy" 370 "Rolls Royce Marine" 373 "Electronic Design" 374 "Northern Lights" 378 "Glendinning" 381 "B & G" 384 "Rose Point Navigation Systems" 385 "Johnson Outdoors Marine Electronics Inc Geonav" 394 "Capi 2" 396 "Beyond Measure" 400 "Livorsi Marine" 404 "ComNav" 409 "Chetco" 419 "Fusion Electronics" 421 "Standard Horizon" 422 "True Heading" 426 "Egersund Marine Electronics" 427 "em-trak Marine Electronics" 431 "Tohatsu Co, JP" 437 "Digital Yacht" 438 "Comar Systems Limited" 440 "Cummins" 443 "VDO (aka Continental-Corporation)" 451 "Parker Hannifin aka Village Marine Tech" 459 "Alltek Marine Electronics" 460 "SAN GIORGIO S.E.I.N" 466 "Veethree Electronics & Marine" 470 "SI-TEX Marine Electronics" 471 "Sea Cross Marine" 475 "GME aka Standard Communications" 476 "Humminbird Marine Electronics" 478 "Ocean Sat" 481 "Chetco Digital Instruments" 493 "Watcheye" 499 "Lcj Capteurs" 502 "Attwood Marine" 503 "Naviop S.R.L." 504 "Vesper Marine" 510 "Marinesoft" 513 "Simarine" 517 "NoLand Engineering" 518 "Transas USA" 529 "National Instruments Korea" 530 "National Marine Electronics Association" 532 "Onwa Marine" 540 "Webasto" 571 "Marinecraft (South Korea)" 573 "McMurdo Group aka Orolia" 578 "Advansea" 579 "KVH" 580 "San Jose Technology" 583 "Yacht Control" 586 "Suzuki Motor" 591 "US Coast Guard" 595 "Ship Module aka Customware" 600 "Aquatic AV" 605 "Aventics" 606 "Intellian" 612 "SamwonIT" 614 "Arlt Tecnologies" 637 "Bavaria Yachts" 641 "Diverse Yacht Services" 644 "Wema U.S.A dba KUS" 658 "Shenzhen Jiuzhou Himunication" 688 "Rockford" 699 "Harman International" 704 "JL Audio" 708 "Lars Thrane" 715 "Autonnic" 717 "Yacht Devices" 734 "REAP Systems" 735 "AEM Performance Electronics" 739 "LxNav" 741 "Littelfuse, Inc (formerly Carling Technologies)" 743 "DaeMyung" 744 "Woosung" 748 "ISOTTA IFRA srl" 773 "Clarion US" 776 "HMI Systems" 777 "Ocean Signal" 778 "Seakeeper" 781 "Poly Planar" 785 "Fischer Panda DE" 795 "Broyda Industries" 796 "Canadian Automotive" 797 "Tides Marine" 798 "Lumishore" 799 "Still Water Designs and Audio" 802 "BJ Technologies (Beneteau)" 803 "Gill Sensors" 811 "Blue Water Desalination" 815 "FLIR" 824 "Undheim Systems" 826 "Lewmar" 838 "TeamSurv" 844 "Fell Marine" 847 "Oceanvolt" 862 "Prospec" 868 "Data Panel" 890 "L3 Technologies" 894 "Rhodan Marine Systems" 896 "Nexfour Solutions" 905 "ASA Electronics" 909 "Marines Co (South Korea)" 911 "Nautic-on" 917 "Sentinel" 929 "JL Marine Systems" 930 "Ecotronix" 944 "Zontisa Marine" 951 "EXOR International" 962 "Timbolier Industries" 963 "TJC Micro" 968 "Cox Powertrain" 969 "Blue Seas" 981 "Kobelt Manufacturing" 992 "Blue Ocean IOT" 997 "Xenta Systems" 999 "Signal K" 1004 "Ultraflex" 1008 "Lintest SmartBoat" 1011 "Soundmax" 1020 "Team Italia Marine (Onyx Marine Automation s.r.l)" 1021 "Entratech" 1022 "ITC" 1029 "The Marine Guardian" 1047 "Sonic" 1051 "ProNav" 1053 "Vetus Maxwell INC." 1056 "Lithium Pros" 1059 "Boatrax" 1062 "Marol Co ltd" 1065 "CALYPSO Instruments" 1066 "Spot Zero Water" 1069 "Lithionics Battery" 1070 "Quick-teck Electronics" 1075 "Uniden America" 1083 "Nauticoncept" 1084 "Shadow-Caster LED lighting" 1085 "Wet Sounds" 1088 "E-T-A Circuit Breakers" 1092 "Scheiber" 1100 "Smart Yachts International Limited" 1109 "Dockmate" 1114 "Bobs Machine" 1118 "L3Harris ASV" 1119 "Balmar" 1120 "Elettromedia" 1127 "Electromaax" 1140 "Across Oceans Systems" 1145 "Kiwi Yachting" 1150 "BSB Artificial Intelligence" 1151 "Orca Technologies" 1154 "TBS Electronics" 1158 "Technoton Electroics" 1160 "MG Energy Systems" 1169 "Sea Machine Robotics" 1171 "Vista Manufacturing" 1183 "Zipwake" 1186 "Sailmon" 1192 "Airmoniq Pro Kft" 1194 "Sierra Marine" 1200 "Xinuo Information Technology (Xiamen)" 1218 "Septentrio" 1233 "NKE Marine Electronics" 1238 "SuperTrack Aps" 1239 "Honda Electronics" 1245 "Raritan Engineering" 1249 "Integrated Power Solutions AG" 1260 "Interactive Technologies" 1283 "LTG-Tech" 1299 "Energy Solutions (UK)" 1300 "WATT Fuel Cell" 1302 "Pro Mainer" 1305 "Dragonfly Energy" 1306 "Koden Electronics" 1311 "Humphree" 1316 "Hinkley Yachts" 1317 "Global Marine Management GmbH (GMM)" 1320 "Triskel Marine" 1330 "Warwick Control Technologies" 1331 "Dolphin Charger" 1337 "Barnacle Systems" 1348 "Radian IoT" 1353 "Ocean LED Marine" 1359 "BluNav" 1361 "OVA (Nantong Saiyang Electronics Co., Ltd)" 1368 "RAD Propulsion" 1369 "Electric Yacht" 1372 "Elco Motor Yachts" 1384 "Tecnoseal Foundry S.r.l" 1385 "Pro Charging Systems" 1389 "EVEX" 1398 "Gobius Sensor Technology" 1403 "Arco Marine" 1408 "Lenco Marine" 1413 "Naocontrol" 1417 "Revatek" 1438 "Aeolionics" 1439 "PredictWind" 1440 "Egis Mobile Electric" 1445 "Starboard Yacht Group" 1446 "Roswell Marine" 1451 "ePropulsion (Guangdong ePropulsion Technology Ltd.)" 1452 "Micro-Air" 1453 "Vital Battery" 1458 "Ride Controller" 1460 "Tocaro Blue" 1461 "Vanquish Yachts" 1471 "FT Technologies" 1478 "Alps Alpine" 1481 "E-Force Marine" 1482 "CMC Marine" 1483 "Nanjing Sandemarine Information Technology" 1850 "Teleflex Marine (SeaStar Solutions)" 1851 "Raymarine" 1852 "Navionics" 1853 "Japan Radio" 1854 "Northstar Technologies" 1855 "Furuno" 1856 "Trimble" 1857 "Simrad" 1858 "Litton" 1859 "Kvasar" 1860 "MMP" 1861 "Vector Cantech" 1862 "Yamaha Marine" 1863 "Faria Instruments" ;
VAL_ 2650734592 Industry_Code 0 "Global" 1 "Highway" 2 "Agriculture" 3 "Construction" 4 "Marine Industry" 5 "Industrial" ;
VAL_ 2650734592 Proprietary_ID 1 "Init #2" 4 "AM Radio" 5 "Zone Info" 6 "Source" 8 "Source List" 9 "Control" 12 "FM Radio" 13 "Playlist" 14 "Track" 15 "Artist" 16 "Album" 19 "Menu Item" 20 "Zones" 23 "Max Volume" 24 "Volume" 25 "Init #1" 48 "Position" 50 "Init #3" ;
VAL_ 2650734592 Control 0 "Set" 128 "Ack" ;
VAL_ 2650734592 Manufacturer_Code 69 "ARKS Enterprises" 78 "FW Murphy/Enovation Controls" 80 "Twin Disc" 85 "Kohler Power Systems" 88 "Hemisphere GPS" 135 "Airmar" 137 "Maretron" 140 "Lowrance" 144 "Mercury Marine" 147 "Nautibus Electronic" 148 "Blue Water Data" 154 "Westerbeke" 157 "ISSPRO" 161 "Offshore Systems (UK)" 163 "Evinrude/BRP" 165 "CPAC Systems" 168 "Xantrex Technology" 169 "Marlin Technologies" 172 "Yanmar Marine" 174 "Volvo Penta" 176 "Carling Technologies Inc. (Moritz Aerospace)" 185 "Beede Instruments" 192 "Floscan Instrument" 193 "Nobeltec" 198 "Mystic Valley Communications" 199 "Actia" 201 "Disenos Y Technologia" 211 "Digital Switching Systems" 215 "Xintex/Atena" 224 "EMMI NETWORK" 228 "ZF" 229 "Garmin" 233 "Yacht Monitoring Solutions" 235 "Sailormade Marine Telemetry/Tetra Technology" 243 "Eride" 257 "Honda Motor" 272 "Groco" 273 "Actisense" 274 "Amphenol LTW Technology" 275 "Navico" 283 "Hamilton Jet" 285 "Sea Recovery" 286 "Coelmo SRL Italy" 295 "BEP Marine" 304 "Empir Bus" 305 "NovAtel" 306 "Sleipner Motor" 307 "MBW Technologies" 315 "ICOM" 328 "Qwerty" 329 "Dief" 341 "Boening Automationstechnologie" 345 "Korean Maritime University" 351 "Thrane and Thrane" 355 "Mastervolt" 356 "Fischer Panda Generators" 358 "Victron Energy" 370 "Rolls Royce Marine" 373 "Electronic Design" 374 "Northern Lights" 378 "Glendinning" 381 "B & G" 384 "Rose Point Navigation Systems" 385 "Johnson Outdoors Marine Electronics Inc Geonav" 394 "Capi 2" 396 "Beyond Measure" 400 "Livorsi Marine" 404 "ComNav" 409 "Chetco" 419 "Fusion Electronics" 421 "Standard Horizon" 422 "True Heading" 426 "Egersund Marine Electronics" 427 "em-trak Marine Electronics" 431 "Tohatsu Co, JP" 437 "Digital Yacht" 438 "Comar Systems Limited" 440 "Cummins" 443 "VDO (aka Continental-Corporation)" 451 "Parker Hannifin aka Village Marine Tech" 459 "Alltek Marine Electronics" 460 "SAN GIORGIO S.E.I.N" 466 "Veethree Electronics & Marine" 470 "SI-TEX Marine Electronics" 471 "Sea Cross Marine" 475 "GME aka Standard Communications" 476 "Humminbird Marine Electronics" 478 "Ocean Sat" 481 "Chetco Digital Instruments" 493 "Watcheye" 499 "Lcj Capteurs" 502 "Attwood Marine" 503 "Naviop S.R.L." 504 "Vesper Marine" 510 "Marinesoft" 513 "Simarine" 517 "NoLand Engineering" 518 "Transas USA" 529 "National Instruments Korea" 530 "National Marine Electronics Association" 532 "Onwa Marine" 540 "Webasto" 571 "Marinecraft (South Korea)" 573 "McMurdo Group aka Orolia" 578 "Advansea" 579 "KVH" 580 "San Jose Technology" 583 "Yacht Control" 586 "Suzuki Motor" 591 "US Coast Guard" 595 "Ship Module aka Customware" 600 "Aquatic AV" 605 "Aventics" 606 "Intellian" 612 "SamwonIT" 614 "Arlt Tecnologies" 637 "Bavaria Yachts" 641 "Diverse Yacht Services" 644 "Wema U.S.A dba KUS" 658 "Shenzhen Jiuzhou Himunication" 688 "Rockford" 699 "Harman International" 704 "JL Audio" 708 "Lars Thrane" 715 "Autonnic" 717 "Yacht Devices" 734 "REAP Systems" 735 "AEM Performance Electronics" 739 "LxNav" 741 "Littelfuse, Inc (formerly Carling Technologies)" 743 "DaeMyung" 744 "Woosung" 748 "ISOTTA IFRA srl" 773 "Clarion US" 776 "HMI Systems" 777 "Ocean Signal" 778 "Seakeeper" 781 "Poly Planar" 785 "Fischer Panda DE" 795 "Broyda Industries" 796 "Canadian Automotive" 797 "Tides Marine" 798 "Lumishore" 799 "Still Water Designs and Audio" 802 "BJ Technologies (Beneteau)" 803 "Gill Sensors" 811 "Blue Water Desalination" 815 "FLIR" 824 "Undheim Systems" 826 "Lewmar" 838 "TeamSurv" 844 "Fell Marine" 847 "Oceanvolt" 862 "Prospec" 868 "Data Panel" 890 "L3 Technologies" 894 "Rhodan Marine Systems" 896 "Nexfour Solutions" 905 "ASA Electronics" 909 "Marines Co (South Korea)" 911 "Nautic-on" 917 "Sentinel" 929 "JL Marine Systems" 930 "Ecotronix" 944 "Zontisa Marine" 951 "EXOR International" 962 "Timbolier Industries" 963 "TJC Micro" 968 "Cox Powertrain" 969 "Blue Seas" 981 "Kobelt Manufacturing" 992 "Blue Ocean IOT" 997 "Xenta Systems" 999 "Signal K" 1004 "Ultraflex" 1008 "Lintest SmartBoat" 1011 "Soundmax" 1020 "Team Italia Marine (Onyx Marine Automation s.r.l)" 1021 "Entratech" 1022 "ITC" 1029 "The Marine Guardian" 1047 "Sonic" 1051 "ProNav" 1053 "Vetus Maxwell INC." 1056 "Lithium Pros" 1059 "Boatrax" 1062 "Marol Co ltd" 1065 "CALYPSO Instruments" 1066 "Spot Zero Water" 1069 "Lithionics Battery" 1070 "Quick-teck Electronics" 1075 "Uniden America" 1083 "Nauticoncept" 1084 "Shadow-Caster LED lighting" 1085 "Wet Sounds" 1088 "E-T-A Circuit Breakers" 1092 "Scheiber" 1100 "Smart Yachts International Limited" 1109 "Dockmate" 1114 "Bobs Machine" 1118 "L3Harris ASV" 1119 "Balmar" 1120 "Elettromedia" 1127 "Electromaax" 1140 "Across Oceans Systems" 1145 "Kiwi Yachting" 1150 "BSB Artificial Intelligence" 1151 "Orca Technologies" 1154 "TBS Electronics" 1158 "Technoton Electroics" 1160 "MG Energy Systems" 1169 "Sea Machine Robotics" 1171 "Vista Manufacturing" 1183 "Zipwake" 1186 "Sailmon" 1192 "Airmoniq Pro Kft" 1194 "Sierra Marine" 1200 "Xinuo Information Technology (Xiamen)" 1218 "Septentrio" 1233 "NKE Marine Electronics" 1238 "SuperTrack Aps" 1239 "Honda Electronics" 1245 "Raritan Engineering" 1249 "Integrated Power Solutions AG" 1260 "Interactive Technologies" 1283 "LTG-Tech" 1299 "Energy Solutions (UK)" 1300 "WATT Fuel Cell" 1302 "Pro Mainer" 1305 "Dragonfly Energy" 1306 "Koden Electronics" 1311 "Humphree" 1316 "Hinkley Yachts" 1317 "Global Marine Management GmbH (GMM)" 1320 "Triskel Marine" 1330 "Warwick Control Technologies" 1331 "Dolphin Charger" 1337 "Barnacle Systems" 1348 "Radian IoT" 1353 "Ocean LED Marine" 1359 "BluNav" 1361 "OVA (Nantong Saiyang Electronics Co., Ltd)" 1368 "RAD Propulsion" 1369 "Electric Yacht" 1372 "Elco Motor Yachts" 1384 "Tecnoseal Foundry S.r.l" 1385 "Pro Charging Systems" 1389 "EVEX" 1398 "Gobius Sensor Technology" 1403 "Arco Marine" 1408 "Lenco Marine" 1413 "Naocontrol" 1417 "Revatek" 1438 "Aeolionics" 1439 "PredictWind" 1440 "Egis Mobile Electric" 1445 "Starboard Yacht Group" 1446 "Roswell Marine" 1451 "ePropulsion (Guangdong ePropulsion Technology Ltd.)" 1452 "Micro-Air" 1453 "Vital Battery" 1458 "Ride Controller" 1460 "Tocaro Blue" 1461 "Vanquish Yachts" 1471 "FT Technologies" 1478 "Alps Alpine" 1481 "E-Force Marine" 1482 "CMC Marine" 1483 "Nanjing Sandemarine Information Technology" 1850 "Teleflex Marine (SeaStar Solutions)" 1851 "Raymarine" 1852 "Navionics" 1853 "Japan Radio" 1854 "Northstar Technologies" 1855 "Furuno" 1856 "Trimble" 1857 "Simrad" 1858 "Litton" 1859 "Kvasar" 1860 "MMP" 1861 "Vector Cantech" 1862 "Yamaha Marine" 1863 "Faria Instruments" ;
VAL_ 2650734592 Industry_Code 0 "Global" 1 "Highway" 2 "Agriculture" 3 "Construction" 4 "Marine Industry" 5 "Industrial" ;
VAL_ 2650734592 Proprietary_ID 1 "Init #2" 4 "AM Radio" 5 "Zone Info" 6 "Source" 8 "Source List" 9 "Control" 12 "FM Radio" 13 "Playlist" 14 "Track" 15 "Artist" 16 "Album" 19 "Menu Item" 20 "Zones" 23 "Max Volume" 24 "Volume" 25 "Init #1" 48 "Position" 50 "Init #3" ;
VAL_ 2650734592 Control 0 "Set" 128 "Ack" ;
VAL_ 2583625984 Manufacturer_Code 69 "ARKS Enterprises" 78 "FW Murphy/Enovation Controls" 80 "Twin Disc" 85 "Kohler Power Systems" 88 "Hemisphere GPS" 135 "Airmar" 137 "Maretron" 140 "Lowrance" 144 "Mercury Marine" 147 "Nautibus Electronic" 148 "Blue Water Data" 154 "Westerbeke" 157 "ISSPRO" 161 "Offshore Systems (UK)" 163 "Evinrude/BRP" 165 "CPAC Systems" 168 "Xantrex Technology" 169 "Marlin Technologies" 172 "Yanmar Marine" 174 "Volvo Penta" 176 "Carling Technologies Inc. (Moritz Aerospace)" 185 "Beede Instruments" 192 "Floscan Instrument" 193 "Nobeltec" 198 "Mystic Valley Communications" 199 "Actia" 201 "Disenos Y Technologia" 211 "Digital Switching Systems" 215 "Xintex/Atena" 224 "EMMI NETWORK" 228 "ZF" 229 "Garmin" 233 "Yacht Monitoring Solutions" 235 "Sailormade Marine Telemetry/Tetra Technology" 243 "Eride" 257 "Honda Motor" 272 "Groco" 273 "Actisense" 274 "Amphenol LTW Technology" 275 "Navico" 283 "Hamilton Jet" 285 "Sea Recovery" 286 "Coelmo SRL Italy" 295 "BEP Marine" 304 "Empir Bus" 305 "NovAtel" 306 "Sleipner Motor" 307 "MBW Technologies" 315 "ICOM" 328 "Qwerty" 329 "Dief" 341 "Boening Automationstechnologie" 345 "Korean Maritime University" 351 "Thrane and Thrane" 355 "Mastervolt" 356 "Fischer Panda Generators" 358 "Victron Energy" 370 "Rolls Royce Marine" 373 "Electronic Design" 374 "Northern Lights" 378 "Glendinning" 381 "B & G" 384 "Rose Point Navigation Systems" 385 "Johnson Outdoors Marine Electronics Inc Geonav" 394 "Capi 2" 396 "Beyond Measure" 400 "Livorsi Marine" 404 "ComNav" 409 "Chetco" 419 "Fusion Electronics" 421 "Standard Horizon" 422 "True Heading" 426 "Egersund Marine Electronics" 427 "em-trak Marine Electronics" 431 "Tohatsu Co, JP" 437 "Digital Yacht" 438 "Comar Systems Limited" 440 "Cummins" 443 "VDO (aka Continental-Corporation)" 451 "Parker Hannifin aka Village Marine Tech" 459 "Alltek Marine Electronics" 460 "SAN GIORGIO S.E.I.N" 466 "Veethree Electronics & Marine" 470 "SI-TEX Marine Electronics" 471 "Sea Cross Marine" 475 "GME aka Standard Communications" 476 "Humminbird Marine Electronics" 478 "Ocean Sat" 481 "Chetco Digital Instruments" 493 "Watcheye" 499 "Lcj Capteurs" 502 "Attwood Marine" 503 "Naviop S.R.L." 504 "Vesper Marine" 510 "Marinesoft" 513 "Simarine" 517 "NoLand Engineering" 518 "Transas USA" 529 "National Instruments Korea" 530 "National Marine Electronics Association" 532 "Onwa Marine" 540 "Webasto" 571 "Marinecraft (South Korea)" 573 "McMurdo Group aka Orolia" 578 "Advansea" 579 "KVH" 580 "San Jose Technology" 583 "Yacht Control" 586 "Suzuki Motor" 591 "US Coast Guard" 595 "Ship Module aka Customware" 600 "Aquatic AV" 605 "Aventics" 606 "Intellian" 612 "SamwonIT" 614 "Arlt Tecnologies" 637 "Bavaria Yachts" 641 "Diverse Yacht Services" 644 "Wema U.S.A dba KUS" 658 "Shenzhen Jiuzhou Himunication" 688 "Rockford" 699 "Harman International" 704 "JL Audio" 708 "Lars Thrane" 715 "Autonnic" 717 "Yacht Devices" 734 "REAP Systems" 735 "AEM Performance Electronics" 739 "LxNav" 741 "Littelfuse, Inc (formerly Carling Technologies)" 743 "DaeMyung" 744 "Woosung" 748 "ISOTTA IFRA srl" 773 "Clarion US" 776 "HMI Systems" 777 "Ocean Signal" 778 "Seakeeper" 781 "Poly Planar" 785 "Fischer Panda DE" 795 "Broyda Industries" 796 "Canadian Automotive" 797 "Tides Marine" 798 "Lumishore" 799 "Still Water Designs and Audio" 802 "BJ Technologies (Beneteau)" 803 "Gill Sensors" 811 "Blue Water Desalination" 815 "FLIR" 824 "Undheim Systems" 826 "Lewmar" 838 "TeamSurv" 844 "Fell Marine" 847 "Oceanvolt" 862 "Prospec" 868 "Data Panel" 890 "L3 Technologies" 894 "Rhodan Marine Systems" 896 "Nexfour Solutions" 905 "ASA Electronics" 909 "Marines Co (South Korea)" 911 "Nautic-on" 917 "Sentinel" 929 "JL Marine Systems" 930 "Ecotronix" 944 "Zontisa Marine" 951 "EXOR International" 962 "Timbolier Industries" 963 "TJC Micro" 968 "Cox Powertrain" 969 "Blue Seas" 981 "Kobelt Manufacturing" 992 "Blue Ocean IOT" 997 "Xenta Systems" 999 "Signal K" 1004 "Ultraflex" 1008 "Lintest SmartBoat" 1011 "Soundmax" 1020 "Team Italia Marine (Onyx Marine Automation s.r.l)" 1021 "Entratech" 1022 "ITC" 1029 "The Marine Guardian" 1047 "Sonic" 1051 "ProNav" 1053 "Vetus Maxwell INC." 1056 "Lithium Pros" 1059 "Boatrax" 1062 "Marol Co ltd" 1065 "CALYPSO Instruments" 1066 "Spot Zero Water" 1069 "Lithionics Battery" 1070 "Quick-teck Electronics" 1075 "Uniden America" 1083 "Nauticoncept" 1084 "Shadow-Caster LED lighting" 1085 "Wet Sounds" 1088 "E-T-A Circuit Breakers" 1092 "Scheiber" 1100 "Smart Yachts International Limited" 1109 "Dockmate" 1114 "Bobs Machine" 1118 "L3Harris ASV" 1119 "Balmar" 1120 "Elettromedia" 1127 "Electromaax" 1140 "Across Oceans Systems" 1145 "Kiwi Yachting" 1150 "BSB Artificial Intelligence" 1151 "Orca Technologies" 1154 "TBS Electronics" 1158 "Technoton Electroics" 1160 "MG Energy Systems" 1169 "Sea Machine Robotics" 1171 "Vista Manufacturing" 1183 "Zipwake" 1186 "Sailmon" 1192 "Airmoniq Pro Kft" 1194 "Sierra Marine" 1200 "Xinuo Information Technology (Xiamen)" 1218 "Septentrio" 1233 "NKE Marine Electronics" 1238 "SuperTrack Aps" 1239 "Honda Electronics" 1245 "Raritan Engineering" 1249 "Integrated Power Solutions AG" 1260 "Interactive Technologies" 1283 "LTG-Tech" 1299 "Energy Solutions (UK)" 1300 "WATT Fuel Cell" 1302 "Pro Mainer" 1305 "Dragonfly Energy" 1306 "Koden Electronics" 1311 "Humphree" 1316 "Hinkley Yachts" 1317 "Global Marine Management GmbH (GMM)" 1320 "Triskel Marine" 1330 "Warwick Control Technologies" 1331 "Dolphin Charger" 1337 "Barnacle Systems" 1348 "Radian IoT" 1353 "Ocean LED Marine" 1359 "BluNav" 1361 "OVA (Nantong Saiyang Electronics Co., Ltd)" 1368 "RAD Propulsion" 1369 "Electric Yacht" 1372 "Elco Motor Yachts" 1384 "Tecnoseal Foundry S.r.l" 1385 "Pro Charging Systems" 1389 "EVEX" 1398 "Gobius Sensor Technology" 1403 "Arco Marine" 1408 "Lenco Marine" 1413 "Naocontrol" 1417 "Revatek" 1438 "Aeolionics" 1439 "PredictWind" 1440 "Egis Mobile Electric" 1445 "Starboard Yacht Group" 1446 "Roswell Marine" 1451 "ePropulsion (Guangdong ePropulsion Technology Ltd.)" 1452 "Micro-Air" 1453 "Vital Battery" 1458 "Ride Controller" 1460 "Tocaro Blue" 1461 "Vanquish Yachts" 1471 "FT Technologies" 1478 "Alps Alpine" 1481 "E-Force Marine" 1482 "CMC Marine" 1483 "Nanjing Sandemarine Information Technology" 1850 "Teleflex Marine (SeaStar Solutions)" 1851 "Raymarine" 1852 "Navionics" 1853 "Japan Radio" 1854 "Northstar Technologies" 1855 "Furuno" 1856 "Trimble" 1857 "Simrad" 1858 "Litton" 1859 "Kvasar" 1860 "MMP" 1861 "Vector Cantech" 1862 "Yamaha Marine" 1863 "Faria Instruments" ;
VAL_ 2583625984 Industry_Code 0 "Global" 1 "Highway" 2 "Agriculture" 3 "Construction" 4 "Marine Industry" 5 "Industrial" ;
VAL_ 2583625984 Manufacturer_Code 69 "ARKS Enterprises" 78 "FW Murphy/Enovation Controls" 80 "Twin Disc" 85 "Kohler Power Systems" 88 "Hemisphere GPS" 135 "Airmar" 137 "Maretron" 140 "Lowrance" 144 "Mercury Marine" 147 "Nautibus Electronic" 148 "Blue Water Data" 154 "Westerbeke" 157 "ISSPRO" 161 "Offshore Systems (UK)" 163 "Evinrude/BRP" 165 "CPAC Systems" 168 "Xantrex Technology" 169 "Marlin Technologies" 172 "Yanmar Marine" 174 "Volvo Penta" 176 "Carling Technologies Inc. (Moritz Aerospace)" 185 "Beede Instruments" 192 "Floscan Instrument" 193 "Nobeltec" 198 "Mystic Valley Communications" 199 "Actia" 201 "Disenos Y Technologia" 211 "Digital Switching Systems" 215 "Xintex/Atena" 224 "EMMI NETWORK" 228 "ZF" 229 "Garmin" 233 "Yacht Monitoring Solutions" 235 "Sailormade Marine Telemetry/Tetra Technology" 243 "Eride" 257 "Honda Motor" 272 "Groco" 273 "Actisense" 274 "Amphenol LTW Technology" 275 "Navico" 283 "Hamilton Jet" 285 "Sea Recovery" 286 "Coelmo SRL Italy" 295 "BEP Marine" 304 "Empir Bus" 305 "NovAtel" 306 "Sleipner Motor" 307 "MBW Technologies" 315 "ICOM" 328 "Qwerty" 329 "Dief" 341 "Boening Automationstechnologie" 345 "Korean Maritime University" 351 "Thrane and Thrane" 355 "Mastervolt" 356 "Fischer Panda Generators" 358 "Victron Energy" 370 "Rolls Royce Marine" 373 "Electronic Design" 374 "Northern Lights" 378 "Glendinning" 381 "B & G" 384 "Rose Point Navigation Systems" 385 "Johnson Outdoors Marine Electronics Inc Geonav" 394 "Capi 2" 396 "Beyond Measure" 400 "Livorsi Marine" 404 "ComNav" 409 "Chetco" 419 "Fusion Electronics" 421 "Standard Horizon" 422 "True Heading" 426 "Egersund Marine Electronics" 427 "em-trak Marine Electronics" 431 "Tohatsu Co, JP" 437 "Digital Yacht" 438 "Comar Systems Limited" 440 "Cummins" 443 "VDO (aka Continental-Corporation)" 451 "Parker Hannifin aka Village Marine Tech" 459 "Alltek Marine Electronics" 460 "SAN GIORGIO S.E.I.N" 466 "Veethree Electronics & Marine" 470 "SI-TEX Marine Electronics" 471 "Sea Cross Marine" 475 "GME aka Standard Communications" 476 "Humminbird Marine Electronics" 478 "Ocean Sat" 481 "Chetco Digital Instruments" 493 "Watcheye" 499 "Lcj Capteurs" 502 "Attwood Marine" 503 "Naviop S.R.L." 504 "Vesper Marine" 510 "Marinesoft" 513 "Simarine" 517 "NoLand Engineering" 518 "Transas USA" 529 "National Instruments Korea" 530 "National Marine Electronics Association" 532 "Onwa Marine" 540 "Webasto" 571 "Marinecraft (South Korea)" 573 "McMurdo Group aka Orolia" 578 "Advansea" 579 "KVH" 580 "San Jose Technology" 583 "Yacht Control" 586 "Suzuki Motor" 591 "US Coast Guard" 595 "Ship Module aka Customware" 600 "Aquatic AV" 605 "Aventics" 606 "Intellian" 612 "SamwonIT" 614 "Arlt Tecnologies" 637 "Bavaria Yachts" 641 "Diverse Yacht Services" 644 "Wema U.S.A dba KUS" 658 "Shenzhen Jiuzhou Himunication" 688 "Rockford" 699 "Harman International" 704 "JL Audio" 708 "Lars Thrane" 715 "Autonnic" 717 "Yacht Devices" 734 "REAP Systems" 735 "AEM Performance Electronics" 739 "LxNav" 741 "Littelfuse, Inc (formerly Carling Technologies)" 743 "DaeMyung" 744 "Woosung" 748 "ISOTTA IFRA srl" 773 "Clarion US" 776 "HMI Systems" 777 "Ocean Signal" 778 "Seakeeper" 781 "Poly Planar" 785 "Fischer Panda DE" 795 "Broyda Industries" 796 "Canadian Automotive" 797 "Tides Marine" 798 "Lumishore" 799 "Still Water Designs and Audio" 802 "BJ Technologies (Beneteau)" 803 "Gill Sensors" 811 "Blue Water Desalination" 815 "FLIR" 824 "Undheim Systems" 826 "Lewmar" 838 "TeamSurv" 844 "Fell Marine" 847 "Oceanvolt" 862 "Prospec" 868 "Data Panel" 890 "L3 Technologies" 894 "Rhodan Marine Systems" 896 "Nexfour Solutions" 905 "ASA Electronics" 909 "Marines Co (South Korea)" 911 "Nautic-on" 917 "Sentinel" 929 "JL Marine Systems" 930 "Ecotronix" 944 "Zontisa Marine" 951 "EXOR International" 962 "Timbolier Industries" 963 "TJC Micro" 968 "Cox Powertrain" 969 "Blue Seas" 981 "Kobelt Manufacturing" 992 "Blue Ocean IOT" 997 "Xenta Systems" 999 "Signal K" 1004 "Ultraflex" 1008 "Lintest SmartBoat" 1011 "Soundmax" 1020 "Team Italia Marine (Onyx Marine Automation s.r.l)" 1021 "Entratech" 1022 "ITC" 1029 "The Marine Guardian" 1047 "Sonic" 1051 "ProNav" 1053 "Vetus Maxwell INC." 1056 "Lithium Pros" 1059 "Boatrax" 1062 "Marol Co ltd" 1065 "CALYPSO Instruments" 1066 "Spot Zero Water" 1069 "Lithionics Battery" 1070 "Quick-teck Electronics" 1075 "Uniden America" 1083 "Nauticoncept" 1084 "Shadow-Caster LED lighting" 1085 "Wet Sounds" 1088 "E-T-A Circuit Breakers" 1092 "Scheiber" 1100 "Smart Yachts International Limited" 1109 "Dockmate" 1114 "Bobs Machine" 1118 "L3Harris ASV" 1119 "Balmar" 1120 "Elettromedia" 1127 "Electromaax" 1140 "Across Oceans Systems" 1145 "Kiwi Yachting" 1150 "BSB Artificial Intelligence" 1151 "Orca Technologies" 1154 "TBS Electronics" 1158 "Technoton Electroics" 1160 "MG Energy Systems" 1169 "Sea Machine Robotics" 1171 "Vista Manufacturing" 1183 "Zipwake" 1186 "Sailmon" 1192 "Airmoniq Pro Kft" 1194 "Sierra Marine" 1200 "Xinuo Information Technology (Xiamen)" 1218 "Septentrio" 1233 "NKE Marine Electronics" 1238 "SuperTrack Aps" 1239 "Honda Electronics" 1245 "Raritan Engineering" 1249 "Integrated Power Solutions AG" 1260 "Interactive Technologies" 1283 "LTG-Tech" 1299 "Energy Solutions (UK)" 1300 "WATT Fuel Cell" 1302 "Pro Mainer" 1305 "Dragonfly Energy" 1306 "Koden Electronics" 1311 "Humphree" 1316 "Hinkley Yachts" 1317 "Global Marine Management GmbH (GMM)" 1320 "Triskel Marine" 1330 "Warwick Control Technologies" 1331 "Dolphin Charger" 1337 "Barnacle Systems" 1348 "Radian IoT" 1353 "Ocean LED Marine" 1359 "BluNav" 1361 "OVA (Nantong Saiyang Electronics Co., Ltd)" 1368 "RAD Propulsion" 1369 "Electric Yacht" 1372 "Elco Motor Yachts" 1384 "Tecnoseal Foundry S.r.l" 1385 "Pro Charging Systems" 1389 "EVEX" 1398 "Gobius Sensor Technology" 1403 "Arco Marine" 1408 "Lenco Marine" 1413 "Naocontrol" 1417 "Revatek" 1438 "Aeolionics" 1439 "PredictWind" 1440 "Egis Mobile Electric" 1445 "Starboard Yacht Group" 1446 "Roswell Marine" 1451 "ePropulsion (Guangdong ePropulsion Technology Ltd.)" 1452 "Micro-Air" 1453 "Vital Battery" 1458 "Ride Controller" 1460 "Tocaro Blue" 1461 "Vanquish Yachts" 1471 "FT Technologies" 1478 "Alps Alpine" 1481 "E-Force Marine" 1482 "CMC Marine" 1483 "Nanjing Sandemarine Information Technology" 1850 "Teleflex Marine (SeaStar Solutions)" 1851 "Raymarine" 1852 "Navionics" 1853 "Japan Radio" 1854 "Northstar Technologies" 1855 "Furuno" 1856 "Trimble" 1857 "Simrad" 1858 "Litton" 1859 "Kvasar" 1860 "MMP" 1861 "Vector Cantech" 1862 "Yamaha Marine" 1863 "Faria Instruments" ;
VAL_ 2583625984 Industry_Code 0 "Global" 1 "Highway" 2 "Agriculture" 3 "Construction" 4 "Marine Industry" 5 "Industrial" ;
VAL_ 2583625984 Manufacturer_Code 69 "ARKS Enterprises" 78 "FW Murphy/Enovation Controls" 80 "Twin Disc" 85 "Kohler Power Systems" 88 "Hemisphere GPS" 135 "Airmar" 137 "Maretron" 140 "Lowrance" 144 "Mercury Marine" 147 "Nautibus Electronic" 148 "Blue Water Data" 154 "Westerbeke" 157 "ISSPRO" 161 "Offshore Systems (UK)" 163 "Evinrude/BRP" 165 "CPAC Systems" 168 "Xantrex Technology" 169 "Marlin Technologies" 172 "Yanmar Marine" 174 "Volvo Penta" 176 "Carling Technologies Inc. (Moritz Aerospace)" 185 "Beede Instruments" 192 "Floscan Instrument" 193 "Nobeltec" 198 "Mystic Valley Communications" 199 "Actia" 201 "Disenos Y Technologia" 211 "Digital Switching Systems" 215 "Xintex/Atena" 224 "EMMI NETWORK" 228 "ZF" 229 "Garmin" 233 "Yacht Monitoring Solutions" 235 "Sailormade Marine Telemetry/Tetra Technology" 243 "Eride" 257 "Honda Motor" 272 "Groco" 273 "Actisense" 274 "Amphenol LTW Technology" 275 "Navico" 283 "Hamilton Jet" 285 "Sea Recovery" 286 "Coelmo SRL Italy" 295 "BEP Marine" 304 "Empir Bus" 305 "NovAtel" 306 "Sleipner Motor" 307 "MBW Technologies" 315 "ICOM" 328 "Qwerty" 329 "Dief" 341 "Boening Automationstechnologie" 345 "Korean Maritime University" 351 "Thrane and Thrane" 355 "Mastervolt" 356 "Fischer Panda Generators" 358 "Victron Energy" 370 "Rolls Royce Marine" 373 "Electronic Design" 374 "Northern Lights" 378 "Glendinning" 381 "B & G" 384 "Rose Point Navigation Systems" 385 "Johnson Outdoors Marine Electronics Inc Geonav" 394 "Capi 2" 396 "Beyond Measure" 400 "Livorsi Marine" 404 "ComNav" 409 "Chetco" 419 "Fusion Electronics" 421 "Standard Horizon" 422 "True Heading" 426 "Egersund Marine Electronics" 427 "em-trak Marine Electronics" 431 "Tohatsu Co, JP" 437 "Digital Yacht" 438 "Comar Systems Limited" 440 "Cummins" 443 "VDO (aka Continental-Corporation)" 451 "Parker Hannifin aka Village Marine Tech" 459 "Alltek Marine Electronics" 460 "SAN GIORGIO S.E.I.N" 466 "Veethree Electronics & Marine" 470 "SI-TEX Marine Electronics" 471 "Sea Cross Marine" 475 "GME aka Standard Communications" 476 "Humminbird Marine Electronics" 478 "Ocean Sat" 481 "Chetco Digital Instruments" 493 "Watcheye" 499 "Lcj Capteurs" 502 "Attwood Marine" 503 "Naviop S.R.L." 504 "Vesper Marine" 510 "Marinesoft" 513 "Simarine" 517 "NoLand Engineering" 518 "Transas USA" 529 "National Instruments Korea" 530 "National Marine Electronics Association" 532 "Onwa Marine" 540 "Webasto" 571 "Marinecraft (South Korea)" 573 "McMurdo Group aka Orolia" 578 "Advansea" 579 "KVH" 580 "San Jose Technology" 583 "Yacht Control" 586 "Suzuki Motor" 591 "US Coast Guard" 595 "Ship Module aka Customware" 600 "Aquatic AV" 605 "Aventics" 606 "Intellian" 612 "SamwonIT" 614 "Arlt Tecnologies" 637 "Bavaria Yachts" 641 "Diverse Yacht Services" 644 "Wema U.S.A dba KUS" 658 "Shenzhen Jiuzhou Himunication" 688 "Rockford" 699 "Harman International" 704 "JL Audio" 708 "Lars Thrane" 715 "Autonnic" 717 "Yacht Devices" 734 "REAP Systems" 735 "AEM Performance Electronics" 739 "LxNav" 741 "Littelfuse, Inc (formerly Carling Technologies)" 743 "DaeMyung" 744 "Woosung" 748 "ISOTTA IFRA srl" 773 "Clarion US" 776 "HMI Systems" 777 "Ocean Signal" 778 "Seakeeper" 781 "Poly Planar" 785 "Fischer Panda DE" 795 "Broyda Industries" 796 "Canadian Automotive" 797 "Tides Marine" 798 "Lumishore" 799 "Still Water Designs and Audio" 802 "BJ Technologies (Beneteau)" 803 "Gill Sensors" 811 "Blue Water Desalination" 815 "FLIR" 824 "Undheim Systems" 826 "Lewmar" 838 "TeamSurv" 844 "Fell Marine" 847 "Oceanvolt" 862 "Prospec" 868 "Data Panel" 890 "L3 Technologies" 894 "Rhodan Marine Systems" 896 "Nexfour Solutions" 905 "ASA Electronics" 909 "Marines Co (South Korea)" 911 "Nautic-on" 917 "Sentinel" 929 "JL Marine Systems" 930 "Ecotronix" 944 "Zontisa Marine" 951 "EXOR International" 962 "Timbolier Industries" 963 "TJC Micro" 968 "Cox Powertrain" 969 "Blue Seas" 981 "Kobelt Manufacturing" 992 "Blue Ocean IOT" 997 "Xenta Systems" 999 "Signal K" 1004 "Ultraflex" 1008 "Lintest SmartBoat" 1011 "Soundmax" 1020 "Team Italia Marine (Onyx Marine Automation s.r.l)" 1021 "Entratech" 1022 "ITC" 1029 "The Marine Guardian" 1047 "Sonic" 1051 "ProNav" 1053 "Vetus Maxwell INC." 1056 "Lithium Pros" 1059 "Boatrax" 1062 "Marol Co ltd" 1065 "CALYPSO Instruments" 1066 "Spot Zero Water" 1069 "Lithionics Battery" 1070 "Quick-teck Electronics" 1075 "Uniden America" 1083 "Nauticoncept" 1084 "Shadow-Caster LED lighting" 1085 "Wet Sounds" 1088 "E-T-A Circuit Breakers" 1092 "Scheiber" 1100 "Smart Yachts International Limited" 1109 "Dockmate" 1114 "Bobs Machine" 1118 "L3Harris ASV" 1119 "Balmar" 1120 "Elettromedia" 1127 "Electromaax" 1140 "Across Oceans Systems" 1145 "Kiwi Yachting" 1150 "BSB Artificial Intelligence" 1151 "Orca Technologies" 1154 "TBS Electronics" 1158 "Technoton Electroics" 1160 "MG Energy Systems" 1169 "Sea Machine Robotics" 1171 "Vista Manufacturing" 1183 "Zipwake" 1186 "Sailmon" 1192 "Airmoniq Pro Kft" 1194 "Sierra Marine" 1200 "Xinuo Information Technology (Xiamen)" 1218 "Septentrio" 1233 "NKE Marine Electronics" 1238 "SuperTrack Aps" 1239 "Honda Electronics" 1245 "Raritan Engineering" 1249 "Integrated Power Solutions AG" 1260 "Interactive Technologies" 1283 "LTG-Tech" 1299 "Energy Solutions (UK)" 1300 "WATT Fuel Cell" 1302 "Pro Mainer" 1305 "Dragonfly Energy" 1306 "Koden Electronics" 1311 "Humphree" 1316 "Hinkley Yachts" 1317 "Global Marine Management GmbH (GMM)" 1320 "Triskel Marine" 1330 "Warwick Control Technologies" 1331 "Dolphin Charger" 1337 "Barnacle Systems" 1348 "Radian IoT" 1353 "Ocean LED Marine" 1359 "BluNav" 1361 "OVA (Nantong Saiyang Electronics Co., Ltd)" 1368 "RAD Propulsion" 1369 "Electric Yacht" 1372 "Elco Motor Yachts" 1384 "Tecnoseal Foundry S.r.l" 1385 "Pro Charging Systems" 1389 "EVEX" 1398 "Gobius Sensor Technology" 1403 "Arco Marine" 1408 "Lenco Marine" 1413 "Naocontrol" 1417 "Revatek" 1438 "Aeolionics" 1439 "PredictWind" 1440 "Egis Mobile Electric" 1445 "Starboard Yacht Group" 1446 "Roswell Marine" 1451 "ePropulsion (Guangdong ePropulsion Technology Ltd.)" 1452 "Micro-Air" 1453 "Vital Battery" 1458 "Ride Controller" 1460 "Tocaro Blue" 1461 "Vanquish Yachts" 1471 "FT Technologies" 1478 "Alps Alpine" 1481 "E-Force Marine" 1482 "CMC Marine" 1483 "Nanjing Sandemarine Information Technology" 1850 "Teleflex Marine (SeaStar Solutions)" 1851 "Raymarine" 1852 "Navionics" 1853 "Japan Radio" 1854 "Northstar Technologies" 1855 "Furuno" 1856 "Trimble" 1857 "Simrad" 1858 "Litton" 1859 "Kvasar" 1860 "MMP" 1861 "Vector Cantech" 1862 "Yamaha Marine" 1863 "Faria Instruments" ;
VAL_ 2583625984 Industry_Code 0 "Global" 1 "Highway" 2 "Agriculture" 3 "Construction" 4 "Marine Industry" 5 "Industrial" ;
VAL_ 2583625984 Manufacturer_Code 69 "ARKS Enterprises" 78 "FW Murphy/Enovation Controls" 80 "Twin Disc" 85 "Kohler Power Systems" 88 "Hemisphere GPS" 135 "Airmar" 137 "Maretron" 140 "Lowrance" 144 "Mercury Marine" 147 "Nautibus Electronic" 148 "Blue Water Data" 154 "Westerbeke" 157 "ISSPRO" 161 "Offshore Systems (UK)" 163 "Evinrude/BRP" 165 "CPAC Systems" 168 "Xantrex Technology" 169 "Marlin Technologies" 172 "Yanmar Marine" 174 "Volvo Penta" 176 "Carling Technologies Inc. (Moritz Aerospace)" 185 "Beede Instruments" 192 "Floscan Instrument" 193 "Nobeltec" 198 "Mystic Valley Communications" 199 "Actia" 201 "Disenos Y Technologia" 211 "Digital Switching Systems" 215 "Xintex/Atena" 224 "EMMI NETWORK" 228 "ZF" 229 "Garmin" 233 "Yacht Monitoring Solutions" 235 "Sailormade Marine Telemetry/Tetra Technology" 243 "Eride" 257 "Honda Motor" 272 "Groco" 273 "Actisense" 274 "Amphenol LTW Technology" 275 "Navico" 283 "Hamilton Jet" 285 "Sea Recovery" 286 "Coelmo SRL Italy" 295 "BEP Marine" 304 "Empir Bus" 305 "NovAtel" 306 "Sleipner Motor" 307 "MBW Technologies" 315 "ICOM" 328 "Qwerty" 329 "Dief" 341 "Boening Automationstechnologie" 345 "Korean Maritime University" 351 "Thrane and Thrane" 355 "Mastervolt" 356 "Fischer Panda Generators" 358 "Victron Energy" 370 "Rolls Royce Marine" 373 "Electronic Design" 374 "Northern Lights" 378 "Glendinning" 381 "B & G" 384 "Rose Point Navigation Systems" 385 "Johnson Outdoors Marine Electronics Inc Geonav" 394 "Capi 2" 396 "Beyond Measure" 400 "Livorsi Marine" 404 "ComNav" 409 "Chetco" 419 "Fusion Electronics" 421 "Standard Horizon" 422 "True Heading" 426 "Egersund Marine Electronics" 427 "em-trak Marine Electronics" 431 "Tohatsu Co, JP" 437 "Digital Yacht" 438 "Comar Systems Limited" 440 "Cummins" 443 "VDO (aka Continental-Corporation)" 451 "Parker Hannifin aka Village Marine Tech" 459 "Alltek Marine Electronics" 460 "SAN GIORGIO S.E.I.N" 466 "Veethree Electronics & Marine" 470 "SI-TEX Marine Electronics" 471 "Sea Cross Marine" 475 "GME aka Standard Communications" 476 "Humminbird Marine Electronics" 478 "Ocean Sat" 481 "Chetco Digital Instruments" 493 "Watcheye" 499 "Lcj Capteurs" 502 "Attwood Marine" 503 "Naviop S.R.L." 504 "Vesper Marine" 510 "Marinesoft" 513 "Simarine" 517 "NoLand Engineering" 518 "Transas USA" 529 "National Instruments Korea" 530 "National Marine Electronics Association" 532 "Onwa Marine" 540 "Webasto" 571 "Marinecraft (South Korea)" 573 "McMurdo Group aka Orolia" 578 "Advansea" 579 "KVH" 580 "San Jose Technology" 583 "Yacht Control" 586 "Suzuki Motor" 591 "US Coast Guard" 595 "Ship Module aka Customware" 600 "Aquatic AV" 605 "Aventics" 606 "Intellian" 612 "SamwonIT" 614 "Arlt Tecnologies" 637 "Bavaria Yachts" 641 "Diverse Yacht Services" 644 "Wema U.S.A dba KUS" 658 "Shenzhen Jiuzhou Himunication" 688 "Rockford" 699 "Harman International" 704 "JL Audio" 708 "Lars Thrane" 715 "Autonnic" 717 "Yacht Devices" 734 "REAP Systems" 735 "AEM Performance Electronics" 739 "LxNav" 741 "Littelfuse, Inc (formerly Carling Technologies)" 743 "DaeMyung" 744 "Woosung" 748 "ISOTTA IFRA srl" 773 "Clarion US" 776 "HMI Systems" 777 "Ocean Signal" 778 "Seakeeper" 781 "Poly Planar" 785 "Fischer Panda DE" 795 "Broyda Industries" 796 "Canadian Automotive" 797 "Tides Marine" 798 "Lumishore" 799 "Still Water Designs and Audio" 802 "BJ Technologies (Beneteau)" 803 "Gill Sensors" 811 "Blue Water Desalination" 815 "FLIR" 824 "Undheim Systems" 826 "Lewmar" 838 "TeamSurv" 844 "Fell Marine" 847 "Oceanvolt" 862 "Prospec" 868 "Data Panel" 890 "L3 Technologies" 894 "Rhodan Marine Systems" 896 "Nexfour Solutions" 905 "ASA Electronics" 909 "Marines Co (South Korea)" 911 "Nautic-on" 917 "Sentinel" 929 "JL Marine Systems" 930 "Ecotronix" 944 "Zontisa Marine" 951 "EXOR International" 962 "Timbolier Industries" 963 "TJC Micro" 968 "Cox Powertrain" 969 "Blue Seas" 981 "Kobelt Manufacturing" 992 "Blue Ocean IOT" 997 "Xenta Systems" 999 "Signal K" 1004 "Ultraflex" 1008 "Lintest SmartBoat" 1011 "Soundmax" 1020 "Team Italia Marine (Onyx Marine Automation s.r.l)" 1021 "Entratech" 1022 "ITC" 1029 "The Marine Guardian" 1047 "Sonic" 1051 "ProNav" 1053 "Vetus Maxwell INC." 1056 "Lithium Pros" 1059 "Boatrax" 1062 "Marol Co ltd" 1065 "CALYPSO Instruments" 1066 "Spot Zero Water" 1069 "Lithionics Battery" 1070 "Quick-teck Electronics" 1075 "Uniden America" 1083 "Nauticoncept" 1084 "Shadow-Caster LED lighting" 1085 "Wet Sounds" 1088 "E-T-A Circuit Breakers" 1092 "Scheiber" 1100 "Smart Yachts International Limited" 1109 "Dockmate" 1114 "Bobs Machine" 1118 "L3Harris ASV" 1119 "Balmar" 1120 "Elettromedia" 1127 "Electromaax" 1140 "Across Oceans Systems" 1145 "Kiwi Yachting" 1150 "BSB Artificial Intelligence" 1151 "Orca Technologies" 1154 "TBS Electronics" 1158 "Technoton Electroics" 1160 "MG Energy Systems" 1169 "Sea Machine Robotics" 1171 "Vista Manufacturing" 1183 "Zipwake" 1186 "Sailmon" 1192 "Airmoniq Pro Kft" 1194 "Sierra Marine" 1200 "Xinuo Information Technology (Xiamen)" 1218 "Septentrio" 1233 "NKE Marine Electronics" 1238 "SuperTrack Aps" 1239 "Honda Electronics" 1245 "Raritan Engineering" 1249 "Integrated Power Solutions AG" 1260 "Interactive Technologies" 1283 "LTG-Tech" 1299 "Energy Solutions (UK)" 1300 "WATT Fuel Cell" 1302 "Pro Mainer" 1305 "Dragonfly Energy" 1306 "Koden Electronics" 1311 "Humphree" 1316 "Hinkley Yachts" 1317 "Global Marine Management GmbH (GMM)" 1320 "Triskel Marine" 1330 "Warwick Control Technologies" 1331 "Dolphin Charger" 1337 "Barnacle Systems" 1348 "Radian IoT" 1353 "Ocean LED Marine" 1359 "BluNav" 1361 "OVA (Nantong Saiyang Electronics Co., Ltd)" 1368 "RAD Propulsion" 1369 "Electric Yacht" 1372 "Elco Motor Yachts" 1384 "Tecnoseal Foundry S.r.l" 1385 "Pro Charging Systems" 1389 "EVEX" 1398 "Gobius Sensor Technology" 1403 "Arco Marine" 1408 "Lenco Marine" 1413 "Naocontrol" 1417 "Revatek" 1438 "Aeolionics" 1439 "PredictWind" 1440 "Egis Mobile Electric" 1445 "Starboard Yacht Group" 1446 "Roswell Marine" 1451 "ePropulsion (Guangdong ePropulsion Technology Ltd.)" 1452 "Micro-Air" 1453 "Vital Battery" 1458 "Ride Controller" 1460 "Tocaro Blue" 1461 "Vanquish Yachts" 1471 "FT Technologies" 1478 "Alps Alpine" 1481 "E-Force Marine" 1482 "CMC Marine" 1483 "Nanjing Sandemarine Information Technology" 1850 "Teleflex Marine (SeaStar Solutions)" 1851 "Raymarine" 1852 "Navionics" 1853 "Japan Radio" 1854 "Northstar Technologies" 1855 "Furuno" 1856 "Trimble" 1857 "Simrad" 1858 "Litton" 1859 "Kvasar" 1860 "MMP" 1861 "Vector Cantech" 1862 "Yamaha Marine" 1863 "Faria Instruments" ;
VAL_ 2583625984 Industry_Code 0 "Global" 1 "Highway" 2 "Agriculture" 3 "Construction" 4 "Marine Industry" 5 "Industrial" ;
CM_ SG_ 2650734592 Status "STRING field: decode bytes as ASCII (0x00/@/0xFF = terminator); canboat type: STRING_LAU";
CM_ SG_ 2650734592 Text "STRING field: decode bytes as ASCII (0x00/@/0xFF = terminator); canboat type: STRING_FIX";

BA_DEF_ BO_ "GenMsgCycleTime" INT 0 60000;
BA_DEF_ BO_ "ProtocolType" STRING;

BA_DEF_ BO_ "J1939PGN" INT 0 262143;
BA_ "J1939PGN" BO_ 2650734592 130816;
BA_ "J1939PGN" BO_ 2650734592 130816;
BA_ "J1939PGN" BO_ 2650734592 130816;
BA_ "J1939PGN" BO_ 2650734592 130816;
BA_ "J1939PGN" BO_ 2650734592 130816;
BA_ "J1939PGN" BO_ 2650734592 130816;
BA_ "J1939PGN" BO_ 2650734592 130816;
BA_ "J1939PGN" BO_ 2650734592 130816;
BA_ "J1939PGN" BO_ 2650734592 130816;
BA_ "J1939PGN" BO_ 2650734592 130816;
BA_ "J1939PGN" BO_ 2650734592 130816;
BA_ "J1939PGN" BO_ 2650734592 130816;
BA_ "J1939PGN" BO_ 2650734592 130816;
BA_ "J1939PGN" BO_ 2650734592 130816;
BA_ "J1939PGN" BO_ 2650734592 130816;
BA_ "J1939PGN" BO_ 2650734592 130816;
BA_ "J1939PGN" BO_ 2650734592 130816;
BA_ "J1939PGN" BO_ 2650734592 130816;
BA_ "J1939PGN" BO_ 2650734592 130816;
BA_ "J1939PGN" BO_ 2650734592 130816;
BA_ "J1939PGN" BO_ 2583625984 130817;
BA_ "J1939PGN" BO_ 2583625984 130817;
BA_ "J1939PGN" BO_ 2583625984 130817;
BA_ "J1939PGN" BO_ 2583625984 130817;
